VERSION ""

NS_ :

BS_:

BU_: EBS EMS

BO_ 3221225472 VECTOR__INDEPENDENT_SIG_MSG: 0 Vector__XXX
 SG_ RedStopLampState : 0|2@1+ (1,0) [0|3] "" Vector__XXX
 SG_ AmberWarningLampStatus : 0|2@1+ (1,0) [0|3] "" Vector__XXX
 SG_ ProtectLampStatus : 0|2@1+ (1,0) [0|3] "" Vector__XXX
 SG_ DTC5 : 0|32@1+ (1,0) [0|4294967295] "" Vector__XXX
 SG_ DTC4 : 0|32@1+ (1,0) [0|4294967295] "" Vector__XXX
 SG_ DTC3 : 0|32@1+ (1,0) [0|4294967295] "" Vector__XXX
 SG_ DTC2 : 0|32@1+ (1,0) [0|4294967295] "" Vector__XXX
 SG_ UtlityOverallPowerFactorLagging : 0|2@1+ (1,0) [0|3] "" Vector__XXX
 SG_ UtilityOverallPowerFactor : 0|16@1+ (1,-1) [-1|2.92181] "" Vector__XXX
 SG_ UtilityTotalReactivePower : 0|32@1+ (1,-2000000000) [-2000000000|2211081215] "VA" Vector__XXX
 SG_ UtilityTotalApparentPower : 0|32@1+ (1,-2000000000) [-2000000000|2211081215] "VA" Vector__XXX
 SG_ UtilityTotalRealPower : 0|32@1+ (1,-2000000000) [-2000000000|2211081215] "VA" Vector__XXX
 SG_ UtilityTotalKWHoursImport : 0|32@1+ (1,0) [0|4211081215] "kWh" Vector__XXX
 SG_ UtilityTotalKWHoursExport : 0|32@1+ (1,0) [0|4211081215] "kWh" Vector__XXX
 SG_ UtilityPhaseCPowerFactorLagging : 0|2@1+ (1,0) [0|3] "" Vector__XXX
 SG_ UtilityPhaseCPowerFactor : 0|16@1+ (1,-1) [-1|2.92181] "" Vector__XXX
 SG_ UtilityPhaseCReactivePower : 0|32@1+ (1,-2000000000) [-2000000000|2211081215] "VA" Vector__XXX
 SG_ UtilityPhaseCApparentPower : 0|32@1+ (1,-2000000000) [-2000000000|2211081215] "VA" Vector__XXX
 SG_ UtilityPhaseCRealPower : 0|32@1+ (1,-2000000000) [-2000000000|2211081215] "VA" Vector__XXX
 SG_ UtilityPhaseCACRMSCurrent : 0|16@1+ (1,0) [0|64255] "A" Vector__XXX
 SG_ UtilityPhaseCACFrequency : 0|16@1+ (1,0) [0|501.9921875] "Hz" Vector__XXX
 SG_ UtltyPhsCLneNeutralACRMSVoltage : 0|16@1+ (1,0) [0|64255] "V" Vector__XXX
 SG_ UtltyPhseCALineLineACRMSVoltage : 0|16@1+ (1,0) [0|64255] "V" Vector__XXX
 SG_ UtilityPhaseBPowerFactorLagging : 0|2@1+ (1,0) [0|3] "" Vector__XXX
 SG_ UtilityPhaseBPowerFactor : 0|16@1+ (1,-1) [-1|2.92181] "" Vector__XXX
 SG_ UtilityPhaseBReactivePower : 0|32@1+ (1,-2000000000) [-2000000000|2211081215] "VA" Vector__XXX
 SG_ UtilityPhaseBApparentPower : 0|32@1+ (1,-2000000000) [-2000000000|2211081215] "VA" Vector__XXX
 SG_ UtilityPhaseBRealPower : 0|32@1+ (1,-2000000000) [-2000000000|2211081215] "VA" Vector__XXX
 SG_ UtilityPhaseBACRMSCurrent : 0|16@1+ (1,0) [0|64255] "A" Vector__XXX
 SG_ UtilityPhaseBACFrequency : 0|16@1+ (1,0) [0|501.9921875] "Hz" Vector__XXX
 SG_ UtltyPhsBLneNeutralACRMSVoltage : 0|16@1+ (1,0) [0|64255] "V" Vector__XXX
 SG_ UtltyPhseBCLineLineACRMSVoltage : 0|16@1+ (1,0) [0|64255] "V" Vector__XXX
 SG_ UtilityPhaseAPowerFactorLagging : 0|2@1+ (1,0) [0|3] "" Vector__XXX
 SG_ UtilityPhaseAPowerFactor : 0|16@1+ (1,-1) [-1|2.92181] "" Vector__XXX
 SG_ UtilityPhaseAReactivePower : 0|32@1+ (1,-2000000000) [-2000000000|2211081215] "VA" Vector__XXX
 SG_ UtilityPhaseAApparentPower : 0|32@1+ (1,-2000000000) [-2000000000|2211081215] "VA" Vector__XXX
 SG_ UtilityPhaseARealPower : 0|32@1+ (1,-2000000000) [-2000000000|2211081215] "VA" Vector__XXX
 SG_ UtilityPhaseAACRMSCurrent : 0|16@1+ (1,0) [0|64255] "A" Vector__XXX
 SG_ UtilityPhaseAACFrequency : 0|16@1+ (1,0) [0|501.9921875] "Hz" Vector__XXX
 SG_ UtltyPhsALneNeutralACRMSVoltage : 0|16@1+ (1,0) [0|64255] "V" Vector__XXX
 SG_ UtltyPhseABLineLineACRMSVoltage : 0|16@1+ (1,0) [0|64255] "V" Vector__XXX
 SG_ UtilityAverageACRMSCurrent : 0|16@1+ (1,0) [0|64255] "A" Vector__XXX
 SG_ UtilityAverageACFrequency : 0|16@1+ (1,0) [0|501.9921875] "Hz" Vector__XXX
 SG_ UtltyAvrgLneNeutralACRMSVoltage : 0|16@1+ (1,0) [0|64255] "V" Vector__XXX
 SG_ UtltyAvrageLineLineACRMSVoltage : 0|16@1+ (1,0) [0|64255] "V" Vector__XXX
 SG_ GnrtorOverallPowerFactorLagging : 0|2@1+ (1,0) [0|3] "" Vector__XXX
 SG_ GeneratorOverallPowerFactor : 0|16@1+ (1,-1) [-1|2.92181] "" Vector__XXX
 SG_ GeneratorTotalReactivePower : 0|32@1+ (1,-2000000000) [-2000000000|2211081215] "VA" Vector__XXX
 SG_ GeneratorTotalApparentPower : 0|32@1+ (1,-2000000000) [-2000000000|2211081215] "VA" Vector__XXX
 SG_ GeneratorTotalRealPower : 0|32@1+ (1,-2000000000) [-2000000000|2211081215] "VA" Vector__XXX
 SG_ GeneratorTotalKWHoursImport : 0|32@1+ (1,0) [0|4211081215] "kWh" Vector__XXX
 SG_ GeneratorTotalKWHoursExport : 0|32@1+ (1,0) [0|4211081215] "kWh" Vector__XXX
 SG_ GnratorPhaseCPowerFactorLagging : 0|2@1+ (1,0) [0|3] "" Vector__XXX
 SG_ GeneratorPhaseCPowerFactor : 0|16@1+ (1,-1) [-1|2.92181] "" Vector__XXX
 SG_ GeneratorPhaseCReactivePower : 0|32@1+ (1,-2000000000) [-2000000000|2211081215] "VA" Vector__XXX
 SG_ GeneratorPhaseCApparentPower : 0|32@1+ (1,-2000000000) [-2000000000|2211081215] "VA" Vector__XXX
 SG_ GeneratorPhaseCRealPower : 0|32@1+ (1,-2000000000) [-2000000000|2211081215] "VA" Vector__XXX
 SG_ GeneratorPhaseCACRMSCurrent : 0|16@1+ (1,0) [0|64255] "A" Vector__XXX
 SG_ GeneratorPhaseCACFrequency : 0|16@1+ (1,0) [0|501.9921875] "Hz" Vector__XXX
 SG_ GnrtrPhsCLneNeutralACRMSVoltage : 0|16@1+ (1,0) [0|64255] "V" Vector__XXX
 SG_ GnrtrPhseCALineLineACRMSVoltage : 0|16@1+ (1,0) [0|64255] "V" Vector__XXX
 SG_ GnratorPhaseBPowerFactorLagging : 0|2@1+ (1,0) [0|3] "" Vector__XXX
 SG_ GeneratorPhaseBPowerFactor : 0|16@1+ (1,-1) [-1|2.92181] "" Vector__XXX
 SG_ GeneratorPhaseBReactivePower : 0|32@1+ (1,-2000000000) [-2000000000|2211081215] "VA" Vector__XXX
 SG_ GeneratorPhaseBApparentPower : 0|32@1+ (1,-2000000000) [-2000000000|2211081215] "VA" Vector__XXX
 SG_ GeneratorPhaseBRealPower : 0|32@1+ (1,-2000000000) [-2000000000|2211081215] "VA" Vector__XXX
 SG_ GeneratorPhaseBACRMSCurrent : 0|16@1+ (1,0) [0|64255] "A" Vector__XXX
 SG_ GeneratorPhaseBACFrequency : 0|16@1+ (1,0) [0|501.9921875] "Hz" Vector__XXX
 SG_ GnrtrPhsBLneNeutralACRMSVoltage : 0|16@1+ (1,0) [0|64255] "V" Vector__XXX
 SG_ GnrtrPhseBCLineLineACRMSVoltage : 0|16@1+ (1,0) [0|64255] "V" Vector__XXX
 SG_ GnratorPhaseAPowerFactorLagging : 0|2@1+ (1,0) [0|3] "" Vector__XXX
 SG_ GeneratorPhaseAPowerFactor : 0|16@1+ (1,-1) [-1|2.92181] "" Vector__XXX
 SG_ GeneratorPhaseAReactivePower : 0|32@1+ (1,-2000000000) [-2000000000|2211081215] "VA" Vector__XXX
 SG_ GeneratorPhaseAApparentPower : 0|32@1+ (1,-2000000000) [-2000000000|2211081215] "VA" Vector__XXX
 SG_ GeneratorPhaseARealPower : 0|32@1+ (1,-2000000000) [-2000000000|2211081215] "VA" Vector__XXX
 SG_ GeneratorPhaseAACRMSCurrent : 0|16@1+ (1,0) [0|64255] "A" Vector__XXX
 SG_ GeneratorPhaseAACFrequency : 0|16@1+ (1,0) [0|501.9921875] "Hz" Vector__XXX
 SG_ GnrtrPhsALneNeutralACRMSVoltage : 0|16@1+ (1,0) [0|64255] "V" Vector__XXX
 SG_ GnrtrPhseABLineLineACRMSVoltage : 0|16@1+ (1,0) [0|64255] "V" Vector__XXX
 SG_ GeneratorAverageACRMSCurrent : 0|16@1+ (1,0) [0|64255] "A" Vector__XXX
 SG_ GeneratorAverageACFrequency : 0|16@1+ (1,0) [0|501.9921875] "Hz" Vector__XXX
 SG_ GnrtrAvrgLneNeutralACRMSVoltage : 0|16@1+ (1,0) [0|64255] "V" Vector__XXX
 SG_ GnrtrAvrageLineLineACRMSVoltage : 0|16@1+ (1,0) [0|64255] "V" Vector__XXX
 SG_ Bus1_UtilityACPhaseDifference : 0|16@1+ (1,-200) [-200|301.99] "deg" Vector__XXX
 SG_ Bus1_UtilityInSync : 0|2@1+ (1,0) [0|3] "" Vector__XXX
 SG_ Bus1_UtilityVoltageMatch : 0|2@1+ (1,0) [0|3] "" Vector__XXX
 SG_ Bus1_UtilityFrequencyMatch : 0|2@1+ (1,0) [0|3] "" Vector__XXX
 SG_ Bus1_UtilityPhaseMatch : 0|2@1+ (1,0) [0|3] "" Vector__XXX
 SG_ Bus1_UtilityDeadBus : 0|2@1+ (1,0) [0|3] "" Vector__XXX
 SG_ Bus1PhaseCACFrequency : 0|16@1+ (1,0) [0|501.9921875] "Hz" Vector__XXX
 SG_ Bs1PhseCLineNeutralACRMSVoltage : 0|16@1+ (1,0) [0|64255] "V" Vector__XXX
 SG_ Bus1PhaseCALineLineACRMSVoltage : 0|16@1+ (1,0) [0|64255] "V" Vector__XXX
 SG_ Bus1PhaseBACFrequency : 0|16@1+ (1,0) [0|501.9921875] "Hz" Vector__XXX
 SG_ Bs1PhseBLineNeutralACRMSVoltage : 0|16@1+ (1,0) [0|64255] "V" Vector__XXX
 SG_ Bus1PhaseBCLineLineACRMSVoltage : 0|16@1+ (1,0) [0|64255] "V" Vector__XXX
 SG_ Bus1PhaseAACFrequency : 0|16@1+ (1,0) [0|501.9921875] "Hz" Vector__XXX
 SG_ Bs1PhseALineNeutralACRMSVoltage : 0|16@1+ (1,0) [0|64255] "V" Vector__XXX
 SG_ Bus1PhaseABLineLineACRMSVoltage : 0|16@1+ (1,0) [0|64255] "V" Vector__XXX
 SG_ Bus1_GeneratorACPhaseDifference : 0|16@1+ (1,-200) [-200|301.99] "deg" Vector__XXX
 SG_ Bus1_GeneratorInSync : 0|2@1+ (1,0) [0|3] "" Vector__XXX
 SG_ Bus1_GeneratorVoltageMatch : 0|2@1+ (1,0) [0|3] "" Vector__XXX
 SG_ Bus1_GeneratorFrequencyMatch : 0|2@1+ (1,0) [0|3] "" Vector__XXX
 SG_ Bus1_GeneratorPhaseMatch : 0|2@1+ (1,0) [0|3] "" Vector__XXX
 SG_ Bus1_GeneratorDeadBus : 0|2@1+ (1,0) [0|3] "" Vector__XXX
 SG_ Bus1AverageACFrequency : 0|16@1+ (1,0) [0|501.9921875] "Hz" Vector__XXX
 SG_ Bs1AvrgeLineNeutralACRMSVoltage : 0|16@1+ (1,0) [0|64255] "V" Vector__XXX
 SG_ Bus1AverageLineLineACRMSVoltage : 0|16@1+ (1,0) [0|64255] "V" Vector__XXX
 SG_ NumberOfMembers : 0|8@1+ (1,0) [0|0] "" Vector__XXX
 SG_ AddressAssignment : 0|8@1+ (1,0) [0|255] "" Vector__XXX
 SG_ ArbitraryAddressCapable : 0|1@1+ (1,0) [0|1] "" Vector__XXX
 SG_ IndustryGroup : 0|3@1+ (1,0) [0|7] "" Vector__XXX
 SG_ VehicleSystemInstance : 0|4@1+ (1,0) [0|15] "" Vector__XXX
 SG_ Function : 0|8@1+ (1,0) [0|255] "" Vector__XXX
 SG_ VehicleSystem : 0|7@1+ (1,0) [0|127] "" Vector__XXX
 SG_ FunctionInstance : 0|5@1+ (1,0) [0|31] "" Vector__XXX
 SG_ ECUInstance : 0|3@1+ (1,0) [0|7] "" Vector__XXX
 SG_ ManufacturerCode : 0|11@1+ (1,0) [0|2047] "" Vector__XXX
 SG_ IdentityNumber : 0|21@1+ (1,0) [0|2097152] "" Vector__XXX
 SG_ VehicleSystem5 : 0|7@1+ (1,0) [0|127] "" Vector__XXX
 SG_ VehicleSystem4 : 0|7@1+ (1,0) [0|127] "" Vector__XXX
 SG_ VehicleSystem3 : 0|7@1+ (1,0) [0|127] "" Vector__XXX
 SG_ VehicleSystem2 : 0|7@1+ (1,0) [0|127] "" Vector__XXX
 SG_ VehicleSystem1 : 0|7@1+ (1,0) [0|127] "" Vector__XXX
 SG_ AxleGroupWeight : 0|16@1+ (2,0) [0|128510] "kg" Vector__XXX
 SG_ AxleGroupLocation : 0|4@1+ (1,0) [0|15] "" Vector__XXX
 SG_ AxleGroupFullWeightCalib : 0|16@1+ (2,0) [0|128510] "kg" Vector__XXX
 SG_ AxleGroupEmptyWeightCalib : 0|16@1+ (2,0) [0|128510] "kg" Vector__XXX
 SG_ AxleGroupLocation : 0|4@1+ (1,0) [0|15] "" Vector__XXX
 SG_ DsrdAftrclrClntThrmostatOpening : 0|8@1+ (0.4,0) [0|100] "%" Vector__XXX
 SG_ DsrdAftercoolerCoolantInletTemp : 0|8@1+ (1,-40) [-40|210] "deg" Vector__XXX
 SG_ AftrcoolerCoolantThermostatMode : 0|2@1+ (1,0) [0|3] "" Vector__XXX
 SG_ AddtnlTrlrAxlGrpWeightAvailable : 0|2@1+ (1,0) [0|3] "" Vector__XXX
 SG_ TrilerHAxleGroupWeightAvailable : 0|2@1+ (1,0) [0|3] "" Vector__XXX
 SG_ TrilerGAxleGroupWeightAvailable : 0|2@1+ (1,0) [0|3] "" Vector__XXX
 SG_ TrilerFAxleGroupWeightAvailable : 0|2@1+ (1,0) [0|3] "" Vector__XXX
 SG_ TrilerEAxleGroupWeightAvailable : 0|2@1+ (1,0) [0|3] "" Vector__XXX
 SG_ TrilerDAxleGroupWeightAvailable : 0|2@1+ (1,0) [0|3] "" Vector__XXX
 SG_ TrilerCAxleGroupWeightAvailable : 0|2@1+ (1,0) [0|3] "" Vector__XXX
 SG_ TrilerBAxleGroupWeightAvailable : 0|2@1+ (1,0) [0|3] "" Vector__XXX
 SG_ TrilerAAxleGroupWeightAvailable : 0|2@1+ (1,0) [0|3] "" Vector__XXX
 SG_ AddtnlTrctrAxlGrpWightAvailable : 0|2@1+ (1,0) [0|3] "" Vector__XXX
 SG_ TagAxleGroupWeightAvailable : 0|2@1+ (1,0) [0|3] "" Vector__XXX
 SG_ DriveAxleGroupWeightAvailable : 0|2@1+ (1,0) [0|3] "" Vector__XXX
 SG_ LiftAxleGroupWeightAvailable : 0|2@1+ (1,0) [0|3] "" Vector__XXX
 SG_ SteerAxleGroupWeightAvailable : 0|2@1+ (1,0) [0|3] "" Vector__XXX
 SG_ AmberWarningLampStatus : 0|2@1+ (1,0) [0|3] "" Vector__XXX
 SG_ RedStopLampState : 0|2@1+ (1,0) [0|3] "" Vector__XXX
 SG_ ProtectLampStatus : 0|2@1+ (1,0) [0|3] "" Vector__XXX
 SG_ DTC5 : 0|32@1+ (1,0) [0|4294967295] "" Vector__XXX
 SG_ DTC4 : 0|32@1+ (1,0) [0|4294967295] "" Vector__XXX
 SG_ DTC3 : 0|32@1+ (1,0) [0|4294967295] "" Vector__XXX
 SG_ DTC2 : 0|32@1+ (1,0) [0|4294967295] "" Vector__XXX
 SG_ AmberWarningLampStatus : 0|2@1+ (1,0) [0|3] "" Vector__XXX
 SG_ RedStopLampState : 0|2@1+ (1,0) [0|3] "" Vector__XXX
 SG_ ProtectLampStatus : 0|2@1+ (1,0) [0|3] "" Vector__XXX
 SG_ DTC5 : 0|32@1+ (1,0) [0|4294967295] "" Vector__XXX
 SG_ DTC4 : 0|32@1+ (1,0) [0|4294967295] "" Vector__XXX
 SG_ DTC3 : 0|32@1+ (1,0) [0|4294967295] "" Vector__XXX
 SG_ DTC2 : 0|32@1+ (1,0) [0|4294967295] "" Vector__XXX
 SG_ AmberWarningLampStatus : 0|2@1+ (1,0) [0|3] "" Vector__XXX
 SG_ RedStopLampState : 0|2@1+ (1,0) [0|3] "" Vector__XXX
 SG_ ProtectLampStatus : 0|2@1+ (1,0) [0|3] "" Vector__XXX
 SG_ DTC5 : 0|32@1+ (1,0) [0|4294967295] "" Vector__XXX
 SG_ DTC4 : 0|32@1+ (1,0) [0|4294967295] "" Vector__XXX
 SG_ DTC3 : 0|32@1+ (1,0) [0|4294967295] "" Vector__XXX
 SG_ DTC2 : 0|32@1+ (1,0) [0|4294967295] "" Vector__XXX
 SG_ AmberWarningLampStatus : 0|2@1+ (1,0) [0|3] "" Vector__XXX
 SG_ RedStopLampState : 0|2@1+ (1,0) [0|3] "" Vector__XXX
 SG_ ProtectLampStatus : 0|2@1+ (1,0) [0|3] "" Vector__XXX
 SG_ DTC5 : 0|32@1+ (1,0) [0|4294967295] "" Vector__XXX
 SG_ DTC4 : 0|32@1+ (1,0) [0|4294967295] "" Vector__XXX
 SG_ DTC3 : 0|32@1+ (1,0) [0|4294967295] "" Vector__XXX
 SG_ DTC2 : 0|32@1+ (1,0) [0|4294967295] "" Vector__XXX
 SG_ AmberWarningLampStatus : 0|2@1+ (1,0) [0|3] "" Vector__XXX
 SG_ RedStopLampState : 0|2@1+ (1,0) [0|3] "" Vector__XXX
 SG_ ProtectLampStatus : 0|2@1+ (1,0) [0|3] "" Vector__XXX
 SG_ DTC5 : 0|32@1+ (1,0) [0|4294967295] "" Vector__XXX
 SG_ DTC4 : 0|32@1+ (1,0) [0|4294967295] "" Vector__XXX
 SG_ DTC3 : 0|32@1+ (1,0) [0|4294967295] "" Vector__XXX
 SG_ DTC2 : 0|32@1+ (1,0) [0|4294967295] "" Vector__XXX
 SG_ AmberWarningLampStatus : 0|2@1+ (1,0) [0|3] "" Vector__XXX
 SG_ RedStopLampState : 0|2@1+ (1,0) [0|3] "" Vector__XXX
 SG_ ProtectLampStatus : 0|2@1+ (1,0) [0|3] "" Vector__XXX
 SG_ DTC5 : 0|32@1+ (1,0) [0|4294967295] "" Vector__XXX
 SG_ DTC4 : 0|32@1+ (1,0) [0|4294967295] "" Vector__XXX
 SG_ DTC3 : 0|32@1+ (1,0) [0|4294967295] "" Vector__XXX
 SG_ DTC2 : 0|32@1+ (1,0) [0|4294967295] "" Vector__XXX
 SG_ AmberWarningLampStatus : 0|2@1+ (1,0) [0|3] "" Vector__XXX
 SG_ RedStopLampState : 0|2@1+ (1,0) [0|3] "" Vector__XXX
 SG_ ProtectLampStatus : 0|2@1+ (1,0) [0|3] "" Vector__XXX
 SG_ DTC5 : 0|32@1+ (1,0) [0|4294967295] "" Vector__XXX
 SG_ DTC4 : 0|32@1+ (1,0) [0|4294967295] "" Vector__XXX
 SG_ DTC3 : 0|32@1+ (1,0) [0|4294967295] "" Vector__XXX
 SG_ DTC2 : 0|32@1+ (1,0) [0|4294967295] "" Vector__XXX
 SG_ AmberWarningLampStatus : 0|2@1+ (1,0) [0|3] "" Vector__XXX
 SG_ RedStopLampState : 0|2@1+ (1,0) [0|3] "" Vector__XXX
 SG_ ProtectLampStatus : 0|2@1+ (1,0) [0|3] "" Vector__XXX
 SG_ DTC5 : 0|32@1+ (1,0) [0|4294967295] "" Vector__XXX
 SG_ DTC4 : 0|32@1+ (1,0) [0|4294967295] "" Vector__XXX
 SG_ DTC3 : 0|32@1+ (1,0) [0|4294967295] "" Vector__XXX
 SG_ DTC2 : 0|32@1+ (1,0) [0|4294967295] "" Vector__XXX
 SG_ AmberWarningLampStatus : 0|2@1+ (1,0) [0|3] "" Vector__XXX
 SG_ RedStopLampState : 0|2@1+ (1,0) [0|3] "" Vector__XXX
 SG_ ProtectLampStatus : 0|2@1+ (1,0) [0|3] "" Vector__XXX
 SG_ DTC5 : 0|32@1+ (1,0) [0|4294967295] "" Vector__XXX
 SG_ DTC4 : 0|32@1+ (1,0) [0|4294967295] "" Vector__XXX
 SG_ DTC3 : 0|32@1+ (1,0) [0|4294967295] "" Vector__XXX
 SG_ DTC2 : 0|32@1+ (1,0) [0|4294967295] "" Vector__XXX
 SG_ AmberWarningLampStatus : 0|2@1+ (1,0) [0|3] "" Vector__XXX
 SG_ RedStopLampState : 0|2@1+ (1,0) [0|3] "" Vector__XXX
 SG_ ProtectLampStatus : 0|2@1+ (1,0) [0|3] "" Vector__XXX
 SG_ DTC5 : 0|32@1+ (1,0) [0|4294967295] "" Vector__XXX
 SG_ DTC4 : 0|32@1+ (1,0) [0|4294967295] "" Vector__XXX
 SG_ DTC3 : 0|32@1+ (1,0) [0|4294967295] "" Vector__XXX
 SG_ DTC2 : 0|32@1+ (1,0) [0|4294967295] "" Vector__XXX
 SG_ AmberWarningLampStatus : 0|2@1+ (1,0) [0|3] "" Vector__XXX
 SG_ RedStopLampState : 0|2@1+ (1,0) [0|3] "" Vector__XXX
 SG_ ProtectLampStatus : 0|2@1+ (1,0) [0|3] "" Vector__XXX
 SG_ DTC5 : 0|32@1+ (1,0) [0|4294967295] "" Vector__XXX
 SG_ DTC4 : 0|32@1+ (1,0) [0|4294967295] "" Vector__XXX
 SG_ DTC3 : 0|32@1+ (1,0) [0|4294967295] "" Vector__XXX
 SG_ DTC2 : 0|32@1+ (1,0) [0|4294967295] "" Vector__XXX
 SG_ AmberWarningLampStatus : 0|2@1+ (1,0) [0|3] "" Vector__XXX
 SG_ RedStopLampState : 0|2@1+ (1,0) [0|3] "" Vector__XXX
 SG_ ProtectLampStatus : 0|2@1+ (1,0) [0|3] "" Vector__XXX
 SG_ DTC5 : 0|32@1+ (1,0) [0|4294967295] "" Vector__XXX
 SG_ DTC4 : 0|32@1+ (1,0) [0|4294967295] "" Vector__XXX
 SG_ DTC3 : 0|32@1+ (1,0) [0|4294967295] "" Vector__XXX
 SG_ DTC2 : 0|32@1+ (1,0) [0|4294967295] "" Vector__XXX
 SG_ AmberWarningLampStatus : 0|2@1+ (1,0) [0|3] "" Vector__XXX
 SG_ RedStopLampState : 0|2@1+ (1,0) [0|3] "" Vector__XXX
 SG_ ProtectLampStatus : 0|2@1+ (1,0) [0|3] "" Vector__XXX
 SG_ DTC5 : 0|32@1+ (1,0) [0|4294967295] "" Vector__XXX
 SG_ DTC4 : 0|32@1+ (1,0) [0|4294967295] "" Vector__XXX
 SG_ DTC3 : 0|32@1+ (1,0) [0|4294967295] "" Vector__XXX
 SG_ DTC2 : 0|32@1+ (1,0) [0|4294967295] "" Vector__XXX
 SG_ ZeroNetVehicleWeightChange : 0|2@1+ (1,0) [0|3] "" Vector__XXX
 SG_ EngineExhaustGasTempAvrBank1 : 0|16@1+ (0.03125,-273) [-273|1785] "°C" Vector__XXX
 SG_ EngineExhaustGasTempAvrBank2 : 0|16@1- (0.03125,-273) [-273|1785] "°C" Vector__XXX
 SG_ EngExhaustGasTempAvrg : 0|16@1+ (0.03125,-273) [-273|1785] "°C" Vector__XXX
 SG_ AmberWarningLampStatus : 0|2@1+ (1,0) [0|3] "" Vector__XXX
 SG_ RedStopLampState : 0|2@1+ (1,0) [0|3] "" Vector__XXX
 SG_ ProtectLampStatus : 0|2@1+ (1,0) [0|3] "" Vector__XXX
 SG_ DTC5 : 0|32@1+ (1,0) [0|4294967295] "" Vector__XXX
 SG_ DTC4 : 0|32@1+ (1,0) [0|4294967295] "" Vector__XXX
 SG_ DTC3 : 0|32@1+ (1,0) [0|4294967295] "" Vector__XXX
 SG_ DTC2 : 0|32@1+ (1,0) [0|4294967295] "" Vector__XXX
 SG_ AmberWarningLampStatus : 0|2@1+ (1,0) [0|3] "" Vector__XXX
 SG_ RedStopLampState : 0|2@1+ (1,0) [0|3] "" Vector__XXX
 SG_ ProtectLampStatus : 0|2@1+ (1,0) [0|3] "" Vector__XXX
 SG_ DTC5 : 0|32@1+ (1,0) [0|4294967295] "" Vector__XXX
 SG_ DTC4 : 0|32@1+ (1,0) [0|4294967295] "" Vector__XXX
 SG_ DTC3 : 0|32@1+ (1,0) [0|4294967295] "" Vector__XXX
 SG_ DTC2 : 0|32@1+ (1,0) [0|4294967295] "" Vector__XXX
 SG_ NumberOfAETCDataPoints : 0|4@1+ (1,0) [0|15] "" Vector__XXX
 SG_ AETCDataCollectionStandard : 0|4@1+ (1,0) [0|15] "" Vector__XXX
 SG_ RightHeadlampLightDistribution : 0|4@1+ (1,0) [0|15] "" Vector__XXX
 SG_ LeftHeadlampLightDistribution : 0|4@1+ (1,0) [0|15] "" Vector__XXX
 SG_ RghtHeadlampDynamicBendingLight : 0|3@1+ (1,0) [0|7] "" Vector__XXX
 SG_ LeftHeadlampDynamicBendingLight : 0|3@1+ (1,0) [0|7] "" Vector__XXX
 SG_ AuxI_OChannel2 : 0|16@1+ (1,0) [0|64255] "counts" Vector__XXX
 SG_ AuxI_OChannel1 : 0|16@1+ (1,0) [0|64255] "counts" Vector__XXX
 SG_ AuxI_O45 : 0|2@1+ (1,0) [0|3] "" Vector__XXX
 SG_ AuxI_O46 : 0|2@1+ (1,0) [0|3] "" Vector__XXX
 SG_ AuxI_O47 : 0|2@1+ (1,0) [0|3] "" Vector__XXX
 SG_ AuxI_O48 : 0|2@1+ (1,0) [0|3] "" Vector__XXX
 SG_ AuxI_O41 : 0|2@1+ (1,0) [0|3] "" Vector__XXX
 SG_ AuxI_O42 : 0|2@1+ (1,0) [0|3] "" Vector__XXX
 SG_ AuxI_O43 : 0|2@1+ (1,0) [0|3] "" Vector__XXX
 SG_ AuxI_O44 : 0|2@1+ (1,0) [0|3] "" Vector__XXX
 SG_ AuxI_O37 : 0|2@1+ (1,0) [0|3] "" Vector__XXX
 SG_ AuxI_O38 : 0|2@1+ (1,0) [0|3] "" Vector__XXX
 SG_ AuxI_O39 : 0|2@1+ (1,0) [0|3] "" Vector__XXX
 SG_ AuxI_O40 : 0|2@1+ (1,0) [0|3] "" Vector__XXX
 SG_ AuxI_O33 : 0|2@1+ (1,0) [0|3] "" Vector__XXX
 SG_ AuxI_O34 : 0|2@1+ (1,0) [0|3] "" Vector__XXX
 SG_ AuxI_O35 : 0|2@1+ (1,0) [0|3] "" Vector__XXX
 SG_ AuxI_O36 : 0|2@1+ (1,0) [0|3] "" Vector__XXX
 SG_ AuxI_O29 : 0|2@1+ (1,0) [0|3] "" Vector__XXX
 SG_ AuxI_O30 : 0|2@1+ (1,0) [0|3] "" Vector__XXX
 SG_ AuxI_O31 : 0|2@1+ (1,0) [0|3] "" Vector__XXX
 SG_ AuxI_O32 : 0|2@1+ (1,0) [0|3] "" Vector__XXX
 SG_ AuxI_O25 : 0|2@1+ (1,0) [0|3] "" Vector__XXX
 SG_ AuxI_O26 : 0|2@1+ (1,0) [0|3] "" Vector__XXX
 SG_ AuxI_O27 : 0|2@1+ (1,0) [0|3] "" Vector__XXX
 SG_ AuxI_O28 : 0|2@1+ (1,0) [0|3] "" Vector__XXX
 SG_ AuxI_O21 : 0|2@1+ (1,0) [0|3] "" Vector__XXX
 SG_ AuxI_O22 : 0|2@1+ (1,0) [0|3] "" Vector__XXX
 SG_ AuxI_O23 : 0|2@1+ (1,0) [0|3] "" Vector__XXX
 SG_ AuxI_O24 : 0|2@1+ (1,0) [0|3] "" Vector__XXX
 SG_ AuxI_O17 : 0|2@1+ (1,0) [0|3] "" Vector__XXX
 SG_ AuxI_O18 : 0|2@1+ (1,0) [0|3] "" Vector__XXX
 SG_ AuxI_O19 : 0|2@1+ (1,0) [0|3] "" Vector__XXX
 SG_ AuxI_O20 : 0|2@1+ (1,0) [0|3] "" Vector__XXX
 SG_ AuxI_O77 : 0|2@1+ (1,0) [0|3] "" Vector__XXX
 SG_ AuxI_O78 : 0|2@1+ (1,0) [0|3] "" Vector__XXX
 SG_ AuxI_O79 : 0|2@1+ (1,0) [0|3] "" Vector__XXX
 SG_ AuxI_O80 : 0|2@1+ (1,0) [0|3] "" Vector__XXX
 SG_ AuxI_O73 : 0|2@1+ (1,0) [0|3] "" Vector__XXX
 SG_ AuxI_O74 : 0|2@1+ (1,0) [0|3] "" Vector__XXX
 SG_ AuxI_O75 : 0|2@1+ (1,0) [0|3] "" Vector__XXX
 SG_ AuxI_O76 : 0|2@1+ (1,0) [0|3] "" Vector__XXX
 SG_ AuxI_O69 : 0|2@1+ (1,0) [0|3] "" Vector__XXX
 SG_ AuxI_O70 : 0|2@1+ (1,0) [0|3] "" Vector__XXX
 SG_ AuxI_O71 : 0|2@1+ (1,0) [0|3] "" Vector__XXX
 SG_ AuxI_O72 : 0|2@1+ (1,0) [0|3] "" Vector__XXX
 SG_ AuxI_O65 : 0|2@1+ (1,0) [0|3] "" Vector__XXX
 SG_ AuxI_O66 : 0|2@1+ (1,0) [0|3] "" Vector__XXX
 SG_ AuxI_O67 : 0|2@1+ (1,0) [0|3] "" Vector__XXX
 SG_ AuxI_O68 : 0|2@1+ (1,0) [0|3] "" Vector__XXX
 SG_ AuxI_O61 : 0|2@1+ (1,0) [0|3] "" Vector__XXX
 SG_ AuxI_O62 : 0|2@1+ (1,0) [0|3] "" Vector__XXX
 SG_ AuxI_O63 : 0|2@1+ (1,0) [0|3] "" Vector__XXX
 SG_ AuxI_O64 : 0|2@1+ (1,0) [0|3] "" Vector__XXX
 SG_ AuxI_O57 : 0|2@1+ (1,0) [0|3] "" Vector__XXX
 SG_ AuxI_O58 : 0|2@1+ (1,0) [0|3] "" Vector__XXX
 SG_ AuxI_O59 : 0|2@1+ (1,0) [0|3] "" Vector__XXX
 SG_ AuxI_O60 : 0|2@1+ (1,0) [0|3] "" Vector__XXX
 SG_ AuxI_O53 : 0|2@1+ (1,0) [0|3] "" Vector__XXX
 SG_ AuxI_O54 : 0|2@1+ (1,0) [0|3] "" Vector__XXX
 SG_ AuxI_O55 : 0|2@1+ (1,0) [0|3] "" Vector__XXX
 SG_ AuxI_O56 : 0|2@1+ (1,0) [0|3] "" Vector__XXX
 SG_ AuxI_O49 : 0|2@1+ (1,0) [0|3] "" Vector__XXX
 SG_ AuxI_O50 : 0|2@1+ (1,0) [0|3] "" Vector__XXX
 SG_ AuxI_O51 : 0|2@1+ (1,0) [0|3] "" Vector__XXX
 SG_ AuxI_O52 : 0|2@1+ (1,0) [0|3] "" Vector__XXX
 SG_ AuxI_O92 : 0|2@1+ (1,0) [0|3] "" Vector__XXX
 SG_ AuxI_O85 : 0|2@1+ (1,0) [0|3] "" Vector__XXX
 SG_ AuxI_O86 : 0|2@1+ (1,0) [0|3] "" Vector__XXX
 SG_ AuxI_O87 : 0|2@1+ (1,0) [0|3] "" Vector__XXX
 SG_ AuxI_O88 : 0|2@1+ (1,0) [0|3] "" Vector__XXX
 SG_ AuxI_O81 : 0|2@1+ (1,0) [0|3] "" Vector__XXX
 SG_ AuxI_O82 : 0|2@1+ (1,0) [0|3] "" Vector__XXX
 SG_ AuxI_O83 : 0|2@1+ (1,0) [0|3] "" Vector__XXX
 SG_ AuxI_O84 : 0|2@1+ (1,0) [0|3] "" Vector__XXX
 SG_ AuxI_O109 : 0|2@1+ (1,0) [0|3] "" Vector__XXX
 SG_ AuxI_O110 : 0|2@1+ (1,0) [0|3] "" Vector__XXX
 SG_ AuxI_O111 : 0|2@1+ (1,0) [0|3] "" Vector__XXX
 SG_ AuxI_O112 : 0|2@1+ (1,0) [0|3] "" Vector__XXX
 SG_ AuxI_O105 : 0|2@1+ (1,0) [0|3] "" Vector__XXX
 SG_ AuxI_O106 : 0|2@1+ (1,0) [0|3] "" Vector__XXX
 SG_ AuxI_O107 : 0|2@1+ (1,0) [0|3] "" Vector__XXX
 SG_ AuxI_O108 : 0|2@1+ (1,0) [0|3] "" Vector__XXX
 SG_ AuxI_O101 : 0|2@1+ (1,0) [0|3] "" Vector__XXX
 SG_ AuxI_O102 : 0|2@1+ (1,0) [0|3] "" Vector__XXX
 SG_ AuxI_O103 : 0|2@1+ (1,0) [0|3] "" Vector__XXX
 SG_ AuxI_O104 : 0|2@1+ (1,0) [0|3] "" Vector__XXX
 SG_ AuxI_O97 : 0|2@1+ (1,0) [0|3] "" Vector__XXX
 SG_ AuxI_O98 : 0|2@1+ (1,0) [0|3] "" Vector__XXX
 SG_ AuxI_O99 : 0|2@1+ (1,0) [0|3] "" Vector__XXX
 SG_ AuxI_O100 : 0|2@1+ (1,0) [0|3] "" Vector__XXX
 SG_ AuxI_O93 : 0|2@1+ (1,0) [0|3] "" Vector__XXX
 SG_ AuxI_O94 : 0|2@1+ (1,0) [0|3] "" Vector__XXX
 SG_ AuxI_O95 : 0|2@1+ (1,0) [0|3] "" Vector__XXX
 SG_ AuxI_O96 : 0|2@1+ (1,0) [0|3] "" Vector__XXX
 SG_ AuxI_O89 : 0|2@1+ (1,0) [0|3] "" Vector__XXX
 SG_ AuxI_O90 : 0|2@1+ (1,0) [0|3] "" Vector__XXX
 SG_ AuxI_O91 : 0|2@1+ (1,0) [0|3] "" Vector__XXX
 SG_ TrailerBrakeStrokeAxle5Right : 0|3@1+ (1,0) [0|7] "" Vector__XXX
 SG_ TrailerBrakeStrokeAxle5Left : 0|3@1+ (1,0) [0|7] "" Vector__XXX
 SG_ TrailerBrakeStrokeAxle4Right : 0|3@1+ (1,0) [0|7] "" Vector__XXX
 SG_ TrailerBrakeStrokeAxle4Left : 0|3@1+ (1,0) [0|7] "" Vector__XXX
 SG_ TrailerBrakeStrokeAxle3Right : 0|3@1+ (1,0) [0|7] "" Vector__XXX
 SG_ TrailerBrakeStrokeAxle3Left : 0|3@1+ (1,0) [0|7] "" Vector__XXX
 SG_ TrailerBrakeStrokeAxle2Right : 0|3@1+ (1,0) [0|7] "" Vector__XXX
 SG_ TrailerBrakeStrokeAxle2Left : 0|3@1+ (1,0) [0|7] "" Vector__XXX
 SG_ TrailerBrakeStrokeAxle1Right : 0|3@1+ (1,0) [0|7] "" Vector__XXX
 SG_ TrailerBrakeStrokeAxle1Left : 0|3@1+ (1,0) [0|7] "" Vector__XXX
 SG_ TractorBrakeStrokeAxle5Right : 0|3@1+ (1,0) [0|7] "" Vector__XXX
 SG_ TractorBrakeStrokeAxle5Left : 0|3@1+ (1,0) [0|7] "" Vector__XXX
 SG_ TractorBrakeStrokeAxle4Right : 0|3@1+ (1,0) [0|7] "" Vector__XXX
 SG_ TractorBrakeStrokeAxle4Left : 0|3@1+ (1,0) [0|7] "" Vector__XXX
 SG_ TractorBrakeStrokeAxle3Right : 0|3@1+ (1,0) [0|7] "" Vector__XXX
 SG_ TractorBrakeStrokeAxle3Left : 0|3@1+ (1,0) [0|7] "" Vector__XXX
 SG_ TractorBrakeStrokeAxle2Right : 0|3@1+ (1,0) [0|7] "" Vector__XXX
 SG_ TractorBrakeStrokeAxle2Left : 0|3@1+ (1,0) [0|7] "" Vector__XXX
 SG_ TractorBrakeStrokeAxle1Right : 0|3@1+ (1,0) [0|7] "" Vector__XXX
 SG_ TractorBrakeStrokeAxle1Left : 0|3@1+ (1,0) [0|7] "" Vector__XXX
 SG_ RoadSurfaceTemp : 0|16@1+ (0.03125,-273) [-273|1735] "°C" Vector__XXX
 SG_ EngAirInletTemp : 0|8@1+ (1,-40) [-40|210] "°C" Vector__XXX
 SG_ AmbientAirTemp : 0|16@1+ (0.03125,-273) [-273|1735] "°C" Vector__XXX
 SG_ CabInteriorTemp : 0|16@1+ (0.03125,-273) [-273|1735] "°C" Vector__XXX
 SG_ BarometricPress : 0|8@1+ (0.5,0) [0|125] "kPa" Vector__XXX
 SG_ EngAirStartPress : 0|8@1+ (4,0) [0|1000] "kPa" Vector__XXX
 SG_ AirCompressorStatus : 0|2@1+ (1,0) [0|3] "" Vector__XXX
 SG_ AirSuspensionSupplyPress : 0|8@1+ (8,0) [0|2000] "kPa" Vector__XXX
 SG_ AuxEquipmentSupplyPress : 0|8@1+ (8,0) [0|2000] "kPa" Vector__XXX
 SG_ ServiceBrakeAirPressCircuit2 : 0|8@1+ (8,0) [0|2000] "kPa" Vector__XXX
 SG_ ServiceBrakeAirPressCircuit1 : 0|8@1+ (8,0) [0|2000] "kPa" Vector__XXX
 SG_ ParkingAnd_OrTrailerAirPress : 0|8@1+ (8,0) [0|2000] "kPa" Vector__XXX
 SG_ PneumaticSupplyPress : 0|8@1+ (8,0) [0|2000] "kPa" Vector__XXX
 SG_ SteerAxleLubePress : 0|8@1+ (4,0) [0|1000] "kPa" Vector__XXX
 SG_ SteerAxleTemp : 0|8@1+ (1,-40) [-40|210] "°C" Vector__XXX
 SG_ DriveAxleLubePress : 0|8@1+ (4,0) [0|1000] "kPa" Vector__XXX
 SG_ DriveAxleTemp : 0|8@1+ (1,-40) [-40|210] "°C" Vector__XXX
 SG_ DriveAxleLiftAirPress : 0|8@1+ (4,0) [0|1000] "kPa" Vector__XXX
 SG_ DriveAxleLocation : 0|8@1+ (1,0) [0|255] "" Vector__XXX
 SG_ EngTurboWastegateValvePos : 0|8@1+ (0.4,0) [0|100] "%" Vector__XXX
 SG_ EngGsMssFlwSnsrFelingCorrection : 0|8@1+ (1,-125) [-125|125] "%" Vector__XXX
 SG_ EngDsiredAbsIntakeManifoldPress : 0|16@1+ (0.1,0) [0|6425.5] "kPa" Vector__XXX
 SG_ EngGasFuelCorrectionFactor : 0|8@1+ (1,0) [0|250] "%" Vector__XXX
 SG_ RqedACCDistanceMode : 0|3@1+ (1,0) [0|7] "" Vector__XXX
 SG_ ACCDistanceAlertSignal : 0|2@1+ (1,0) [0|3] "" Vector__XXX
 SG_ ACCSystemShutoffWarning : 0|2@1+ (1,0) [0|3] "" Vector__XXX
 SG_ ACCTargetDetected : 0|2@1+ (1,0) [0|3] "" Vector__XXX
 SG_ AdptveCruiseCtrlSetDistanceMode : 0|3@1+ (1,0) [0|7] "" Vector__XXX
 SG_ AdaptiveCruiseCtrlMode : 0|3@1+ (1,0) [0|7] "" Vector__XXX
 SG_ AdaptiveCruiseCtrlSetSpeed : 0|8@1+ (1,0) [0|250] "km/h" Vector__XXX
 SG_ DistanceToForwardVehicle : 0|8@1+ (1,0) [0|250] "m" Vector__XXX
 SG_ SpeedOfForwardVehicle : 0|8@1+ (1,0) [0|250] "km/h" Vector__XXX
 SG_ ArticulationAngle : 0|8@1+ (1,-125) [-125|125] "deg" Vector__XXX
 SG_ RelativeHumidity : 0|8@1+ (0.4,0) [0|100] "%" Vector__XXX
 SG_ AuxLevel : 0|16@1+ (0.1,0) [0|6425.5] "mm" Vector__XXX
 SG_ AuxPress2 : 0|8@1+ (16,0) [0|4000] "kPa" Vector__XXX
 SG_ AuxPress1 : 0|8@1+ (16,0) [0|4000] "kPa" Vector__XXX
 SG_ AuxTemp2 : 0|8@1+ (1,-40) [-40|210] "°C" Vector__XXX
 SG_ AuxTemp1 : 0|8@1+ (1,-40) [-40|210] "°C" Vector__XXX
 SG_ EngBlowerBypassValvePos : 0|8@1+ (0.4,0) [0|100] "%" Vector__XXX
 SG_ EngGasSupplyPress : 0|16@1+ (0.5,0) [0|32127.5] "kPa" Vector__XXX
 SG_ Status2OfDoors : 0|2@1+ (1,0) [0|3] "" Vector__XXX
 SG_ Ramp_WheelChairLiftPos : 0|2@1+ (1,0) [0|3] "" Vector__XXX
 SG_ PosOfDoors : 0|4@1+ (1,0) [0|15] "" Vector__XXX
 SG_ FifthWheelRollWarningIndicator : 0|2@1+ (1,0) [0|3] "" Vector__XXX
 SG_ FifthWheelRollMoment : 0|16@1+ (10,-320000) [-320000|322550] "N" Vector__XXX
 SG_ FifthWheelDrawbarForce : 0|16@1+ (10,-320000) [-320000|322550] "N" Vector__XXX
 SG_ FifthWheelVerticalForce : 0|16@1+ (5,0) [0|321275] "N" Vector__XXX
 SG_ FifthWheelSliderLockIndicator : 0|2@1+ (1,0) [0|3] "" Vector__XXX
 SG_ FifthWheelSliderPos : 0|8@1+ (10,0) [0|2500] "mm" Vector__XXX
 SG_ FfthWhlLckCoupleStatusIndicator : 0|2@1+ (1,0) [0|3] "" Vector__XXX
 SG_ FfthWhlLckRadyToCoupleIndicator : 0|2@1+ (1,0) [0|3] "" Vector__XXX
 SG_ FifthWheelErrorStatus : 0|4@1+ (1,0) [0|15] "" Vector__XXX
 SG_ RollAndPitchMeasurementLatency : 0|8@1+ (0.5,0) [0|125] "ms" Vector__XXX
 SG_ PitchAndRollCompensated : 0|2@1+ (1,0) [0|3] "" Vector__XXX
 SG_ PitchRateFigureOfMerit : 0|2@1+ (1,0) [0|3] "" Vector__XXX
 SG_ RollAngleFigureOfMerit : 0|2@1+ (1,0) [0|3] "" Vector__XXX
 SG_ PitchAngleFigureOfMerit : 0|2@1+ (1,0) [0|3] "" Vector__XXX
 SG_ PitchRate : 0|16@1+ (0.002,-64) [-64|64.51] "deg/sec" Vector__XXX
 SG_ RollAngle : 0|16@1+ (0.002,-64) [-64|64.51] "deg" Vector__XXX
 SG_ PitchAngle : 0|16@1+ (0.002,-64) [-64|64.51] "deg" Vector__XXX
 SG_ TransOilLevelMeasurementStatus : 0|4@1+ (1,0) [0|15] "" Vector__XXX
 SG_ TransOilLevelCountdownTimer : 0|4@1+ (1,0) [0|15] "" Vector__XXX
 SG_ TransOilLevelHigh_Low : 0|8@1+ (0.5,-62.5) [-62.5|62.5] "L" Vector__XXX
 SG_ TransOilTemp : 0|16@1+ (0.03125,-273) [-273|1735] "°C" Vector__XXX
 SG_ TransOilPress : 0|8@1+ (16,0) [0|4000] "kPa" Vector__XXX
 SG_ TransFilterDiffPress : 0|8@1+ (2,0) [0|500] "kPa" Vector__XXX
 SG_ TransOilLevel : 0|8@1+ (0.4,0) [0|100] "%" Vector__XXX
 SG_ ClutchPress : 0|8@1+ (16,0) [0|4000] "kPa" Vector__XXX
 SG_ BatteryPotentialSwitched : 0|16@1+ (0.05,0) [0|3212.75] "V" Vector__XXX
 SG_ ElectricalPotential : 0|16@1+ (0.05,0) [0|3212.75] "V" Vector__XXX
 SG_ ChargingSystemPotential : 0|16@1+ (0.05,0) [0|3212.75] "V" Vector__XXX
 SG_ AltCurrent : 0|8@1+ (1,0) [0|250] "A" Vector__XXX
 SG_ NetBatteryCurrent : 0|8@1+ (1,-125) [-125|125] "A" Vector__XXX
 SG_ WrlessCommunicationNetworkType2 : 0|8@1+ (1,0) [0|255] "" Vector__XXX
 SG_ NetworkSignalStrength2 : 0|8@1+ (0.4,0) [0|100] "%" Vector__XXX
 SG_ NetworkAntennaStatus2 : 0|8@1+ (1,0) [0|255] "" Vector__XXX
 SG_ NetworkServiceStatus2 : 0|8@1+ (1,0) [0|255] "" Vector__XXX
 SG_ NetworkTransceiverStatus2 : 0|8@1+ (1,0) [0|255] "" Vector__XXX
 SG_ WrlessCommunicationNetworkType1 : 0|8@1+ (1,0) [0|255] "" Vector__XXX
 SG_ NetworkSignalStrength1 : 0|8@1+ (0.4,0) [0|100] "%" Vector__XXX
 SG_ NetworkAntennaStatus1 : 0|8@1+ (1,0) [0|255] "" Vector__XXX
 SG_ NetworkServiceStatus1 : 0|8@1+ (1,0) [0|255] "" Vector__XXX
 SG_ NetworkTransceiverStatus1 : 0|8@1+ (1,0) [0|255] "" Vector__XXX
 SG_ VoltageRegulatorEnabled : 0|2@1+ (1,0) [0|3] "" Vector__XXX
 SG_ VoltageRegulatorSoftStartState : 0|2@1+ (1,0) [0|3] "" Vector__XXX
 SG_ VltgRgltrUndrfrqncyCmpnstnEnbld : 0|2@1+ (1,0) [0|3] "" Vector__XXX
 SG_ VltgRgltrVAr_PwrFctrOprtingMode : 0|3@1+ (1,0) [0|7] "" Vector__XXX
 SG_ VltgRglatorLoadCompensationMode : 0|3@1+ (1,0) [0|7] "" Vector__XXX
 SG_ GnrtrOtputVoltageBiasPercentage : 0|16@1+ (0.1,-100) [-100|100] "%" Vector__XXX
 SG_ GeneratorExcitationFieldCurrent : 0|16@1+ (0.05,0) [0|3217.5] "A" Vector__XXX
 SG_ GeneratorExcitationFieldVoltage : 0|16@1+ (0.05,-1605.625) [-1605.625|1606.375] "V" Vector__XXX

BO_ 2566763776 DM23_EMS: 22 EMS
 SG_ SPN_High4 : 133|3@1+ (1,0) [0|7] "" Vector__XXX
 SG_ SPN_High3 : 101|3@1+ (1,0) [0|7] "" Vector__XXX
 SG_ SPN_High5 : 165|3@1+ (1,0) [0|7] "" Vector__XXX
 SG_ SPN_High2 : 69|3@1+ (1,0) [0|7] "" Vector__XXX
 SG_ SPN_High1 : 37|3@1+ (1,0) [0|7] "" Vector__XXX
 SG_ SpnConversionMethod1 : 47|1@1+ (1,0) [0|1] "" Vector__XXX
 SG_ SpnConversionMethod5 : 175|1@1+ (1,0) [0|1] "" Vector__XXX
 SG_ SpnConversionMethod4 : 143|1@1+ (1,0) [0|1] "" Vector__XXX
 SG_ SpnConversionMethod3 : 111|1@1+ (1,0) [0|1] "" Vector__XXX
 SG_ SpnConversionMethod2 : 79|1@1+ (1,0) [0|1] "" Vector__XXX
 SG_ OccurenceCount5 : 168|7@1+ (1,0) [0|127] "" Vector__XXX
 SG_ OccurenceCount4 : 136|7@1+ (1,0) [0|127] "" Vector__XXX
 SG_ OccurenceCount3 : 104|7@1+ (1,0) [0|127] "" Vector__XXX
 SG_ OccurenceCount2 : 72|7@1+ (1,0) [0|127] "" Vector__XXX
 SG_ OccurenceCount1 : 40|7@1+ (1,0) [0|127] "" Vector__XXX
 SG_ FMI5 : 160|5@1+ (1,0) [0|31] "" Vector__XXX
 SG_ FMI4 : 128|5@1+ (1,0) [0|31] "" Vector__XXX
 SG_ FMI3 : 96|5@1+ (1,0) [0|31] "" Vector__XXX
 SG_ FMI2 : 64|5@1+ (1,0) [0|31] "" Vector__XXX
 SG_ FMI1 : 32|5@1+ (1,0) [0|31] "" Vector__XXX
 SG_ FlashRedStopLamp : 12|2@1+ (1,0) [0|3] "" Vector__XXX
 SG_ FlashProtectLamp : 8|2@1+ (1,0) [0|3] "" Vector__XXX
 SG_ FlashMalfuncIndicatorLamp : 14|2@1+ (1,0) [0|3] "" Vector__XXX
 SG_ FlashAmberWarningLamp : 10|2@1+ (1,0) [0|3] "" Vector__XXX
 SG_ MalfunctionIndLampStatus : 6|2@1+ (1,0) [0|3] "" Vector__XXX
 SG_ AmberWarningLampStatus : 2|2@1+ (1,0) [0|3] "" Vector__XXX
 SG_ RedStopLampState : 4|2@1+ (1,0) [0|3] "" Vector__XXX
 SG_ ProtectLampStatus : 0|2@1+ (1,0) [0|3] "" Vector__XXX
 SG_ SPN5 : 144|16@1+ (1,0) [0|524287] "" Vector__XXX
 SG_ SPN4 : 112|16@1+ (1,0) [0|524287] "" Vector__XXX
 SG_ SPN3 : 80|16@1+ (1,0) [0|524287] "" Vector__XXX
 SG_ SPN2 : 48|16@1+ (1,0) [0|524287] "" Vector__XXX
 SG_ SPN1 : 16|16@1+ (1,0) [0|524287] "" Vector__XXX

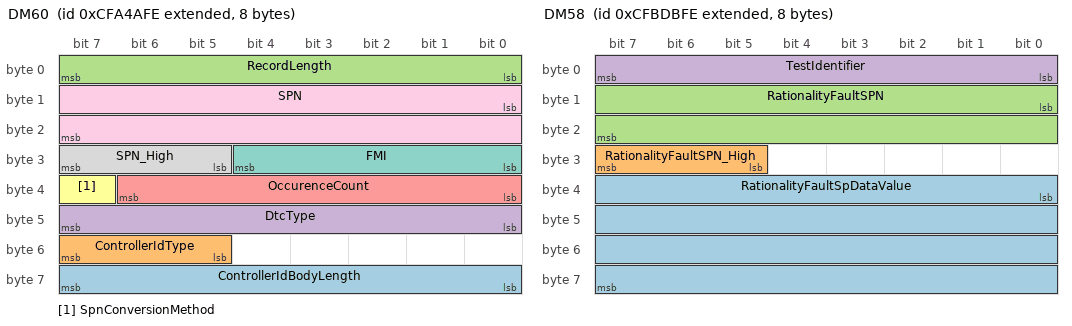
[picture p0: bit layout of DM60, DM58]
BO_ 2365213438 DM60: 8 Vector__XXX
 SG_ ControllerIdBodyLength : 56|8@1+ (1,0) [0|0] "" Vector__XXX
 SG_ ControllerIdType : 53|3@1+ (1,0) [0|0] "" Vector__XXX
 SG_ RecordLength : 0|8@1+ (1,0) [0|0] "" Vector__XXX
 SG_ DtcType : 40|8@1+ (1,0) [0|0] "" Vector__XXX
 SG_ OccurenceCount : 32|7@1+ (1,0) [0|127] "" Vector__XXX
 SG_ SpnConversionMethod : 39|1@1+ (1,0) [0|1] "" Vector__XXX
 SG_ FMI : 24|5@1+ (1,0) [0|31] "" Vector__XXX
 SG_ SPN_High : 29|3@1+ (1,0) [0|7] "" Vector__XXX
 SG_ SPN : 8|16@1+ (1,0) [0|524287] "" Vector__XXX

BO_ 2365271294 DM59: 8 Vector__XXX
 SG_ TimeElapsedSinceDTCsErased : 16|16@1+ (1,0) [0|0] "hour" Vector__XXX
 SG_ ContinuousMiTimeWhileEngOp : 0|16@1+ (1,0) [0|0] "hour" Vector__XXX

BO_ 2365316094 DM58: 8 Vector__XXX
 SG_ RationalityFaultSpDataValue : 32|32@1+ (1,0) [0|0] "" Vector__XXX
 SG_ RationalityFaultSPN_High : 29|3@1+ (1,0) [0|7] "" Vector__XXX
 SG_ RationalityFaultSPN : 8|16@1+ (1,0) [0|524287] "" Vector__XXX
 SG_ TestIdentifier : 0|8@1+ (1,0) [0|255] "" Vector__XXX

BO_ 2566702846 DM57: 8 Vector__XXX
 SG_ EngOBDWarmUpSequence : 0|2@1+ (1,0) [0|3] "" Vector__XXX

BO_ 2566703102 DM56: 208 Vector__XXX
 SG_ CertificationEngineFamilyName : 64|64@1+ (1,0) [0|255] "" Vector__XXX
 SG_ ModelYear : 0|64@1+ (1,0) [0|255] "" Vector__XXX

BO_ 2566706174 DM55: 0 Vector__XXX

CM_ SG_ 3221225472 RedStopLampState "This lamp is uesed to relay trouble code information that is of a severe enought condition that it warrants stopping the vehicle.This lamp is uesed to relay trouble code information that is of a severe enought condition that it warrants stopping the vehicle.This lamp is uesed to relay trouble code information that is of a severe enought condition that it warrants stopping the vehicle.This lamp is uesed to relay trouble code information that is of a severe enought condition that it warrants stopping the vehicle.This lamp is uesed to relay trouble code information that is of a severe enought condition that it warrants stopping the vehicle.This lamp is uesed to relay trouble code information that is of a severe enought condition that it warrants stopping the vehicle.This lamp is uesed to relay trouble code information that is of a severe enought condition that it warrants stopping the vehicle.This lamp is uesed to relay trouble code information that is of a severe enought condition that it warrants stopping the";
CM_ SG_ 3221225472 AmberWarningLampStatus "This lamp is used to relay trouble code information that is reporting a problem with the vehicle system but the vehicle need
not be immediately stopped.This lamp is used to relay trouble code information that is reporting a problem with the vehicle system but the vehicle need
not be immediately stopped.This lamp is used to relay trouble code information that is reporting a problem with the vehicle system but the vehicle need
not be immediately stopped.This lamp is used to relay trouble code information that is reporting a problem with the vehicle system but the vehicle need
not be immediately stopped.This lamp is used to relay trouble code information that is reporting a problem with the vehicle system but the vehicle need
not be immediately stopped.This lamp is used to relay trouble code information that is reporting a problem with the vehicle system but the vehicle need
not be immediately stopped.This lamp is used to relay trouble code information that is reporting a problem with the vehicle system b";
CM_ SG_ 3221225472 ProtectLampStatus "This lamp is used to relay trouble code informatio that is reporting a problem with a vehicle system that is most
probably not electronic subsystem related.This lamp is used to relay trouble code informatio that is reporting a problem with a vehicle system that is most
probably not electronic subsystem related.This lamp is used to relay trouble code informatio that is reporting a problem with a vehicle system that is most
probably not electronic subsystem related.This lamp is used to relay trouble code informatio that is reporting a problem with a vehicle system that is most
probably not electronic subsystem related.This lamp is used to relay trouble code informatio that is reporting a problem with a vehicle system that is most
probably not electronic subsystem related.This lamp is used to relay trouble code informatio that is reporting a problem with a vehicle system that is most
probably not electronic subsystem related.This lamp is used to relay trouble code informatio that is reporting a problem wi";
CM_ SG_ 3221225472 DTC5 "Diagnostic Trouble CodeDiagnostic Trouble CodeDiagnostic Trouble CodeDiagnostic Trouble CodeDiagnostic Trouble CodeDiagnostic Trouble CodeDiagnostic Trouble CodeDiagnostic Trouble CodeDiagnostic Trouble CodeDiagnostic Trouble CodeDiagnostic Trouble CodeDiagnostic Trouble CodeDiagnostic Trouble CodeDiagnostic Trouble CodeDiagnostic Trouble CodeDiagnostic Trouble Code";
CM_ SG_ 3221225472 DTC4 "Diagnostic Trouble CodeDiagnostic Trouble CodeDiagnostic Trouble CodeDiagnostic Trouble CodeDiagnostic Trouble CodeDiagnostic Trouble CodeDiagnostic Trouble CodeDiagnostic Trouble CodeDiagnostic Trouble CodeDiagnostic Trouble CodeDiagnostic Trouble CodeDiagnostic Trouble CodeDiagnostic Trouble CodeDiagnostic Trouble CodeDiagnostic Trouble CodeDiagnostic Trouble Code";
CM_ SG_ 3221225472 DTC3 "Diagnostic Trouble CodeDiagnostic Trouble CodeDiagnostic Trouble CodeDiagnostic Trouble CodeDiagnostic Trouble CodeDiagnostic Trouble CodeDiagnostic Trouble CodeDiagnostic Trouble CodeDiagnostic Trouble CodeDiagnostic Trouble CodeDiagnostic Trouble CodeDiagnostic Trouble CodeDiagnostic Trouble CodeDiagnostic Trouble CodeDiagnostic Trouble CodeDiagnostic Trouble Code";
CM_ SG_ 3221225472 DTC2 "Diagnostic Trouble CodeDiagnostic Trouble CodeDiagnostic Trouble CodeDiagnostic Trouble CodeDiagnostic Trouble CodeDiagnostic Trouble CodeDiagnostic Trouble CodeDiagnostic Trouble CodeDiagnostic Trouble CodeDiagnostic Trouble CodeDiagnostic Trouble CodeDiagnostic Trouble CodeDiagnostic Trouble CodeDiagnostic Trouble CodeDiagnostic Trouble CodeDiagnostic Trouble Code";
CM_ SG_ 3221225472 UtlityOverallPowerFactorLagging "Lead/lag status for utility incomer average power factor.";
CM_ SG_ 3221225472 UtilityOverallPowerFactor "The average power factor of the utility incomer.";
CM_ SG_ 3221225472 UtilityTotalReactivePower "The total reactive power delivered by the utility incomer";
CM_ SG_ 3221225472 UtilityTotalApparentPower "The total apparent power delivered by the utility incomer.";
CM_ SG_ 3221225472 UtilityTotalRealPower "Total real power delivered by the utility incomer.";
CM_ SG_ 3221225472 UtilityTotalKWHoursImport "The total kilowatt-hours that have been imported by the utility incomer.";
CM_ SG_ 3221225472 UtilityTotalKWHoursExport "The total kilowatt-hours that have been exported by the utility incomer.";
CM_ SG_ 3221225472 UtilityPhaseCPowerFactorLagging "Lead/lag status for utility incomer phase C power factor.";
CM_ SG_ 3221225472 UtilityPhaseCPowerFactor "The power factor of phases C of the utility incomer.";
CM_ SG_ 3221225472 UtilityPhaseCReactivePower "The reactive power delivered by phase C of the utility incomer";
CM_ SG_ 3221225472 UtilityPhaseCApparentPower "The apparent power delivered by phase C of the utility incomer.";
CM_ SG_ 3221225472 UtilityPhaseCRealPower "The real power delivered by phase C of the utility incomer.";
CM_ SG_ 3221225472 UtilityPhaseCACRMSCurrent "RMS current measured at the utility incomer phase C.";
CM_ SG_ 3221225472 UtilityPhaseCACFrequency "AC frequency measured at the utility incomer phase C.";
CM_ SG_ 3221225472 UtltyPhsCLneNeutralACRMSVoltage "Line to Neutral RMS voltage measured at the utility incomer phase C.";
CM_ SG_ 3221225472 UtltyPhseCALineLineACRMSVoltage "Line to Line RMS voltage measured at the utility incomer phase CA.";
CM_ SG_ 3221225472 UtilityPhaseBPowerFactorLagging "Lead/lag status for utility incomer phase B power factor.";
CM_ SG_ 3221225472 UtilityPhaseBPowerFactor "The power factor of phases B of the utility incomer.";
CM_ SG_ 3221225472 UtilityPhaseBReactivePower "The reactive power delivered by phase B of the utility incomer";
CM_ SG_ 3221225472 UtilityPhaseBApparentPower "The apparent power delivered by phase B of the utility incomer.";
CM_ SG_ 3221225472 UtilityPhaseBRealPower "The real power delivered by phase B of the utility incomer.";
CM_ SG_ 3221225472 UtilityPhaseBACRMSCurrent "RMS current measured at the utility incomer phase B.";
CM_ SG_ 3221225472 UtilityPhaseBACFrequency "AC frequency measured at the utility incomer phase B.";
CM_ SG_ 3221225472 UtltyPhsBLneNeutralACRMSVoltage "Line to Neutral RMS voltage measured at the utility incomer phase B.";
CM_ SG_ 3221225472 UtltyPhseBCLineLineACRMSVoltage "Line to Line RMS voltage measured at the utility incomer phase BC.";
CM_ SG_ 3221225472 UtilityPhaseAPowerFactorLagging "Lead/lag status for utility incomer phase A power factor.";
CM_ SG_ 3221225472 UtilityPhaseAPowerFactor "The power factor of phase A of the utility incomer.";
CM_ SG_ 3221225472 UtilityPhaseAReactivePower "The reactive power delivered by phase A of the utility incomer";
CM_ SG_ 3221225472 UtilityPhaseAApparentPower "The apparent power delivered by phase A of the utility incomer.";
CM_ SG_ 3221225472 UtilityPhaseARealPower "The real power delivered by phase A of the utility incomer.";
CM_ SG_ 3221225472 UtilityPhaseAACRMSCurrent "RMS current measured at the utility incomer phase A.";
CM_ SG_ 3221225472 UtilityPhaseAACFrequency "AC frequency measured at the utility incomer phase A.";
CM_ SG_ 3221225472 UtltyPhsALneNeutralACRMSVoltage "Line to Neutral RMS voltage measured at the utility incomer phase A.";
CM_ SG_ 3221225472 UtltyPhseABLineLineACRMSVoltage "Line to Line RMS voltage measured at the utility incomer phase AB.";
CM_ SG_ 3221225472 UtilityAverageACRMSCurrent "Average RMS current measured at the utility incomer.";
CM_ SG_ 3221225472 UtilityAverageACFrequency "Average AC frequency measured at the utility incomer.";
CM_ SG_ 3221225472 UtltyAvrgLneNeutralACRMSVoltage "The average Line to Neutral AC RMS voltage measured at the utility incomer .";
CM_ SG_ 3221225472 UtltyAvrageLineLineACRMSVoltage "Average Line to Line RMS voltage measured at the utility incomer .";
CM_ SG_ 3221225472 GnrtorOverallPowerFactorLagging "Lead/lag status for generator average power factor.";
CM_ SG_ 3221225472 GeneratorOverallPowerFactor "The average power factor of the generator.";
CM_ SG_ 3221225472 GeneratorTotalReactivePower "The total reactive power delivered by the generator";
CM_ SG_ 3221225472 GeneratorTotalApparentPower "The total apparent power delivered by the generator.";
CM_ SG_ 3221225472 GeneratorTotalRealPower "Total real power delivered by the generator.";
CM_ SG_ 3221225472 GeneratorTotalKWHoursImport "The total kilowatt-hours that have been imported by the generator.";
CM_ SG_ 3221225472 GeneratorTotalKWHoursExport "The total kilowatt-hours that have been exported by the generator.";
CM_ SG_ 3221225472 GnratorPhaseCPowerFactorLagging "Lead/lag status for generator phase C power factor.";
CM_ SG_ 3221225472 GeneratorPhaseCPowerFactor "The power factor of phases C of the generator.";
CM_ SG_ 3221225472 GeneratorPhaseCReactivePower "The reactive power delivered by phase C of the generator";
CM_ SG_ 3221225472 GeneratorPhaseCApparentPower "The apparent power delivered by phase C of the generator.";
CM_ SG_ 3221225472 GeneratorPhaseCRealPower "The real power delivered by phase C of the generator.";
CM_ SG_ 3221225472 GeneratorPhaseCACRMSCurrent "RMS current measured at the generator phase C output.";
CM_ SG_ 3221225472 GeneratorPhaseCACFrequency "AC frequency measured at the generator phase C output.";
CM_ SG_ 3221225472 GnrtrPhsCLneNeutralACRMSVoltage "Line to Neutral RMS voltage measured at the generator phase C output.";
CM_ SG_ 3221225472 GnrtrPhseCALineLineACRMSVoltage "Line to Line RMS voltage measured at the generator phase CA output.";
CM_ SG_ 3221225472 GnratorPhaseBPowerFactorLagging "Lead/lag status for generator phase B power factor.";
CM_ SG_ 3221225472 GeneratorPhaseBPowerFactor "The power factor of phases B of the generator.";
CM_ SG_ 3221225472 GeneratorPhaseBReactivePower "The reactive power delivered by phase B of the generator";
CM_ SG_ 3221225472 GeneratorPhaseBApparentPower "The apparent power delivered by phase B of the generator.";
CM_ SG_ 3221225472 GeneratorPhaseBRealPower "The real power delivered by phase B of the generator.";
CM_ SG_ 3221225472 GeneratorPhaseBACRMSCurrent "RMS current measured at the generator phase B output.";
CM_ SG_ 3221225472 GeneratorPhaseBACFrequency "AC frequency measured at the generator phase B output.";
CM_ SG_ 3221225472 GnrtrPhsBLneNeutralACRMSVoltage "Line to Neutral RMS voltage measured at the generator phase B output.";
CM_ SG_ 3221225472 GnrtrPhseBCLineLineACRMSVoltage "Line to Line RMS voltage measured at the generator phase BC output.";
CM_ SG_ 3221225472 GnratorPhaseAPowerFactorLagging "Lead/lag status for generator phase A power factor.";
CM_ SG_ 3221225472 GeneratorPhaseAPowerFactor "The power factor of phase A of the generator.";
CM_ SG_ 3221225472 GeneratorPhaseAReactivePower "The reactive power delivered by phase A of the generator";
CM_ SG_ 3221225472 GeneratorPhaseAApparentPower "The apparent power delivered by phase A of the generator.";
CM_ SG_ 3221225472 GeneratorPhaseARealPower "The real power delivered by phase A of the generator.";
CM_ SG_ 3221225472 GeneratorPhaseAACRMSCurrent "RMS current measured at the generator phase A output.";
CM_ SG_ 3221225472 GeneratorPhaseAACFrequency "AC frequency measured at the generator phase A output.";
CM_ SG_ 3221225472 GnrtrPhsALneNeutralACRMSVoltage "Line to Neutral RMS voltage measured at the generator phase A output.";
CM_ SG_ 3221225472 GnrtrPhseABLineLineACRMSVoltage "Line to Line RMS voltage measured at the generator phase AB output.";
CM_ SG_ 3221225472 GeneratorAverageACRMSCurrent "Average RMS current measured at the generator output.";
CM_ SG_ 3221225472 GeneratorAverageACFrequency "Average AC frequency measured at the generator output.";
CM_ SG_ 3221225472 GnrtrAvrgLneNeutralACRMSVoltage "The average Line to Neutral AC RMS voltage measured at the Generator output.";
CM_ SG_ 3221225472 GnrtrAvrageLineLineACRMSVoltage "Average Line to Line RMS voltage measured at the generator output.";
CM_ SG_ 3221225472 Bus1_UtilityACPhaseDifference "The phase difference between the Bus #1 voltage and Utility voltage.";
CM_ SG_ 3221225472 Bus1_UtilityInSync "Indicator of whether Bus #1 and Utility are properly synchronized for paralleling. This indicator will be based on parameters such as Voltage Match, Frequency Match, and Phase Match.";
CM_ SG_ 3221225472 Bus1_UtilityVoltageMatch "Indicator of whether voltage difference between Bus #1 and Utility is adequate for paralleling. This indicator will be based on the measured AC voltages qualified using parameters such as Voltage Tolerance.";
CM_ SG_ 3221225472 Bus1_UtilityFrequencyMatch "Indicator of whether frequency difference between Bus #1 and Utility is adequate for paralleling. This indicator will be based on the measured AC frequencies qualified using parameters such as Frequency Tolerance, Phase Tolerance, and Dwell Time.";
CM_ SG_ 3221225472 Bus1_UtilityPhaseMatch "Indicator of whether phase difference between Bus #1 and Utility is adequate for paralleling. This indicator will be based on the measured AC phase difference qualified using parameters such as Phase Tolerance and Dwell Time.";
CM_ SG_ 3221225472 Bus1_UtilityDeadBus "Indicator of whether Bus #1 is considered dead for closing to the utility. This indicator will be based on parameters such as Bus #1 Voltage and dead bus threshold values.";
CM_ SG_ 3221225472 Bus1PhaseCACFrequency "AC frequency measured at bus #1 phase C.";
CM_ SG_ 3221225472 Bs1PhseCLineNeutralACRMSVoltage "Line to Neutral RMS voltage measured at bus #1 phase C.";
CM_ SG_ 3221225472 Bus1PhaseCALineLineACRMSVoltage "Line to Line RMS voltage measured at bus #1 phase CA.";
CM_ SG_ 3221225472 Bus1PhaseBACFrequency "AC frequency measured at bus #1 phase B.";
CM_ SG_ 3221225472 Bs1PhseBLineNeutralACRMSVoltage "Line to Neutral RMS voltage measured at bus #1 phase B.";
CM_ SG_ 3221225472 Bus1PhaseBCLineLineACRMSVoltage "Line to Line RMS voltage measured at bus #1 phase BC.";
CM_ SG_ 3221225472 Bus1PhaseAACFrequency "AC frequency measured at bus #1 phase A.";
CM_ SG_ 3221225472 Bs1PhseALineNeutralACRMSVoltage "Line to Neutral RMS voltage measured at bus #1 phase A.";
CM_ SG_ 3221225472 Bus1PhaseABLineLineACRMSVoltage "Line to Line RMS voltage measured at bus #1 phase AB.";
CM_ SG_ 3221225472 Bus1_GeneratorACPhaseDifference "The phase difference between the Bus #1 voltage and Generator voltage.";
CM_ SG_ 3221225472 Bus1_GeneratorInSync "Indicator of whether Bus #1 and Generator are properly synchronized for paralleling. This indicator will be based on parameters such as Voltage Match, Frequency Match, and Phase Match.";
CM_ SG_ 3221225472 Bus1_GeneratorVoltageMatch "Indicator of whether voltage difference between Bus #1 and Generator is adequate for paralleling. This indicator will be based on the measured AC voltages qualified using parameters such as Voltage Tolerance.";
CM_ SG_ 3221225472 Bus1_GeneratorFrequencyMatch "Indicator of whether frequency difference between Bus #1 and Generator is adequate for paralleling. This indicator will be based on the measured AC frequencies qualified using parameters such as Frequency Tolerance, Phase Tolerance, and Dwell Time.";
CM_ SG_ 3221225472 Bus1_GeneratorPhaseMatch "Indicator of whether phase difference between Bus #1 and Generator is adequate for paralleling. This indicator will be based on the measured AC phase difference qualified using parameters such as Phase Tolerance and Dwell Time.";
CM_ SG_ 3221225472 Bus1_GeneratorDeadBus "Indicator of whether Bus #1 is considered dead for closing to the generator. This indicator will be based on parameters such as Bus #1 Voltage and dead bus threshold values.";
CM_ SG_ 3221225472 Bus1AverageACFrequency "Average AC frequency measured at bus #1.";
CM_ SG_ 3221225472 Bs1AvrgeLineNeutralACRMSVoltage "The average Line to Neutral AC RMS voltage measured at bus #1 .";
CM_ SG_ 3221225472 Bus1AverageLineLineACRMSVoltage "Average Line to Line RMS voltage measured at bus #1 .";
CM_ SG_ 3221225472 AddressAssignment "The source address that is to be assigned to the CA that has the NAME corresponding to the one conveyed in the first eight bytes of this Commanded Address message.";
CM_ SG_ 3221225472 IndustryGroup "0 = Global; 
   1  = On-Highway; 
   2  = Agricultural and Forestry; 
   3  = Construction; 
   4  = Marine;
   5  = Industrial - Process
          Control - Stationary (Gen-Sets)
   6  = Reserve for SAE
   7  = Reserve for SAE";
CM_ SG_ 3221225472 ManufacturerCode "Assigned by NMEA 2000 Committee";
CM_ SG_ 3221225472 AxleGroupWeight "Total mass imposed on the road surface by all the tires in the axle group";
CM_ SG_ 3221225472 AxleGroupLocation "Specific axle group used in conjunction with and when communicating the axle group calibration, listed from the front of theSpecific axle group used in conjunction with and when communicating the axle group calibration, listed from the front of the";
CM_ SG_ 3221225472 AxleGroupFullWeightCalib "The full weight calibration measurement of an axle group";
CM_ SG_ 3221225472 AxleGroupEmptyWeightCalib "The empty weight calibration measurement of an axle group";
CM_ SG_ 3221225472 DsrdAftrclrClntThrmostatOpening "Used to transmit the desired position of the low temperature aftercooler temperature control valve.";
CM_ SG_ 3221225472 DsrdAftercoolerCoolantInletTemp "Indicates the desired temperature of the fluid in the low temperature aftercooler circuit to an electronic thermostat.";
CM_ SG_ 3221225472 AftrcoolerCoolantThermostatMode "Specifies if the aftercooler coolant thermostat valve will operate in temperature control mode or position control mode.";
CM_ SG_ 3221225472 AddtnlTrlrAxlGrpWeightAvailable "Indicates the availability of the additional trailer axle group for purposes of weight measurement";
CM_ SG_ 3221225472 TrilerHAxleGroupWeightAvailable "Indicates the availability of the trailer H axle group for purposes of weight measurement";
CM_ SG_ 3221225472 TrilerGAxleGroupWeightAvailable "Indicates the availability of the trailer G axle group for purposes of weight measurement";
CM_ SG_ 3221225472 TrilerFAxleGroupWeightAvailable "Indicates the availability of the trailer F axle group for purposes of weight measurement";
CM_ SG_ 3221225472 TrilerEAxleGroupWeightAvailable "Indicates the availability of the trailer E axle group for purposes of weight measurement";
CM_ SG_ 3221225472 TrilerDAxleGroupWeightAvailable "Indicates the availability of the trailer D axle group for purposes of weight measurement";
CM_ SG_ 3221225472 TrilerCAxleGroupWeightAvailable "Indicates the availability of the trailer C axle group for purposes of weight measurement";
CM_ SG_ 3221225472 TrilerBAxleGroupWeightAvailable "Indicates the availability of the trailer B axle group for purposes of weight measurement";
CM_ SG_ 3221225472 TrilerAAxleGroupWeightAvailable "Indicates the availability of the trailer A axle group for purposes of weight measurement";
CM_ SG_ 3221225472 AddtnlTrctrAxlGrpWightAvailable "Indicates the availability of the additional tractor axle group for purposes of weight measurement";
CM_ SG_ 3221225472 TagAxleGroupWeightAvailable "Indicates the availability of the tag axle group for purposes of weight measurement";
CM_ SG_ 3221225472 DriveAxleGroupWeightAvailable "Indicates the availability of the drive axle group for purposes of weight measurement";
CM_ SG_ 3221225472 LiftAxleGroupWeightAvailable "Indicates the availability of the lift axle group for purposes of weight measurement";
CM_ SG_ 3221225472 SteerAxleGroupWeightAvailable "Indicates the availability of the steer axle group for purposes of weight measurement";
CM_ SG_ 3221225472 ZeroNetVehicleWeightChange "Zero Net Vehicle Weight Change command.";
CM_ SG_ 3221225472 EngineExhaustGasTempAvrBank1 "The calculated average temperature based upon all of the Bank 1 (left bank) engine exhaust port temperatures.";
CM_ SG_ 3221225472 EngineExhaustGasTempAvrBank2 "The calculated average temperature based upon all of the Bank 2 (right bank) engine exhaust port temperatures.";
CM_ SG_ 3221225472 EngExhaustGasTempAvrg "The calculated average temperature based upon all of the engine exhaust port temperatures.";
CM_ SG_ 3221225472 NumberOfAETCDataPoints "Indicates the number of speed / torque data points contained in the Advertised Engine Torque Curve broadcast (AETC).";
CM_ SG_ 3221225472 AETCDataCollectionStandard "Indicates the standardized method by which torque data was obtained for the Advertised Engine Torque Curve (AETC).";
CM_ SG_ 3221225472 RightHeadlampLightDistribution "This parameter indicates what kind of light distribution is set by the AFS system for the right headlamp.";
CM_ SG_ 3221225472 LeftHeadlampLightDistribution "This parameter indicates what kind of light distribution is set by the AFS system for the left headlamp.";
CM_ SG_ 3221225472 RghtHeadlampDynamicBendingLight "This parameter indicates whether the dynamic bending light of the left headlamp is working properly.";
CM_ SG_ 3221225472 LeftHeadlampDynamicBendingLight "This parameter indicates whether the dynamic bending light of the left headlamp is working properly.";
CM_ SG_ 3221225472 AuxI_OChannel2 "Auxiliary channel of data (16 bit) read by the ECU.";
CM_ SG_ 3221225472 AuxI_OChannel1 "Auxiliary channel of data (16 bit) read by the ECU.";
CM_ SG_ 3221225472 AuxI_O45 "Identifies the current status of auxiliary input/output functions that are configured uniquely per application.";
CM_ SG_ 3221225472 AuxI_O46 "Identifies the current status of auxiliary input/output functions that are configured uniquely per application.";
CM_ SG_ 3221225472 AuxI_O47 "Identifies the current status of auxiliary input/output functions that are configured uniquely per application.";
CM_ SG_ 3221225472 AuxI_O48 "Identifies the current status of auxiliary input/output functions that are configured uniquely per application.";
CM_ SG_ 3221225472 AuxI_O41 "Identifies the current status of auxiliary input/output functions that are configured uniquely per application.";
CM_ SG_ 3221225472 AuxI_O42 "Identifies the current status of auxiliary input/output functions that are configured uniquely per application.";
CM_ SG_ 3221225472 AuxI_O43 "Identifies the current status of auxiliary input/output functions that are configured uniquely per application.";
CM_ SG_ 3221225472 AuxI_O44 "Identifies the current status of auxiliary input/output functions that are configured uniquely per application.";
CM_ SG_ 3221225472 AuxI_O37 "Identifies the current status of auxiliary input/output functions that are configured uniquely per application.";
CM_ SG_ 3221225472 AuxI_O38 "Identifies the current status of auxiliary input/output functions that are configured uniquely per application.";
CM_ SG_ 3221225472 AuxI_O39 "Identifies the current status of auxiliary input/output functions that are configured uniquely per application.";
CM_ SG_ 3221225472 AuxI_O40 "Identifies the current status of auxiliary input/output functions that are configured uniquely per application.";
CM_ SG_ 3221225472 AuxI_O33 "Identifies the current status of auxiliary input/output functions that are configured uniquely per application.";
CM_ SG_ 3221225472 AuxI_O34 "Identifies the current status of auxiliary input/output functions that are configured uniquely per application.";
CM_ SG_ 3221225472 AuxI_O35 "Identifies the current status of auxiliary input/output functions that are configured uniquely per application.";
CM_ SG_ 3221225472 AuxI_O36 "Identifies the current status of auxiliary input/output functions that are configured uniquely per application.";
CM_ SG_ 3221225472 AuxI_O29 "Identifies the current status of auxiliary input/output functions that are configured uniquely per application.";
CM_ SG_ 3221225472 AuxI_O30 "Identifies the current status of auxiliary input/output functions that are configured uniquely per application.";
CM_ SG_ 3221225472 AuxI_O31 "Identifies the current status of auxiliary input/output functions that are configured uniquely per application.";
CM_ SG_ 3221225472 AuxI_O32 "Identifies the current status of auxiliary input/output functions that are configured uniquely per application.";
CM_ SG_ 3221225472 AuxI_O25 "Identifies the current status of auxiliary input/output functions that are configured uniquely per application.";
CM_ SG_ 3221225472 AuxI_O26 "Identifies the current status of auxiliary input/output functions that are configured uniquely per application.";
CM_ SG_ 3221225472 AuxI_O27 "Identifies the current status of auxiliary input/output functions that are configured uniquely per application.";
CM_ SG_ 3221225472 AuxI_O28 "Identifies the current status of auxiliary input/output functions that are configured uniquely per application.";
CM_ SG_ 3221225472 AuxI_O21 "Identifies the current status of auxiliary input/output functions that are configured uniquely per application.";
CM_ SG_ 3221225472 AuxI_O22 "Identifies the current status of auxiliary input/output functions that are configured uniquely per application.";
CM_ SG_ 3221225472 AuxI_O23 "Identifies the current status of auxiliary input/output functions that are configured uniquely per application.";
CM_ SG_ 3221225472 AuxI_O24 "Identifies the current status of auxiliary input/output functions that are configured uniquely per application.";
CM_ SG_ 3221225472 AuxI_O17 "Identifies the current status of auxiliary input/output functions that are configured uniquely per application.";
CM_ SG_ 3221225472 AuxI_O18 "Identifies the current status of auxiliary input/output functions that are configured uniquely per application.";
CM_ SG_ 3221225472 AuxI_O19 "Identifies the current status of auxiliary input/output functions that are configured uniquely per application.";
CM_ SG_ 3221225472 AuxI_O20 "Identifies the current status of auxiliary input/output functions that are configured uniquely per application.";
CM_ SG_ 3221225472 AuxI_O77 "Identifies the current status of auxiliary input/output functions that are configured uniquely per application.";
CM_ SG_ 3221225472 AuxI_O78 "Identifies the current status of auxiliary input/output functions that are configured uniquely per application.";
CM_ SG_ 3221225472 AuxI_O79 "Identifies the current status of auxiliary input/output functions that are configured uniquely per application.";
CM_ SG_ 3221225472 AuxI_O80 "Identifies the current status of auxiliary input/output functions that are configured uniquely per application.";
CM_ SG_ 3221225472 AuxI_O73 "Identifies the current status of auxiliary input/output functions that are configured uniquely per application.";
CM_ SG_ 3221225472 AuxI_O74 "Identifies the current status of auxiliary input/output functions that are configured uniquely per application.";
CM_ SG_ 3221225472 AuxI_O75 "Identifies the current status of auxiliary input/output functions that are configured uniquely per application.";
CM_ SG_ 3221225472 AuxI_O76 "Identifies the current status of auxiliary input/output functions that are configured uniquely per application.";
CM_ SG_ 3221225472 AuxI_O69 "Identifies the current status of auxiliary input/output functions that are configured uniquely per application.";
CM_ SG_ 3221225472 AuxI_O70 "Identifies the current status of auxiliary input/output functions that are configured uniquely per application.";
CM_ SG_ 3221225472 AuxI_O71 "Identifies the current status of auxiliary input/output functions that are configured uniquely per application.";
CM_ SG_ 3221225472 AuxI_O72 "Identifies the current status of auxiliary input/output functions that are configured uniquely per application.";
CM_ SG_ 3221225472 AuxI_O65 "Identifies the current status of auxiliary input/output functions that are configured uniquely per application.";
CM_ SG_ 3221225472 AuxI_O66 "Identifies the current status of auxiliary input/output functions that are configured uniquely per application.";
CM_ SG_ 3221225472 AuxI_O67 "Identifies the current status of auxiliary input/output functions that are configured uniquely per application.";
CM_ SG_ 3221225472 AuxI_O68 "Identifies the current status of auxiliary input/output functions that are configured uniquely per application.";
CM_ SG_ 3221225472 AuxI_O61 "Identifies the current status of auxiliary input/output functions that are configured uniquely per application.";
CM_ SG_ 3221225472 AuxI_O62 "Identifies the current status of auxiliary input/output functions that are configured uniquely per application.";
CM_ SG_ 3221225472 AuxI_O63 "Identifies the current status of auxiliary input/output functions that are configured uniquely per application.";
CM_ SG_ 3221225472 AuxI_O64 "Identifies the current status of auxiliary input/output functions that are configured uniquely per application.";
CM_ SG_ 3221225472 AuxI_O57 "Identifies the current status of auxiliary input/output functions that are configured uniquely per application.";
CM_ SG_ 3221225472 AuxI_O58 "Identifies the current status of auxiliary input/output functions that are configured uniquely per application.";
CM_ SG_ 3221225472 AuxI_O59 "Identifies the current status of auxiliary input/output functions that are configured uniquely per application.";
CM_ SG_ 3221225472 AuxI_O60 "Identifies the current status of auxiliary input/output functions that are configured uniquely per application.";
CM_ SG_ 3221225472 AuxI_O53 "Identifies the current status of auxiliary input/output functions that are configured uniquely per application.";
CM_ SG_ 3221225472 AuxI_O54 "Identifies the current status of auxiliary input/output functions that are configured uniquely per application.";
CM_ SG_ 3221225472 AuxI_O55 "Identifies the current status of auxiliary input/output functions that are configured uniquely per application.";
CM_ SG_ 3221225472 AuxI_O56 "Identifies the current status of auxiliary input/output functions that are configured uniquely per application.";
CM_ SG_ 3221225472 AuxI_O49 "Identifies the current status of auxiliary input/output functions that are configured uniquely per application.";
CM_ SG_ 3221225472 AuxI_O50 "Identifies the current status of auxiliary input/output functions that are configured uniquely per application.";
CM_ SG_ 3221225472 AuxI_O51 "Identifies the current status of auxiliary input/output functions that are configured uniquely per application.";
CM_ SG_ 3221225472 AuxI_O52 "Identifies the current status of auxiliary input/output functions that are configured uniquely per application.";
CM_ SG_ 3221225472 AuxI_O92 "Identifies the current status of auxiliary input/output functions that are configured uniquely per application.";
CM_ SG_ 3221225472 AuxI_O85 "Identifies the current status of auxiliary input/output functions that are configured uniquely per application.";
CM_ SG_ 3221225472 AuxI_O86 "Identifies the current status of auxiliary input/output functions that are configured uniquely per application.";
CM_ SG_ 3221225472 AuxI_O87 "Identifies the current status of auxiliary input/output functions that are configured uniquely per application.";
CM_ SG_ 3221225472 AuxI_O88 "Identifies the current status of auxiliary input/output functions that are configured uniquely per application.";
CM_ SG_ 3221225472 AuxI_O81 "Identifies the current status of auxiliary input/output functions that are configured uniquely per application.";
CM_ SG_ 3221225472 AuxI_O82 "Identifies the current status of auxiliary input/output functions that are configured uniquely per application.";
CM_ SG_ 3221225472 AuxI_O83 "Identifies the current status of auxiliary input/output functions that are configured uniquely per application.";
CM_ SG_ 3221225472 AuxI_O84 "Identifies the current status of auxiliary input/output functions that are configured uniquely per application.";
CM_ SG_ 3221225472 AuxI_O109 "Identifies the current status of auxiliary input/output functions that are configured uniquely per application.";
CM_ SG_ 3221225472 AuxI_O110 "Identifies the current status of auxiliary input/output functions that are configured uniquely per application.";
CM_ SG_ 3221225472 AuxI_O111 "Identifies the current status of auxiliary input/output functions that are configured uniquely per application.";
CM_ SG_ 3221225472 AuxI_O112 "Identifies the current status of auxiliary input/output functions that are configured uniquely per application.";
CM_ SG_ 3221225472 AuxI_O105 "Identifies the current status of auxiliary input/output functions that are configured uniquely per application.";
CM_ SG_ 3221225472 AuxI_O106 "Identifies the current status of auxiliary input/output functions that are configured uniquely per application.";
CM_ SG_ 3221225472 AuxI_O107 "Identifies the current status of auxiliary input/output functions that are configured uniquely per application.";
CM_ SG_ 3221225472 AuxI_O108 "Identifies the current status of auxiliary input/output functions that are configured uniquely per application.";
CM_ SG_ 3221225472 AuxI_O101 "Identifies the current status of auxiliary input/output functions that are configured uniquely per application.";
CM_ SG_ 3221225472 AuxI_O102 "Identifies the current status of auxiliary input/output functions that are configured uniquely per application.";
CM_ SG_ 3221225472 AuxI_O103 "Identifies the current status of auxiliary input/output functions that are configured uniquely per application.";
CM_ SG_ 3221225472 AuxI_O104 "Identifies the current status of auxiliary input/output functions that are configured uniquely per application.";
CM_ SG_ 3221225472 AuxI_O97 "Identifies the current status of auxiliary input/output functions that are configured uniquely per application.";
CM_ SG_ 3221225472 AuxI_O98 "Identifies the current status of auxiliary input/output functions that are configured uniquely per application.";
CM_ SG_ 3221225472 AuxI_O99 "Identifies the current status of auxiliary input/output functions that are configured uniquely per application.";
CM_ SG_ 3221225472 AuxI_O100 "Identifies the current status of auxiliary input/output functions that are configured uniquely per application.";
CM_ SG_ 3221225472 AuxI_O93 "Identifies the current status of auxiliary input/output functions that are configured uniquely per application.";
CM_ SG_ 3221225472 AuxI_O94 "Identifies the current status of auxiliary input/output functions that are configured uniquely per application.";
CM_ SG_ 3221225472 AuxI_O95 "Identifies the current status of auxiliary input/output functions that are configured uniquely per application.";
CM_ SG_ 3221225472 AuxI_O96 "Identifies the current status of auxiliary input/output functions that are configured uniquely per application.";
CM_ SG_ 3221225472 AuxI_O89 "Identifies the current status of auxiliary input/output functions that are configured uniquely per application.";
CM_ SG_ 3221225472 AuxI_O90 "Identifies the current status of auxiliary input/output functions that are configured uniquely per application.";
CM_ SG_ 3221225472 AuxI_O91 "Identifies the current status of auxiliary input/output functions that are configured uniquely per application.";
CM_ SG_ 3221225472 TrailerBrakeStrokeAxle5Right "Brake stroke status for right brake actuator on trailer axle 5.";
CM_ SG_ 3221225472 TrailerBrakeStrokeAxle5Left "Brake stroke status for left brake actuator on trailer axle 5.";
CM_ SG_ 3221225472 TrailerBrakeStrokeAxle4Right "Brake stroke status for right brake actuator on trailer axle 4.";
CM_ SG_ 3221225472 TrailerBrakeStrokeAxle4Left "Brake stroke status for left brake actuator on trailer axle 4.";
CM_ SG_ 3221225472 TrailerBrakeStrokeAxle3Right "Brake stroke status for right brake actuator on trailer axle 3.";
CM_ SG_ 3221225472 TrailerBrakeStrokeAxle3Left "Brake stroke status for left brake actuator on trailer axle 3.";
CM_ SG_ 3221225472 TrailerBrakeStrokeAxle2Right "Brake stroke status for right brake actuator on trailer axle 2.";
CM_ SG_ 3221225472 TrailerBrakeStrokeAxle2Left "Brake stroke status for left brake actuator on trailer axle 2.";
CM_ SG_ 3221225472 TrailerBrakeStrokeAxle1Right "Brake stroke status for right brake actuator on trailer axle 1.";
CM_ SG_ 3221225472 TrailerBrakeStrokeAxle1Left "Brake stroke status for left brake actuator on trailerr axle 1.";
CM_ SG_ 3221225472 TractorBrakeStrokeAxle5Right "Brake stroke status for right brake actuator on tractor axle 5.";
CM_ SG_ 3221225472 TractorBrakeStrokeAxle5Left "Brake stroke status for left brake actuator on tractor axle 5.";
CM_ SG_ 3221225472 TractorBrakeStrokeAxle4Right "Brake stroke status for right brake actuator on tractor axle 4.";
CM_ SG_ 3221225472 TractorBrakeStrokeAxle4Left "Brake stroke status for left brake actuator on tractor axle 4.";
CM_ SG_ 3221225472 TractorBrakeStrokeAxle3Right "Brake stroke status for right brake actuator on tractor axle 3.";
CM_ SG_ 3221225472 TractorBrakeStrokeAxle3Left "Brake stroke status for left brake actuator on tractor axle 3.";
CM_ SG_ 3221225472 TractorBrakeStrokeAxle2Right "Brake stroke status for right brake actuator on tractor axle 2.";
CM_ SG_ 3221225472 TractorBrakeStrokeAxle2Left "Brake stroke status for left brake actuator on tractor axle 2.";
CM_ SG_ 3221225472 TractorBrakeStrokeAxle1Right "Brake stroke status for right brake actuator on tractor axle 1.";
CM_ SG_ 3221225472 TractorBrakeStrokeAxle1Left "Brake stroke status for left brake actuator on tractor axle 1.";
CM_ SG_ 3221225472 RoadSurfaceTemp "Indicated temperature of road surface over which vehicle is operating.";
CM_ SG_ 3221225472 EngAirInletTemp "Temperature of air entering vehicle air induction system.";
CM_ SG_ 3221225472 AmbientAirTemp "Temperature of air surrounding vehicle.";
CM_ SG_ 3221225472 CabInteriorTemp "Temperature of air inside the part of the vehicle that encloses the driver and vehicle operating controls.";
CM_ SG_ 3221225472 BarometricPress "Absolute air pressure of the atmosphere.";
CM_ SG_ 3221225472 AirCompressorStatus "Indicates whether the air compressor is actively compressing air.";
CM_ SG_ 3221225472 AirSuspensionSupplyPress "The pneumatic pressure in the circuit for the electronically controlled air suspension system.";
CM_ SG_ 3221225472 AuxEquipmentSupplyPress "The pneumatic pressure in the auxiliary circuit.";
CM_ SG_ 3221225472 ServiceBrakeAirPressCircuit2 "The pneumatic pressure in the service brake circuit or reservoir #2.";
CM_ SG_ 3221225472 ServiceBrakeAirPressCircuit1 "The pneumatic pressure in the service brake circuit or reservoir #1.";
CM_ SG_ 3221225472 ParkingAnd_OrTrailerAirPress "The pneumatic pressure in the circuit or reservoir for the parking brake and/or the trailer supply.";
CM_ SG_ 3221225472 PneumaticSupplyPress "The pneumatic pressure in the main reservoir, sometimes referred to as the wet tank.";
CM_ SG_ 3221225472 SteerAxleLubePress "The steering axle lubricant pressure.";
CM_ SG_ 3221225472 SteerAxleTemp "Temperature of lubricant in steering axle.";
CM_ SG_ 3221225472 DriveAxleLubePress "The drive axle lubricant pressure with location determined by Drive Axle Location (SPN 930).";
CM_ SG_ 3221225472 DriveAxleTemp "Temperature of axle lubricant in drive axle.";
CM_ SG_ 3221225472 DriveAxleLiftAirPress "Gage pressure of air in system that utilizes compressed air to provide force between axle and frame.";
CM_ SG_ 3221225472 DriveAxleLocation "To identify to which of several similar devices (such as tires or fuel tanks) the information applies.";
CM_ SG_ 3221225472 EngTurboWastegateValvePos "The position of the turbocharger wastegate valve (not the electronic wastegate control valve).";
CM_ SG_ 3221225472 EngDsiredAbsIntakeManifoldPress "The desired absolute intake manifold pressure of the engine.";
CM_ SG_ 3221225472 EngGasFuelCorrectionFactor "A correction to a predefined gaseous fuel energy (expressed in energy per unit volume) represented as a percentage.";
CM_ SG_ 3221225472 RqedACCDistanceMode "The Requested Distance Control Mode to the ACC system from the operators interface.";
CM_ SG_ 3221225472 ACCDistanceAlertSignal "Signal to indicate to the operator that the ACC system is not able to maintain the distance to the target.";
CM_ SG_ 3221225472 ACCSystemShutoffWarning "Signal to warn the driver of system deactivation due to non-driver actions.";
CM_ SG_ 3221225472 ACCTargetDetected "Signal to indicate to the driver that the ACC system has detected a target.";
CM_ SG_ 3221225472 AdptveCruiseCtrlSetDistanceMode "Selected distance mode for adaptive cruise control.";
CM_ SG_ 3221225472 AdaptiveCruiseCtrlMode "This parameter is used to indicate the current state, or mode, of operation by the Adaptive Cruise Control (ACC) device.";
CM_ SG_ 3221225472 AdaptiveCruiseCtrlSetSpeed "Value of the desired (chosen) velocity of the adaptive cruise control system.";
CM_ SG_ 3221225472 DistanceToForwardVehicle "Distance to the preceding vehicle situated within 250 m in the same lane and moving in the same direction.";
CM_ SG_ 3221225472 SpeedOfForwardVehicle "Absolute velocity of the preceding vehicle situated within 250 m in the same lane and moving in the same direction.";
CM_ SG_ 3221225472 ArticulationAngle "Angle of deflection of an articulated transit vehicle.";
CM_ SG_ 3221225472 RelativeHumidity "Measures humidity of combustion air prior to entry into turbocharger";
CM_ SG_ 3221225472 AuxLevel "Level measured by a sensor.";
CM_ SG_ 3221225472 AuxPress2 "Pressure measured by auxiliary pressure sensor #2.";
CM_ SG_ 3221225472 AuxPress1 "Pressure measured by auxiliary pressure sensor #1.";
CM_ SG_ 3221225472 AuxTemp2 "Temperature measured by auxiliary temperature sensor #2.";
CM_ SG_ 3221225472 AuxTemp1 "Temperature measured by auxiliary temperature sensor #1.";
CM_ SG_ 3221225472 EngBlowerBypassValvePos "Relative position of the blower bypass valve.";
CM_ SG_ 3221225472 EngGasSupplyPress "Gage pressure of gas supply to fuel metering device.";
CM_ SG_ 3221225472 Status2OfDoors "Composite indication of all bus door statuses.";
CM_ SG_ 3221225472 Ramp_WheelChairLiftPos "Signal which indicates the actual position of the ramp / wheel chair lift.";
CM_ SG_ 3221225472 PosOfDoors "Signal which indicates the actual position of the doors.";
CM_ SG_ 3221225472 FifthWheelRollWarningIndicator "Indicates to the vehicle operator that the roll moment has exceeded a preset limit.";
CM_ SG_ 3221225472 FifthWheelRollMoment "Fifth wheel roll moment force.";
CM_ SG_ 3221225472 FifthWheelDrawbarForce "Fifth wheel drawbar force.";
CM_ SG_ 3221225472 FifthWheelVerticalForce "Fifth wheel vertical force.";
CM_ SG_ 3221225472 FifthWheelSliderLockIndicator "Indicates to vehicle operator that the fifth wheel slider is in position and locked.";
CM_ SG_ 3221225472 FifthWheelSliderPos "Slider position measurement.";
CM_ SG_ 3221225472 FfthWhlLckCoupleStatusIndicator "Indicates results of coupling operation to the vehicle operator.";
CM_ SG_ 3221225472 FfthWhlLckRadyToCoupleIndicator "Indicates to the vehicle operator that the fifth wheel lock is open and ready to couple.";
CM_ SG_ 3221225472 FifthWheelErrorStatus "Fifth wheel error state conveys information when coupling status is incomplete or bad.";
CM_ SG_ 3221225472 RollAndPitchMeasurementLatency "The estimated measurement latency of the measurement.";
CM_ SG_ 3221225472 PitchAndRollCompensated "Compensated mode for the pitch and roll measurements.";
CM_ SG_ 3221225472 PitchRateFigureOfMerit "Figure of merit for the pitch rate measurement.";
CM_ SG_ 3221225472 RollAngleFigureOfMerit "Figure of merit for roll angle measurement.";
CM_ SG_ 3221225472 PitchAngleFigureOfMerit "Figure of merit for pitch angle measurement.";
CM_ SG_ 3221225472 RollAngle "The angle between the vehicle y-axis and the ground plane.";
CM_ SG_ 3221225472 PitchAngle "The angle between the vehicle x-axis and the ground plane.";
CM_ SG_ 3221225472 TransOilLevelHigh_Low "Amount of current volume of transmission sump oil compared to recommended volume.";
CM_ SG_ 3221225472 TransOilTemp "Temperature of the transmission lubricant.";
CM_ SG_ 3221225472 TransOilPress "Gage pressure of lubrication fluid in transmission, measured after pump.";
CM_ SG_ 3221225472 TransOilLevel "Ratio of volume of transmission sump oil to recommended volume.";
CM_ SG_ 3221225472 ClutchPress "Gage pressure of oil within a wet clutch.";
CM_ SG_ 3221225472 BatteryPotentialSwitched "Electrical potential measured at the input of the electronic control unit supplied through a switching device.";
CM_ SG_ 3221225472 ElectricalPotential "Measured electrical potential of the battery.";
CM_ SG_ 3221225472 ChargingSystemPotential "Electrical potential measured at the charging system output.";
CM_ SG_ 3221225472 AltCurrent "Measure of electrical current flow from the alternator.";
CM_ SG_ 3221225472 NetBatteryCurrent "Net flow of electrical current into/out of the battery or batteries.";
CM_ SG_ 3221225472 NetworkSignalStrength2 "Indicates the signal strength for the wireless communications network type.";
CM_ SG_ 3221225472 NetworkSignalStrength1 "Indicates the signal strength for the wireless communications network type.";
CM_ SG_ 3221225472 VoltageRegulatorEnabled "State signal indicating the Voltage regulator enabled.";
CM_ SG_ 3221225472 VoltageRegulatorSoftStartState "State signal indicating the mode of the Voltage regulator soft start function.";
CM_ SG_ 3221225472 VltgRgltrUndrfrqncyCmpnstnEnbld "State signal indicating the operating mode for underfrequency compensation.";
CM_ SG_ 3221225472 VltgRglatorLoadCompensationMode "State signal indicating the voltage regulator load compensation mode.";
CM_ SG_ 3221225472 GeneratorExcitationFieldCurrent "Measured signal that represents the generator excitation field current.";
CM_ SG_ 3221225472 GeneratorExcitationFieldVoltage "Measured signal that represents the generator excitation field voltage.";
CM_ BO_ 2566763776 "Previously Active Emission Related Faults
This message contains DTCs that are confirmed but for which the MIL is off.";
CM_ SG_ 2566763776 SPN_High4 "3 most significant bits of SPN (most significant at bit 8) ";
CM_ SG_ 2566763776 SPN_High3 "3 most significant bits of SPN (most significant at bit 8) ";
CM_ SG_ 2566763776 SPN_High5 "3 most significant bits of SPN (most significant at bit 8) ";
CM_ SG_ 2566763776 SPN_High2 "3 most significant bits of SPN (most significant at bit 8) ";
CM_ SG_ 2566763776 SPN_High1 "3 most significant bits of SPN (most significant at bit 8) ";
CM_ SG_ 2566763776 SpnConversionMethod1 "If set to '0', the document is converted according to version 4 of the J1939-73 document (February 1996); otherwise, it is converted according to one of the three earlier versions.";
CM_ SG_ 2566763776 SpnConversionMethod5 "If set to '0', the document is converted according to version 4 of the J1939-73 document (February 1996); otherwise, it is converted according to one of the three earlier versions.";
CM_ SG_ 2566763776 SpnConversionMethod4 "If set to '0', the document is converted according to version 4 of the J1939-73 document (February 1996); otherwise, it is converted according to one of the three earlier versions.";
CM_ SG_ 2566763776 SpnConversionMethod3 "If set to '0', the document is converted according to version 4 of the J1939-73 document (February 1996); otherwise, it is converted according to one of the three earlier versions.";
CM_ SG_ 2566763776 SpnConversionMethod2 "If set to '0', the document is converted according to version 4 of the J1939-73 document (February 1996); otherwise, it is converted according to one of the three earlier versions.";
CM_ SG_ 2566763776 OccurenceCount5 "Contains the number of times a fault has been independently detected.";
CM_ SG_ 2566763776 OccurenceCount4 "Contains the number of times a fault has been independently detected.";
CM_ SG_ 2566763776 OccurenceCount3 "Contains the number of times a fault has been independently detected.";
CM_ SG_ 2566763776 OccurenceCount2 "Contains the number of times a fault has been independently detected.";
CM_ SG_ 2566763776 OccurenceCount1 "Contains the number of times a fault has been independently detected.";
CM_ SG_ 2566763776 FMI5 "The FMI defines the type of failure detected in the subsystem identified by an SPN.";
CM_ SG_ 2566763776 FMI4 "The FMI defines the type of failure detected in the subsystem identified by an SPN.";
CM_ SG_ 2566763776 FMI3 "The FMI defines the type of failure detected in the subsystem identified by an SPN.";
CM_ SG_ 2566763776 FMI2 "The FMI defines the type of failure detected in the subsystem identified by an SPN.";
CM_ SG_ 2566763776 FMI1 "The FMI defines the type of failure detected in the subsystem identified by an SPN.";
CM_ SG_ 2566763776 FlashRedStopLamp "This parameter provides the capability to flash the RSL


00 - Slow Flash (1 Hz, 50 % duty cycle)
01 - Fast Flash (2 Hz or faster, 50% duty cycle)
10 - Reserved
11 - Unavailable / Do Not Flash";
CM_ SG_ 2566763776 FlashProtectLamp "This parameter provides the capability to flash the engine protect lamp


00 - Slow Flash (1 Hz, 50 % duty cycle)
01 - Fast Flash (2 Hz or faster, 50% duty cycle)
10 - Reserved
11 - Unavailable / Do Not Flash";
CM_ SG_ 2566763776 FlashMalfuncIndicatorLamp "This parameter provides the capability to flash the MIL
00 - Slow Flash (1 Hz, 50 % duty cycle)
01 - Fast Flash (2 Hz or faster, 50% duty cycle)
10 - Class C DTC
11 - Unavailable / Do Not Flash
Note:  State 10 is for WWH OBD discriminatory ...";
CM_ SG_ 2566763776 FlashAmberWarningLamp "This parameter provides the capability to flash the AWL

00 - Slow Flash (1 Hz, 50 % duty cycle)
01 - Fast Flash (2 Hz or faster, 50% duty cycle)
10 - Reserved
11 - Unavailable / Do Not Flash";
CM_ SG_ 2566763776 MalfunctionIndLampStatus "A lamp used to relay only emissions-related trouble code information. This lamp is only illuminated when there is an emission-related trouble code active.
00     Lamp Off
01     Lamp On
10     Short MIL for WWH OBD
11     Not available
Note ...";
CM_ SG_ 2566763776 AmberWarningLampStatus "This lamp is used to relay trouble code information that is reporting a problem with the vehicle system but the vehicle need not be immediately stopped. 

00     Lamp Off
01     Lamp On
10     Reserved
11     Not available";
CM_ SG_ 2566763776 RedStopLampState "This lamp is used to relay trouble code information that is of a severe enough condition that it warrants stopping the vehicle.

00     Lamp Off
01     Lamp On
10     Reserved
11     Not available";
CM_ SG_ 2566763776 ProtectLampStatus "This lamp is used to relay trouble code information that is reporting a problem with a vehicle system that is most probably not electronic subsystem related. For instance, engine coolant temperature is exceeding its prescribed temperature range.
00 ...";
CM_ SG_ 2566763776 SPN5 "16 least significant bits of SPN";
CM_ SG_ 2566763776 SPN4 "16 least significant bits of SPN";
CM_ SG_ 2566763776 SPN3 "16 least significant bits of SPN";
CM_ SG_ 2566763776 SPN2 "16 least significant bits of SPN";
CM_ SG_ 2566763776 SPN1 "16 least significant bits of SPN";
CM_ BO_ 2365213438 "Continuous-MI Time While Engine Operating. 
This is the same amount of time defined in DM21 SPN 3295 (see 5.7.21.3) but broadcast in units of hours.";
CM_ SG_ 2365213438 ControllerIdType "Controller Identity Type specifies the content of the Controller Identity Body. ";
CM_ SG_ 2365213438 DtcType "The DTC Type value identifies the type of the specified DTC according to the DM message in which the DTC has been 
reported.";
CM_ SG_ 2365213438 OccurenceCount "Contains the number of times a fault has been independently detected.";
CM_ SG_ 2365213438 SpnConversionMethod "If set to '0', the document is converted according to version 4 of the J1939-73 document (February 1996); otherwise, it is converted according to one of the three earlier versions.";
CM_ SG_ 2365213438 FMI "Failure Mode Identifier (FMI) 
The FMI defines the type of failure detected in the sub-system identified by an SPN.";
CM_ SG_ 2365213438 SPN_High "3 most significant bits of SPN (most significant at bit 8) ";
CM_ SG_ 2365213438 SPN "16 least significant bits of SPN";
CM_ BO_ 2365271294 "Diagnostic Readiness 4.
Reports the diagnostic information relevant to a fourth PG conveying diagnostic readiness.";
CM_ BO_ 2365316094 "Rationality Fault SP Data.
The rationality fault SP data value reported in a DM58 message provides a scaled value representing the 
measurement that was detected to be in error, when a rationality fault was detected for the measured SP.";
CM_ SG_ 2365316094 RationalityFaultSPN_High "3 most significant bits of SPN (most significant at bit 8) ";
CM_ SG_ 2365316094 RationalityFaultSPN "16 least significant bits of SPN";
CM_ SG_ 2365316094 TestIdentifier "The TID has 2 methods to designate the test to be run. The first method uses the TID alone and these test identifiers are manufacturer-defined test identifiers. For this first use there are 64 valid test identifiers, 1 to 64. The second method uses ...";
CM_ BO_ 2566702846 "OBD Information";
CM_ SG_ 2566702846 EngOBDWarmUpSequence "Engine warm-up as defined by the applicable region's regulatory agency.  In the US, \"Engine OBD Warm-up\" or “Warm-up cycle” means sufficient vehicle operation such that coolant temperature rises by at least 22.2 °C (40 °F) from engine starting and ...";
CM_ BO_ 2566703102 "Engine Emissions Certification Information";
CM_ SG_ 2566703102 CertificationEngineFamilyName "The regulated family name per the applicable region's certification agency.  For engines certified in the US, this shall be the 12-character engine family name or test group as defined by EPA.  Up to 200 characters may be used.  The characters are ...";
CM_ SG_ 2566703102 ModelYear "The compliance model year of the OBD system of the engine and or vehicle.  For example in the US, this is associated with either a vehicle model year or an engine model year, depending on how the emissions and OBD are certified.  This message shall ...";
CM_ BO_ 2566706174 "Diagnostic Data Clear/Reset for All Service Only DTCs
All of the diagnostic information pertaining to the active service only diagnostic trouble codes and previously active diagnostic trouble codes should be erased as well as the DTCs.";
BA_DEF_ SG_  "SigType" ENUM  "Default","Range","RangeSigned","ASCII","Discrete","Control","ReferencePGN","DTC","StringDelimiter","StringLength","StringLengthControl","MessageCounter","MessageChecksum","LowerPartOfSPN";
BA_DEF_ SG_  "GenSigStartValue" INT 0 10000;
BA_DEF_ SG_  "GenSigSendType" ENUM  "Cyclic","OnWrite","OnWriteWithRepetition","OnChange","OnChangeWithRepetition","IfActive","IfActiveWithRepetition","NoSigSendType";
BA_DEF_ SG_  "GenSigILSupport" ENUM  "No","Yes";
BA_DEF_ SG_  "GenSigEVName" STRING ;
BA_DEF_ SG_  "SPN" INT 0 524287;
BA_DEF_ BO_  "GenMsgStartDelayTime" INT 0 100000;
BA_DEF_ BO_  "GenMsgILSupport" ENUM  "No","Yes";
BA_DEF_ BO_  "GenMsgDelayTime" INT 0 1000;
BA_DEF_ BO_  "GenMsgRequestable" INT 0 1;
BA_DEF_ BO_  "GenMsgSendType" ENUM  "cyclic","NotUsed","NotUsed","NotUsed","NotUsed","NotUsed","NotUsed","IfActive","noMsgSendType";
BA_DEF_ BO_  "VFrameFormat" ENUM  "StandardCAN","ExtendedCAN","reserved","J1939PG";
BA_DEF_ BO_  "GenMsgCycleTime" INT 0 3600000;
BA_DEF_ SG_  "SystemSignalLongSymbol" STRING ;
BA_DEF_DEF_  "SigType" "Default";
BA_DEF_DEF_  "GenSigStartValue" 0;
BA_DEF_DEF_  "GenSigSendType" "NoSigSendType";
BA_DEF_DEF_  "GenSigILSupport" "Yes";
BA_DEF_DEF_  "GenSigEVName" "Env@Nodename_@Signame";
BA_DEF_DEF_  "SPN" 0;
BA_DEF_DEF_  "GenMsgStartDelayTime" 0;
BA_DEF_DEF_  "GenMsgILSupport" "Yes";
BA_DEF_DEF_  "GenMsgDelayTime" 0;
BA_DEF_DEF_  "GenMsgRequestable" 1;
BA_DEF_DEF_  "GenMsgSendType" "noMsgSendType";
BA_DEF_DEF_  "VFrameFormat" "J1939PG";
BA_DEF_DEF_  "GenMsgCycleTime" 0;
BA_DEF_DEF_  "SystemSignalLongSymbol" "";
BA_ "SigType" SG_ 3221225472 RedStopLampState 4;
BA_ "SPN" SG_ 3221225472 RedStopLampState 623;
BA_ "SigType" SG_ 3221225472 AmberWarningLampStatus 4;
BA_ "SPN" SG_ 3221225472 AmberWarningLampStatus 624;
BA_ "SigType" SG_ 3221225472 ProtectLampStatus 4;
BA_ "SPN" SG_ 3221225472 ProtectLampStatus 987;
BA_ "SigType" SG_ 3221225472 DTC5 7;
BA_ "SigType" SG_ 3221225472 DTC4 7;
BA_ "SigType" SG_ 3221225472 DTC3 7;
BA_ "SigType" SG_ 3221225472 DTC2 7;
BA_ "SigType" SG_ 3221225472 UtlityOverallPowerFactorLagging 4;
BA_ "SPN" SG_ 3221225472 UtlityOverallPowerFactorLagging 2522;
BA_ "SigType" SG_ 3221225472 UtilityOverallPowerFactor 1;
BA_ "SPN" SG_ 3221225472 UtilityOverallPowerFactor 2498;
BA_ "SigType" SG_ 3221225472 UtilityTotalReactivePower 1;
BA_ "SPN" SG_ 3221225472 UtilityTotalReactivePower 2490;
BA_ "SigType" SG_ 3221225472 UtilityTotalApparentPower 1;
BA_ "SPN" SG_ 3221225472 UtilityTotalApparentPower 2494;
BA_ "SigType" SG_ 3221225472 UtilityTotalRealPower 1;
BA_ "SPN" SG_ 3221225472 UtilityTotalRealPower 2486;
BA_ "SigType" SG_ 3221225472 UtilityTotalKWHoursImport 4;
BA_ "SPN" SG_ 3221225472 UtilityTotalKWHoursImport 2503;
BA_ "SigType" SG_ 3221225472 UtilityTotalKWHoursExport 4;
BA_ "SPN" SG_ 3221225472 UtilityTotalKWHoursExport 2502;
BA_ "SigType" SG_ 3221225472 UtilityPhaseCPowerFactorLagging 4;
BA_ "SPN" SG_ 3221225472 UtilityPhaseCPowerFactorLagging 2525;
BA_ "SigType" SG_ 3221225472 UtilityPhaseCPowerFactor 1;
BA_ "SPN" SG_ 3221225472 UtilityPhaseCPowerFactor 2501;
BA_ "SigType" SG_ 3221225472 UtilityPhaseCReactivePower 1;
BA_ "SPN" SG_ 3221225472 UtilityPhaseCReactivePower 2493;
BA_ "SigType" SG_ 3221225472 UtilityPhaseCApparentPower 1;
BA_ "SPN" SG_ 3221225472 UtilityPhaseCApparentPower 2497;
BA_ "SigType" SG_ 3221225472 UtilityPhaseCRealPower 1;
BA_ "SPN" SG_ 3221225472 UtilityPhaseCRealPower 2489;
BA_ "SigType" SG_ 3221225472 UtilityPhaseCACRMSCurrent 1;
BA_ "SPN" SG_ 3221225472 UtilityPhaseCACRMSCurrent 2485;
BA_ "SigType" SG_ 3221225472 UtilityPhaseCACFrequency 1;
BA_ "SPN" SG_ 3221225472 UtilityPhaseCACFrequency 2473;
BA_ "SigType" SG_ 3221225472 UtltyPhsCLneNeutralACRMSVoltage 1;
BA_ "SPN" SG_ 3221225472 UtltyPhsCLneNeutralACRMSVoltage 2481;
BA_ "SigType" SG_ 3221225472 UtltyPhseCALineLineACRMSVoltage 1;
BA_ "SPN" SG_ 3221225472 UtltyPhseCALineLineACRMSVoltage 2477;
BA_ "SigType" SG_ 3221225472 UtilityPhaseBPowerFactorLagging 4;
BA_ "SPN" SG_ 3221225472 UtilityPhaseBPowerFactorLagging 2524;
BA_ "SigType" SG_ 3221225472 UtilityPhaseBPowerFactor 1;
BA_ "SPN" SG_ 3221225472 UtilityPhaseBPowerFactor 2500;
BA_ "SigType" SG_ 3221225472 UtilityPhaseBReactivePower 1;
BA_ "SPN" SG_ 3221225472 UtilityPhaseBReactivePower 2492;
BA_ "SigType" SG_ 3221225472 UtilityPhaseBApparentPower 1;
BA_ "SPN" SG_ 3221225472 UtilityPhaseBApparentPower 2496;
BA_ "SigType" SG_ 3221225472 UtilityPhaseBRealPower 1;
BA_ "SPN" SG_ 3221225472 UtilityPhaseBRealPower 2488;
BA_ "SigType" SG_ 3221225472 UtilityPhaseBACRMSCurrent 1;
BA_ "SPN" SG_ 3221225472 UtilityPhaseBACRMSCurrent 2484;
BA_ "SigType" SG_ 3221225472 UtilityPhaseBACFrequency 1;
BA_ "SPN" SG_ 3221225472 UtilityPhaseBACFrequency 2472;
BA_ "SigType" SG_ 3221225472 UtltyPhsBLneNeutralACRMSVoltage 1;
BA_ "SPN" SG_ 3221225472 UtltyPhsBLneNeutralACRMSVoltage 2480;
BA_ "SigType" SG_ 3221225472 UtltyPhseBCLineLineACRMSVoltage 1;
BA_ "SPN" SG_ 3221225472 UtltyPhseBCLineLineACRMSVoltage 2476;
BA_ "SigType" SG_ 3221225472 UtilityPhaseAPowerFactorLagging 4;
BA_ "SPN" SG_ 3221225472 UtilityPhaseAPowerFactorLagging 2523;
BA_ "SigType" SG_ 3221225472 UtilityPhaseAPowerFactor 1;
BA_ "SPN" SG_ 3221225472 UtilityPhaseAPowerFactor 2499;
BA_ "SigType" SG_ 3221225472 UtilityPhaseAReactivePower 1;
BA_ "SPN" SG_ 3221225472 UtilityPhaseAReactivePower 2491;
BA_ "SigType" SG_ 3221225472 UtilityPhaseAApparentPower 1;
BA_ "SPN" SG_ 3221225472 UtilityPhaseAApparentPower 2495;
BA_ "SigType" SG_ 3221225472 UtilityPhaseARealPower 1;
BA_ "SPN" SG_ 3221225472 UtilityPhaseARealPower 2487;
BA_ "SigType" SG_ 3221225472 UtilityPhaseAACRMSCurrent 1;
BA_ "SPN" SG_ 3221225472 UtilityPhaseAACRMSCurrent 2483;
BA_ "SigType" SG_ 3221225472 UtilityPhaseAACFrequency 1;
BA_ "SPN" SG_ 3221225472 UtilityPhaseAACFrequency 2471;
BA_ "SigType" SG_ 3221225472 UtltyPhsALneNeutralACRMSVoltage 1;
BA_ "SPN" SG_ 3221225472 UtltyPhsALneNeutralACRMSVoltage 2479;
BA_ "SigType" SG_ 3221225472 UtltyPhseABLineLineACRMSVoltage 1;
BA_ "SPN" SG_ 3221225472 UtltyPhseABLineLineACRMSVoltage 2475;
BA_ "SigType" SG_ 3221225472 UtilityAverageACRMSCurrent 1;
BA_ "SPN" SG_ 3221225472 UtilityAverageACRMSCurrent 2482;
BA_ "SigType" SG_ 3221225472 UtilityAverageACFrequency 1;
BA_ "SPN" SG_ 3221225472 UtilityAverageACFrequency 2470;
BA_ "SigType" SG_ 3221225472 UtltyAvrgLneNeutralACRMSVoltage 1;
BA_ "SPN" SG_ 3221225472 UtltyAvrgLneNeutralACRMSVoltage 2478;
BA_ "SigType" SG_ 3221225472 UtltyAvrageLineLineACRMSVoltage 1;
BA_ "SPN" SG_ 3221225472 UtltyAvrageLineLineACRMSVoltage 2474;
BA_ "SigType" SG_ 3221225472 GnrtorOverallPowerFactorLagging 4;
BA_ "SPN" SG_ 3221225472 GnrtorOverallPowerFactorLagging 2518;
BA_ "SigType" SG_ 3221225472 GeneratorOverallPowerFactor 1;
BA_ "SPN" SG_ 3221225472 GeneratorOverallPowerFactor 2464;
BA_ "SigType" SG_ 3221225472 GeneratorTotalReactivePower 1;
BA_ "SPN" SG_ 3221225472 GeneratorTotalReactivePower 2456;
BA_ "SigType" SG_ 3221225472 GeneratorTotalApparentPower 1;
BA_ "SPN" SG_ 3221225472 GeneratorTotalApparentPower 2460;
BA_ "SigType" SG_ 3221225472 GeneratorTotalRealPower 1;
BA_ "SPN" SG_ 3221225472 GeneratorTotalRealPower 2452;
BA_ "SigType" SG_ 3221225472 GeneratorTotalKWHoursImport 4;
BA_ "SPN" SG_ 3221225472 GeneratorTotalKWHoursImport 2469;
BA_ "SigType" SG_ 3221225472 GeneratorTotalKWHoursExport 4;
BA_ "SPN" SG_ 3221225472 GeneratorTotalKWHoursExport 2468;
BA_ "SigType" SG_ 3221225472 GnratorPhaseCPowerFactorLagging 4;
BA_ "SPN" SG_ 3221225472 GnratorPhaseCPowerFactorLagging 2521;
BA_ "SigType" SG_ 3221225472 GeneratorPhaseCPowerFactor 1;
BA_ "SPN" SG_ 3221225472 GeneratorPhaseCPowerFactor 2467;
BA_ "SigType" SG_ 3221225472 GeneratorPhaseCReactivePower 1;
BA_ "SPN" SG_ 3221225472 GeneratorPhaseCReactivePower 2459;
BA_ "SigType" SG_ 3221225472 GeneratorPhaseCApparentPower 1;
BA_ "SPN" SG_ 3221225472 GeneratorPhaseCApparentPower 2463;
BA_ "SigType" SG_ 3221225472 GeneratorPhaseCRealPower 1;
BA_ "SPN" SG_ 3221225472 GeneratorPhaseCRealPower 2455;
BA_ "SigType" SG_ 3221225472 GeneratorPhaseCACRMSCurrent 1;
BA_ "SPN" SG_ 3221225472 GeneratorPhaseCACRMSCurrent 2451;
BA_ "SigType" SG_ 3221225472 GeneratorPhaseCACFrequency 1;
BA_ "SPN" SG_ 3221225472 GeneratorPhaseCACFrequency 2439;
BA_ "SigType" SG_ 3221225472 GnrtrPhsCLneNeutralACRMSVoltage 1;
BA_ "SPN" SG_ 3221225472 GnrtrPhsCLneNeutralACRMSVoltage 2447;
BA_ "SigType" SG_ 3221225472 GnrtrPhseCALineLineACRMSVoltage 1;
BA_ "SPN" SG_ 3221225472 GnrtrPhseCALineLineACRMSVoltage 2443;
BA_ "SigType" SG_ 3221225472 GnratorPhaseBPowerFactorLagging 4;
BA_ "SPN" SG_ 3221225472 GnratorPhaseBPowerFactorLagging 2520;
BA_ "SigType" SG_ 3221225472 GeneratorPhaseBPowerFactor 1;
BA_ "SPN" SG_ 3221225472 GeneratorPhaseBPowerFactor 2466;
BA_ "SigType" SG_ 3221225472 GeneratorPhaseBReactivePower 1;
BA_ "SPN" SG_ 3221225472 GeneratorPhaseBReactivePower 2458;
BA_ "SigType" SG_ 3221225472 GeneratorPhaseBApparentPower 1;
BA_ "SPN" SG_ 3221225472 GeneratorPhaseBApparentPower 2462;
BA_ "SigType" SG_ 3221225472 GeneratorPhaseBRealPower 1;
BA_ "SPN" SG_ 3221225472 GeneratorPhaseBRealPower 2454;
BA_ "SigType" SG_ 3221225472 GeneratorPhaseBACRMSCurrent 1;
BA_ "SPN" SG_ 3221225472 GeneratorPhaseBACRMSCurrent 2450;
BA_ "SigType" SG_ 3221225472 GeneratorPhaseBACFrequency 1;
BA_ "SPN" SG_ 3221225472 GeneratorPhaseBACFrequency 2438;
BA_ "SigType" SG_ 3221225472 GnrtrPhsBLneNeutralACRMSVoltage 1;
BA_ "SPN" SG_ 3221225472 GnrtrPhsBLneNeutralACRMSVoltage 2446;
BA_ "SigType" SG_ 3221225472 GnrtrPhseBCLineLineACRMSVoltage 1;
BA_ "SPN" SG_ 3221225472 GnrtrPhseBCLineLineACRMSVoltage 2442;
BA_ "SigType" SG_ 3221225472 GnratorPhaseAPowerFactorLagging 4;
BA_ "SPN" SG_ 3221225472 GnratorPhaseAPowerFactorLagging 2519;
BA_ "SigType" SG_ 3221225472 GeneratorPhaseAPowerFactor 1;
BA_ "SPN" SG_ 3221225472 GeneratorPhaseAPowerFactor 2465;
BA_ "SigType" SG_ 3221225472 GeneratorPhaseAReactivePower 1;
BA_ "SPN" SG_ 3221225472 GeneratorPhaseAReactivePower 2457;
BA_ "SigType" SG_ 3221225472 GeneratorPhaseAApparentPower 1;
BA_ "SPN" SG_ 3221225472 GeneratorPhaseAApparentPower 2461;
BA_ "SigType" SG_ 3221225472 GeneratorPhaseARealPower 1;
BA_ "SPN" SG_ 3221225472 GeneratorPhaseARealPower 2453;
BA_ "SigType" SG_ 3221225472 GeneratorPhaseAACRMSCurrent 1;
BA_ "SPN" SG_ 3221225472 GeneratorPhaseAACRMSCurrent 2449;
BA_ "SigType" SG_ 3221225472 GeneratorPhaseAACFrequency 1;
BA_ "SPN" SG_ 3221225472 GeneratorPhaseAACFrequency 2437;
BA_ "SigType" SG_ 3221225472 GnrtrPhsALneNeutralACRMSVoltage 1;
BA_ "SPN" SG_ 3221225472 GnrtrPhsALneNeutralACRMSVoltage 2445;
BA_ "SigType" SG_ 3221225472 GnrtrPhseABLineLineACRMSVoltage 1;
BA_ "SPN" SG_ 3221225472 GnrtrPhseABLineLineACRMSVoltage 2441;
BA_ "SigType" SG_ 3221225472 GeneratorAverageACRMSCurrent 1;
BA_ "SPN" SG_ 3221225472 GeneratorAverageACRMSCurrent 2448;
BA_ "SigType" SG_ 3221225472 GeneratorAverageACFrequency 1;
BA_ "SPN" SG_ 3221225472 GeneratorAverageACFrequency 2436;
BA_ "SigType" SG_ 3221225472 GnrtrAvrgLneNeutralACRMSVoltage 1;
BA_ "SPN" SG_ 3221225472 GnrtrAvrgLneNeutralACRMSVoltage 2444;
BA_ "SigType" SG_ 3221225472 GnrtrAvrageLineLineACRMSVoltage 1;
BA_ "SPN" SG_ 3221225472 GnrtrAvrageLineLineACRMSVoltage 2440;
BA_ "SigType" SG_ 3221225472 Bus1_UtilityACPhaseDifference 1;
BA_ "SPN" SG_ 3221225472 Bus1_UtilityACPhaseDifference 2517;
BA_ "SigType" SG_ 3221225472 Bus1_UtilityInSync 4;
BA_ "SPN" SG_ 3221225472 Bus1_UtilityInSync 2534;
BA_ "SigType" SG_ 3221225472 Bus1_UtilityVoltageMatch 4;
BA_ "SPN" SG_ 3221225472 Bus1_UtilityVoltageMatch 2532;
BA_ "SigType" SG_ 3221225472 Bus1_UtilityFrequencyMatch 4;
BA_ "SPN" SG_ 3221225472 Bus1_UtilityFrequencyMatch 2533;
BA_ "SigType" SG_ 3221225472 Bus1_UtilityPhaseMatch 4;
BA_ "SPN" SG_ 3221225472 Bus1_UtilityPhaseMatch 2531;
BA_ "SigType" SG_ 3221225472 Bus1_UtilityDeadBus 4;
BA_ "SPN" SG_ 3221225472 Bus1_UtilityDeadBus 2535;
BA_ "SigType" SG_ 3221225472 Bus1PhaseCACFrequency 1;
BA_ "SPN" SG_ 3221225472 Bus1PhaseCACFrequency 2507;
BA_ "SigType" SG_ 3221225472 Bs1PhseCLineNeutralACRMSVoltage 1;
BA_ "SPN" SG_ 3221225472 Bs1PhseCLineNeutralACRMSVoltage 2515;
BA_ "SigType" SG_ 3221225472 Bus1PhaseCALineLineACRMSVoltage 1;
BA_ "SPN" SG_ 3221225472 Bus1PhaseCALineLineACRMSVoltage 2511;
BA_ "SigType" SG_ 3221225472 Bus1PhaseBACFrequency 1;
BA_ "SPN" SG_ 3221225472 Bus1PhaseBACFrequency 2506;
BA_ "SigType" SG_ 3221225472 Bs1PhseBLineNeutralACRMSVoltage 1;
BA_ "SPN" SG_ 3221225472 Bs1PhseBLineNeutralACRMSVoltage 2514;
BA_ "SigType" SG_ 3221225472 Bus1PhaseBCLineLineACRMSVoltage 1;
BA_ "SPN" SG_ 3221225472 Bus1PhaseBCLineLineACRMSVoltage 2510;
BA_ "SigType" SG_ 3221225472 Bus1PhaseAACFrequency 1;
BA_ "SPN" SG_ 3221225472 Bus1PhaseAACFrequency 2505;
BA_ "SigType" SG_ 3221225472 Bs1PhseALineNeutralACRMSVoltage 1;
BA_ "SPN" SG_ 3221225472 Bs1PhseALineNeutralACRMSVoltage 2513;
BA_ "SigType" SG_ 3221225472 Bus1PhaseABLineLineACRMSVoltage 1;
BA_ "SPN" SG_ 3221225472 Bus1PhaseABLineLineACRMSVoltage 2509;
BA_ "SigType" SG_ 3221225472 Bus1_GeneratorACPhaseDifference 1;
BA_ "SPN" SG_ 3221225472 Bus1_GeneratorACPhaseDifference 2516;
BA_ "SigType" SG_ 3221225472 Bus1_GeneratorInSync 4;
BA_ "SPN" SG_ 3221225472 Bus1_GeneratorInSync 2529;
BA_ "SigType" SG_ 3221225472 Bus1_GeneratorVoltageMatch 4;
BA_ "SPN" SG_ 3221225472 Bus1_GeneratorVoltageMatch 2527;
BA_ "SigType" SG_ 3221225472 Bus1_GeneratorFrequencyMatch 4;
BA_ "SPN" SG_ 3221225472 Bus1_GeneratorFrequencyMatch 2528;
BA_ "SigType" SG_ 3221225472 Bus1_GeneratorPhaseMatch 4;
BA_ "SPN" SG_ 3221225472 Bus1_GeneratorPhaseMatch 2526;
BA_ "SigType" SG_ 3221225472 Bus1_GeneratorDeadBus 4;
BA_ "SPN" SG_ 3221225472 Bus1_GeneratorDeadBus 2530;
BA_ "SigType" SG_ 3221225472 Bus1AverageACFrequency 1;
BA_ "SPN" SG_ 3221225472 Bus1AverageACFrequency 2504;
BA_ "SigType" SG_ 3221225472 Bs1AvrgeLineNeutralACRMSVoltage 1;
BA_ "SPN" SG_ 3221225472 Bs1AvrgeLineNeutralACRMSVoltage 2512;
BA_ "SigType" SG_ 3221225472 Bus1AverageLineLineACRMSVoltage 1;
BA_ "SPN" SG_ 3221225472 Bus1AverageLineLineACRMSVoltage 2508;
BA_ "SigType" SG_ 3221225472 NumberOfMembers 3;
BA_ "SigType" SG_ 3221225472 AddressAssignment 1;
BA_ "SPN" SG_ 3221225472 AddressAssignment 2847;
BA_ "SigType" SG_ 3221225472 ManufacturerCode 1;
BA_ "SPN" SG_ 3221225472 AxleGroupWeight 409;
BA_ "SPN" SG_ 3221225472 AxleGroupLocation 4074;
BA_ "SPN" SG_ 3221225472 AxleGroupFullWeightCalib 407;
BA_ "SPN" SG_ 3221225472 AxleGroupEmptyWeightCalib 408;
BA_ "SPN" SG_ 3221225472 DsrdAftrclrClntThrmostatOpening 4200;
BA_ "SPN" SG_ 3221225472 DsrdAftercoolerCoolantInletTemp 4199;
BA_ "SPN" SG_ 3221225472 AftrcoolerCoolantThermostatMode 4198;
BA_ "SPN" SG_ 3221225472 AddtnlTrlrAxlGrpWeightAvailable 4072;
BA_ "SigType" SG_ 3221225472 TrilerHAxleGroupWeightAvailable 4;
BA_ "SPN" SG_ 3221225472 TrilerHAxleGroupWeightAvailable 4071;
BA_ "SigType" SG_ 3221225472 TrilerGAxleGroupWeightAvailable 4;
BA_ "SPN" SG_ 3221225472 TrilerGAxleGroupWeightAvailable 4070;
BA_ "SigType" SG_ 3221225472 TrilerFAxleGroupWeightAvailable 4;
BA_ "SPN" SG_ 3221225472 TrilerFAxleGroupWeightAvailable 4069;
BA_ "SigType" SG_ 3221225472 TrilerEAxleGroupWeightAvailable 4;
BA_ "SPN" SG_ 3221225472 TrilerEAxleGroupWeightAvailable 4068;
BA_ "SigType" SG_ 3221225472 TrilerDAxleGroupWeightAvailable 4;
BA_ "SPN" SG_ 3221225472 TrilerDAxleGroupWeightAvailable 4067;
BA_ "SigType" SG_ 3221225472 TrilerCAxleGroupWeightAvailable 4;
BA_ "SPN" SG_ 3221225472 TrilerCAxleGroupWeightAvailable 4066;
BA_ "SigType" SG_ 3221225472 TrilerBAxleGroupWeightAvailable 4;
BA_ "SPN" SG_ 3221225472 TrilerBAxleGroupWeightAvailable 4065;
BA_ "SigType" SG_ 3221225472 TrilerAAxleGroupWeightAvailable 4;
BA_ "SPN" SG_ 3221225472 TrilerAAxleGroupWeightAvailable 4064;
BA_ "SPN" SG_ 3221225472 AddtnlTrctrAxlGrpWightAvailable 4063;
BA_ "SigType" SG_ 3221225472 TagAxleGroupWeightAvailable 4;
BA_ "SPN" SG_ 3221225472 TagAxleGroupWeightAvailable 4062;
BA_ "SigType" SG_ 3221225472 DriveAxleGroupWeightAvailable 4;
BA_ "SPN" SG_ 3221225472 DriveAxleGroupWeightAvailable 4061;
BA_ "SigType" SG_ 3221225472 LiftAxleGroupWeightAvailable 4;
BA_ "SPN" SG_ 3221225472 LiftAxleGroupWeightAvailable 4060;
BA_ "SigType" SG_ 3221225472 SteerAxleGroupWeightAvailable 4;
BA_ "SPN" SG_ 3221225472 SteerAxleGroupWeightAvailable 4059;
BA_ "SigType" SG_ 3221225472 ZeroNetVehicleWeightChange 4;
BA_ "SPN" SG_ 3221225472 ZeroNetVehicleWeightChange 4075;
BA_ "SPN" SG_ 3221225472 EngineExhaustGasTempAvrBank2 4152;
BA_ "SPN" SG_ 3221225472 EngExhaustGasTempAvrg 4151;
BA_ "SPN" SG_ 3221225472 NumberOfAETCDataPoints 3559;
BA_ "SPN" SG_ 3221225472 AETCDataCollectionStandard 3558;
BA_ "SPN" SG_ 3221225472 RightHeadlampLightDistribution 3694;
BA_ "SPN" SG_ 3221225472 LeftHeadlampLightDistribution 3693;
BA_ "SPN" SG_ 3221225472 RghtHeadlampDynamicBendingLight 3692;
BA_ "SPN" SG_ 3221225472 LeftHeadlampDynamicBendingLight 3691;
BA_ "SigType" SG_ 3221225472 AuxI_OChannel2 1;
BA_ "SPN" SG_ 3221225472 AuxI_OChannel2 1084;
BA_ "SigType" SG_ 3221225472 AuxI_OChannel1 1;
BA_ "SPN" SG_ 3221225472 AuxI_OChannel1 1083;
BA_ "SigType" SG_ 3221225472 AuxI_O45 4;
BA_ "SPN" SG_ 3221225472 AuxI_O45 3868;
BA_ "SigType" SG_ 3221225472 AuxI_O46 4;
BA_ "SPN" SG_ 3221225472 AuxI_O46 3869;
BA_ "SigType" SG_ 3221225472 AuxI_O47 4;
BA_ "SPN" SG_ 3221225472 AuxI_O47 3870;
BA_ "SigType" SG_ 3221225472 AuxI_O48 4;
BA_ "SPN" SG_ 3221225472 AuxI_O48 3871;
BA_ "SigType" SG_ 3221225472 AuxI_O41 4;
BA_ "SPN" SG_ 3221225472 AuxI_O41 3864;
BA_ "SigType" SG_ 3221225472 AuxI_O42 4;
BA_ "SPN" SG_ 3221225472 AuxI_O42 3865;
BA_ "SigType" SG_ 3221225472 AuxI_O43 4;
BA_ "SPN" SG_ 3221225472 AuxI_O43 3866;
BA_ "SigType" SG_ 3221225472 AuxI_O44 4;
BA_ "SPN" SG_ 3221225472 AuxI_O44 3867;
BA_ "SigType" SG_ 3221225472 AuxI_O37 4;
BA_ "SPN" SG_ 3221225472 AuxI_O37 3860;
BA_ "SigType" SG_ 3221225472 AuxI_O38 4;
BA_ "SPN" SG_ 3221225472 AuxI_O38 3861;
BA_ "SigType" SG_ 3221225472 AuxI_O39 4;
BA_ "SPN" SG_ 3221225472 AuxI_O39 3862;
BA_ "SigType" SG_ 3221225472 AuxI_O40 4;
BA_ "SPN" SG_ 3221225472 AuxI_O40 3863;
BA_ "SigType" SG_ 3221225472 AuxI_O33 4;
BA_ "SPN" SG_ 3221225472 AuxI_O33 3856;
BA_ "SigType" SG_ 3221225472 AuxI_O34 4;
BA_ "SPN" SG_ 3221225472 AuxI_O34 3857;
BA_ "SigType" SG_ 3221225472 AuxI_O35 4;
BA_ "SPN" SG_ 3221225472 AuxI_O35 3858;
BA_ "SigType" SG_ 3221225472 AuxI_O36 4;
BA_ "SPN" SG_ 3221225472 AuxI_O36 3859;
BA_ "SigType" SG_ 3221225472 AuxI_O29 4;
BA_ "SPN" SG_ 3221225472 AuxI_O29 3852;
BA_ "SigType" SG_ 3221225472 AuxI_O30 4;
BA_ "SPN" SG_ 3221225472 AuxI_O30 3853;
BA_ "SigType" SG_ 3221225472 AuxI_O31 4;
BA_ "SPN" SG_ 3221225472 AuxI_O31 3854;
BA_ "SigType" SG_ 3221225472 AuxI_O32 4;
BA_ "SPN" SG_ 3221225472 AuxI_O32 3855;
BA_ "SigType" SG_ 3221225472 AuxI_O25 4;
BA_ "SPN" SG_ 3221225472 AuxI_O25 3848;
BA_ "SigType" SG_ 3221225472 AuxI_O26 4;
BA_ "SPN" SG_ 3221225472 AuxI_O26 3849;
BA_ "SigType" SG_ 3221225472 AuxI_O27 4;
BA_ "SPN" SG_ 3221225472 AuxI_O27 3850;
BA_ "SigType" SG_ 3221225472 AuxI_O28 4;
BA_ "SPN" SG_ 3221225472 AuxI_O28 3851;
BA_ "SigType" SG_ 3221225472 AuxI_O21 4;
BA_ "SPN" SG_ 3221225472 AuxI_O21 3844;
BA_ "SigType" SG_ 3221225472 AuxI_O22 4;
BA_ "SPN" SG_ 3221225472 AuxI_O22 3845;
BA_ "SigType" SG_ 3221225472 AuxI_O23 4;
BA_ "SPN" SG_ 3221225472 AuxI_O23 3846;
BA_ "SigType" SG_ 3221225472 AuxI_O24 4;
BA_ "SPN" SG_ 3221225472 AuxI_O24 3847;
BA_ "SigType" SG_ 3221225472 AuxI_O17 4;
BA_ "SPN" SG_ 3221225472 AuxI_O17 3840;
BA_ "SigType" SG_ 3221225472 AuxI_O18 4;
BA_ "SPN" SG_ 3221225472 AuxI_O18 3841;
BA_ "SigType" SG_ 3221225472 AuxI_O19 4;
BA_ "SPN" SG_ 3221225472 AuxI_O19 3842;
BA_ "SigType" SG_ 3221225472 AuxI_O20 4;
BA_ "SPN" SG_ 3221225472 AuxI_O20 3843;
BA_ "SigType" SG_ 3221225472 AuxI_O77 4;
BA_ "SPN" SG_ 3221225472 AuxI_O77 3900;
BA_ "SigType" SG_ 3221225472 AuxI_O78 4;
BA_ "SPN" SG_ 3221225472 AuxI_O78 3901;
BA_ "SigType" SG_ 3221225472 AuxI_O79 4;
BA_ "SPN" SG_ 3221225472 AuxI_O79 3902;
BA_ "SigType" SG_ 3221225472 AuxI_O80 4;
BA_ "SPN" SG_ 3221225472 AuxI_O80 3903;
BA_ "SigType" SG_ 3221225472 AuxI_O73 4;
BA_ "SPN" SG_ 3221225472 AuxI_O73 3896;
BA_ "SigType" SG_ 3221225472 AuxI_O74 4;
BA_ "SPN" SG_ 3221225472 AuxI_O74 3897;
BA_ "SigType" SG_ 3221225472 AuxI_O75 4;
BA_ "SPN" SG_ 3221225472 AuxI_O75 3898;
BA_ "SigType" SG_ 3221225472 AuxI_O76 4;
BA_ "SPN" SG_ 3221225472 AuxI_O76 3899;
BA_ "SigType" SG_ 3221225472 AuxI_O69 4;
BA_ "SPN" SG_ 3221225472 AuxI_O69 3892;
BA_ "SigType" SG_ 3221225472 AuxI_O70 4;
BA_ "SPN" SG_ 3221225472 AuxI_O70 3893;
BA_ "SigType" SG_ 3221225472 AuxI_O71 4;
BA_ "SPN" SG_ 3221225472 AuxI_O71 3894;
BA_ "SigType" SG_ 3221225472 AuxI_O72 4;
BA_ "SPN" SG_ 3221225472 AuxI_O72 3895;
BA_ "SigType" SG_ 3221225472 AuxI_O65 4;
BA_ "SPN" SG_ 3221225472 AuxI_O65 3888;
BA_ "SigType" SG_ 3221225472 AuxI_O66 4;
BA_ "SPN" SG_ 3221225472 AuxI_O66 3889;
BA_ "SigType" SG_ 3221225472 AuxI_O67 4;
BA_ "SPN" SG_ 3221225472 AuxI_O67 3890;
BA_ "SigType" SG_ 3221225472 AuxI_O68 4;
BA_ "SPN" SG_ 3221225472 AuxI_O68 3891;
BA_ "SigType" SG_ 3221225472 AuxI_O61 4;
BA_ "SPN" SG_ 3221225472 AuxI_O61 3884;
BA_ "SigType" SG_ 3221225472 AuxI_O62 4;
BA_ "SPN" SG_ 3221225472 AuxI_O62 3885;
BA_ "SigType" SG_ 3221225472 AuxI_O63 4;
BA_ "SPN" SG_ 3221225472 AuxI_O63 3886;
BA_ "SigType" SG_ 3221225472 AuxI_O64 4;
BA_ "SPN" SG_ 3221225472 AuxI_O64 3887;
BA_ "SigType" SG_ 3221225472 AuxI_O57 4;
BA_ "SPN" SG_ 3221225472 AuxI_O57 3880;
BA_ "SigType" SG_ 3221225472 AuxI_O58 4;
BA_ "SPN" SG_ 3221225472 AuxI_O58 3881;
BA_ "SigType" SG_ 3221225472 AuxI_O59 4;
BA_ "SPN" SG_ 3221225472 AuxI_O59 3882;
BA_ "SigType" SG_ 3221225472 AuxI_O60 4;
BA_ "SPN" SG_ 3221225472 AuxI_O60 3883;
BA_ "SigType" SG_ 3221225472 AuxI_O53 4;
BA_ "SPN" SG_ 3221225472 AuxI_O53 3876;
BA_ "SigType" SG_ 3221225472 AuxI_O54 4;
BA_ "SPN" SG_ 3221225472 AuxI_O54 3877;
BA_ "SigType" SG_ 3221225472 AuxI_O55 4;
BA_ "SPN" SG_ 3221225472 AuxI_O55 3878;
BA_ "SigType" SG_ 3221225472 AuxI_O56 4;
BA_ "SPN" SG_ 3221225472 AuxI_O56 3879;
BA_ "SigType" SG_ 3221225472 AuxI_O49 4;
BA_ "SPN" SG_ 3221225472 AuxI_O49 3872;
BA_ "SigType" SG_ 3221225472 AuxI_O50 4;
BA_ "SPN" SG_ 3221225472 AuxI_O50 3873;
BA_ "SigType" SG_ 3221225472 AuxI_O51 4;
BA_ "SPN" SG_ 3221225472 AuxI_O51 3874;
BA_ "SigType" SG_ 3221225472 AuxI_O52 4;
BA_ "SPN" SG_ 3221225472 AuxI_O52 3875;
BA_ "SigType" SG_ 3221225472 AuxI_O92 4;
BA_ "SPN" SG_ 3221225472 AuxI_O92 3915;
BA_ "SigType" SG_ 3221225472 AuxI_O85 4;
BA_ "SPN" SG_ 3221225472 AuxI_O85 3908;
BA_ "SigType" SG_ 3221225472 AuxI_O86 4;
BA_ "SPN" SG_ 3221225472 AuxI_O86 3909;
BA_ "SigType" SG_ 3221225472 AuxI_O87 4;
BA_ "SPN" SG_ 3221225472 AuxI_O87 3910;
BA_ "SigType" SG_ 3221225472 AuxI_O88 4;
BA_ "SPN" SG_ 3221225472 AuxI_O88 3911;
BA_ "SigType" SG_ 3221225472 AuxI_O81 4;
BA_ "SPN" SG_ 3221225472 AuxI_O81 3904;
BA_ "SigType" SG_ 3221225472 AuxI_O82 4;
BA_ "SPN" SG_ 3221225472 AuxI_O82 3905;
BA_ "SigType" SG_ 3221225472 AuxI_O83 4;
BA_ "SPN" SG_ 3221225472 AuxI_O83 3906;
BA_ "SigType" SG_ 3221225472 AuxI_O84 4;
BA_ "SPN" SG_ 3221225472 AuxI_O84 3907;
BA_ "SigType" SG_ 3221225472 AuxI_O109 4;
BA_ "SPN" SG_ 3221225472 AuxI_O109 3932;
BA_ "SigType" SG_ 3221225472 AuxI_O110 4;
BA_ "SPN" SG_ 3221225472 AuxI_O110 3933;
BA_ "SigType" SG_ 3221225472 AuxI_O111 4;
BA_ "SPN" SG_ 3221225472 AuxI_O111 3934;
BA_ "SigType" SG_ 3221225472 AuxI_O112 4;
BA_ "SPN" SG_ 3221225472 AuxI_O112 3935;
BA_ "SigType" SG_ 3221225472 AuxI_O105 4;
BA_ "SPN" SG_ 3221225472 AuxI_O105 3928;
BA_ "SigType" SG_ 3221225472 AuxI_O106 4;
BA_ "SPN" SG_ 3221225472 AuxI_O106 3929;
BA_ "SigType" SG_ 3221225472 AuxI_O107 4;
BA_ "SPN" SG_ 3221225472 AuxI_O107 3930;
BA_ "SigType" SG_ 3221225472 AuxI_O108 4;
BA_ "SPN" SG_ 3221225472 AuxI_O108 3931;
BA_ "SigType" SG_ 3221225472 AuxI_O101 4;
BA_ "SPN" SG_ 3221225472 AuxI_O101 3924;
BA_ "SigType" SG_ 3221225472 AuxI_O102 4;
BA_ "SPN" SG_ 3221225472 AuxI_O102 3925;
BA_ "SigType" SG_ 3221225472 AuxI_O103 4;
BA_ "SPN" SG_ 3221225472 AuxI_O103 3926;
BA_ "SigType" SG_ 3221225472 AuxI_O104 4;
BA_ "SPN" SG_ 3221225472 AuxI_O104 3927;
BA_ "SigType" SG_ 3221225472 AuxI_O97 4;
BA_ "SPN" SG_ 3221225472 AuxI_O97 3920;
BA_ "SigType" SG_ 3221225472 AuxI_O98 4;
BA_ "SPN" SG_ 3221225472 AuxI_O98 3921;
BA_ "SigType" SG_ 3221225472 AuxI_O99 4;
BA_ "SPN" SG_ 3221225472 AuxI_O99 3922;
BA_ "SigType" SG_ 3221225472 AuxI_O100 4;
BA_ "SPN" SG_ 3221225472 AuxI_O100 3923;
BA_ "SigType" SG_ 3221225472 AuxI_O93 4;
BA_ "SPN" SG_ 3221225472 AuxI_O93 3916;
BA_ "SigType" SG_ 3221225472 AuxI_O94 4;
BA_ "SPN" SG_ 3221225472 AuxI_O94 3917;
BA_ "SigType" SG_ 3221225472 AuxI_O95 4;
BA_ "SPN" SG_ 3221225472 AuxI_O95 3918;
BA_ "SigType" SG_ 3221225472 AuxI_O96 4;
BA_ "SPN" SG_ 3221225472 AuxI_O96 3919;
BA_ "SigType" SG_ 3221225472 AuxI_O89 4;
BA_ "SPN" SG_ 3221225472 AuxI_O89 3912;
BA_ "SigType" SG_ 3221225472 AuxI_O90 4;
BA_ "SPN" SG_ 3221225472 AuxI_O90 3913;
BA_ "SigType" SG_ 3221225472 AuxI_O91 4;
BA_ "SPN" SG_ 3221225472 AuxI_O91 3914;
BA_ "SPN" SG_ 3221225472 TrailerBrakeStrokeAxle5Right 3804;
BA_ "SPN" SG_ 3221225472 TrailerBrakeStrokeAxle5Left 3803;
BA_ "SPN" SG_ 3221225472 TrailerBrakeStrokeAxle4Right 3802;
BA_ "SPN" SG_ 3221225472 TrailerBrakeStrokeAxle4Left 3801;
BA_ "SPN" SG_ 3221225472 TrailerBrakeStrokeAxle3Right 3800;
BA_ "SPN" SG_ 3221225472 TrailerBrakeStrokeAxle3Left 3799;
BA_ "SPN" SG_ 3221225472 TrailerBrakeStrokeAxle2Right 3798;
BA_ "SPN" SG_ 3221225472 TrailerBrakeStrokeAxle2Left 3797;
BA_ "SPN" SG_ 3221225472 TrailerBrakeStrokeAxle1Right 3796;
BA_ "SPN" SG_ 3221225472 TrailerBrakeStrokeAxle1Left 3795;
BA_ "SPN" SG_ 3221225472 TractorBrakeStrokeAxle5Right 3794;
BA_ "SPN" SG_ 3221225472 TractorBrakeStrokeAxle5Left 3793;
BA_ "SPN" SG_ 3221225472 TractorBrakeStrokeAxle4Right 3792;
BA_ "SPN" SG_ 3221225472 TractorBrakeStrokeAxle4Left 3791;
BA_ "SPN" SG_ 3221225472 TractorBrakeStrokeAxle3Right 3790;
BA_ "SPN" SG_ 3221225472 TractorBrakeStrokeAxle3Left 3789;
BA_ "SPN" SG_ 3221225472 TractorBrakeStrokeAxle2Right 3788;
BA_ "SPN" SG_ 3221225472 TractorBrakeStrokeAxle2Left 3787;
BA_ "SPN" SG_ 3221225472 TractorBrakeStrokeAxle1Right 3786;
BA_ "SPN" SG_ 3221225472 TractorBrakeStrokeAxle1Left 3785;
BA_ "SigType" SG_ 3221225472 RoadSurfaceTemp 1;
BA_ "SPN" SG_ 3221225472 RoadSurfaceTemp 79;
BA_ "SigType" SG_ 3221225472 EngAirInletTemp 1;
BA_ "SPN" SG_ 3221225472 EngAirInletTemp 172;
BA_ "SigType" SG_ 3221225472 AmbientAirTemp 1;
BA_ "SPN" SG_ 3221225472 AmbientAirTemp 171;
BA_ "SigType" SG_ 3221225472 CabInteriorTemp 1;
BA_ "SPN" SG_ 3221225472 CabInteriorTemp 170;
BA_ "SigType" SG_ 3221225472 BarometricPress 1;
BA_ "SPN" SG_ 3221225472 BarometricPress 108;
BA_ "SigType" SG_ 3221225472 EngAirStartPress 1;
BA_ "SPN" SG_ 3221225472 EngAirStartPress 82;
BA_ "SigType" SG_ 3221225472 AirCompressorStatus 4;
BA_ "SPN" SG_ 3221225472 AirCompressorStatus 1351;
BA_ "SigType" SG_ 3221225472 AirSuspensionSupplyPress 1;
BA_ "SPN" SG_ 3221225472 AirSuspensionSupplyPress 1090;
BA_ "SigType" SG_ 3221225472 AuxEquipmentSupplyPress 1;
BA_ "SPN" SG_ 3221225472 AuxEquipmentSupplyPress 1089;
BA_ "SigType" SG_ 3221225472 ServiceBrakeAirPressCircuit2 1;
BA_ "SPN" SG_ 3221225472 ServiceBrakeAirPressCircuit2 1088;
BA_ "SigType" SG_ 3221225472 ServiceBrakeAirPressCircuit1 1;
BA_ "SPN" SG_ 3221225472 ServiceBrakeAirPressCircuit1 1087;
BA_ "SigType" SG_ 3221225472 ParkingAnd_OrTrailerAirPress 1;
BA_ "SPN" SG_ 3221225472 ParkingAnd_OrTrailerAirPress 1086;
BA_ "SigType" SG_ 3221225472 PneumaticSupplyPress 1;
BA_ "SPN" SG_ 3221225472 PneumaticSupplyPress 46;
BA_ "SigType" SG_ 3221225472 SteerAxleLubePress 1;
BA_ "SPN" SG_ 3221225472 SteerAxleLubePress 2614;
BA_ "SigType" SG_ 3221225472 SteerAxleTemp 1;
BA_ "SPN" SG_ 3221225472 SteerAxleTemp 75;
BA_ "SigType" SG_ 3221225472 DriveAxleLubePress 1;
BA_ "SPN" SG_ 3221225472 DriveAxleLubePress 2613;
BA_ "SigType" SG_ 3221225472 DriveAxleTemp 1;
BA_ "SPN" SG_ 3221225472 DriveAxleTemp 578;
BA_ "SigType" SG_ 3221225472 DriveAxleLiftAirPress 1;
BA_ "SPN" SG_ 3221225472 DriveAxleLiftAirPress 579;
BA_ "SigType" SG_ 3221225472 DriveAxleLocation 1;
BA_ "SPN" SG_ 3221225472 DriveAxleLocation 930;
BA_ "SigType" SG_ 3221225472 EngTurboWastegateValvePos 1;
BA_ "SPN" SG_ 3221225472 EngTurboWastegateValvePos 1693;
BA_ "SigType" SG_ 3221225472 EngGsMssFlwSnsrFelingCorrection 1;
BA_ "SPN" SG_ 3221225472 EngGsMssFlwSnsrFelingCorrection 1694;
BA_ "SigType" SG_ 3221225472 EngDsiredAbsIntakeManifoldPress 1;
BA_ "SPN" SG_ 3221225472 EngDsiredAbsIntakeManifoldPress 1692;
BA_ "SigType" SG_ 3221225472 EngGasFuelCorrectionFactor 1;
BA_ "SPN" SG_ 3221225472 EngGasFuelCorrectionFactor 1116;
BA_ "SPN" SG_ 3221225472 RqedACCDistanceMode 1799;
BA_ "SigType" SG_ 3221225472 ACCDistanceAlertSignal 4;
BA_ "SPN" SG_ 3221225472 ACCDistanceAlertSignal 1796;
BA_ "SigType" SG_ 3221225472 ACCSystemShutoffWarning 4;
BA_ "SPN" SG_ 3221225472 ACCSystemShutoffWarning 1797;
BA_ "SigType" SG_ 3221225472 ACCTargetDetected 4;
BA_ "SPN" SG_ 3221225472 ACCTargetDetected 1798;
BA_ "SPN" SG_ 3221225472 AdptveCruiseCtrlSetDistanceMode 1589;
BA_ "SPN" SG_ 3221225472 AdaptiveCruiseCtrlMode 1590;
BA_ "SigType" SG_ 3221225472 AdaptiveCruiseCtrlSetSpeed 1;
BA_ "SPN" SG_ 3221225472 AdaptiveCruiseCtrlSetSpeed 1588;
BA_ "SigType" SG_ 3221225472 DistanceToForwardVehicle 1;
BA_ "SPN" SG_ 3221225472 DistanceToForwardVehicle 1587;
BA_ "SigType" SG_ 3221225472 SpeedOfForwardVehicle 1;
BA_ "SPN" SG_ 3221225472 SpeedOfForwardVehicle 1586;
BA_ "SigType" SG_ 3221225472 ArticulationAngle 1;
BA_ "SPN" SG_ 3221225472 ArticulationAngle 1120;
BA_ "SigType" SG_ 3221225472 RelativeHumidity 1;
BA_ "SigType" SG_ 3221225472 AuxLevel 1;
BA_ "SPN" SG_ 3221225472 AuxLevel 3087;
BA_ "SigType" SG_ 3221225472 AuxPress2 1;
BA_ "SPN" SG_ 3221225472 AuxPress2 1388;
BA_ "SigType" SG_ 3221225472 AuxPress1 1;
BA_ "SPN" SG_ 3221225472 AuxPress1 1387;
BA_ "SigType" SG_ 3221225472 AuxTemp2 1;
BA_ "SPN" SG_ 3221225472 AuxTemp2 442;
BA_ "SigType" SG_ 3221225472 AuxTemp1 1;
BA_ "SPN" SG_ 3221225472 AuxTemp1 441;
BA_ "SigType" SG_ 3221225472 EngBlowerBypassValvePos 1;
BA_ "SPN" SG_ 3221225472 EngBlowerBypassValvePos 72;
BA_ "SigType" SG_ 3221225472 EngGasSupplyPress 1;
BA_ "SPN" SG_ 3221225472 EngGasSupplyPress 159;
BA_ "SigType" SG_ 3221225472 Status2OfDoors 4;
BA_ "SPN" SG_ 3221225472 Status2OfDoors 3411;
BA_ "SigType" SG_ 3221225472 Ramp_WheelChairLiftPos 4;
BA_ "SPN" SG_ 3221225472 Ramp_WheelChairLiftPos 1820;
BA_ "SPN" SG_ 3221225472 PosOfDoors 1821;
BA_ "SigType" SG_ 3221225472 FifthWheelRollWarningIndicator 4;
BA_ "SPN" SG_ 3221225472 FifthWheelRollWarningIndicator 3317;
BA_ "SigType" SG_ 3221225472 FifthWheelRollMoment 1;
BA_ "SPN" SG_ 3221225472 FifthWheelRollMoment 3310;
BA_ "SigType" SG_ 3221225472 FifthWheelDrawbarForce 1;
BA_ "SPN" SG_ 3221225472 FifthWheelDrawbarForce 3309;
BA_ "SigType" SG_ 3221225472 FifthWheelVerticalForce 1;
BA_ "SPN" SG_ 3221225472 FifthWheelVerticalForce 3308;
BA_ "SigType" SG_ 3221225472 FifthWheelSliderLockIndicator 4;
BA_ "SPN" SG_ 3221225472 FifthWheelSliderLockIndicator 3316;
BA_ "SigType" SG_ 3221225472 FifthWheelSliderPos 1;
BA_ "SPN" SG_ 3221225472 FifthWheelSliderPos 3311;
BA_ "SigType" SG_ 3221225472 FfthWhlLckCoupleStatusIndicator 4;
BA_ "SPN" SG_ 3221225472 FfthWhlLckCoupleStatusIndicator 3313;
BA_ "SigType" SG_ 3221225472 FfthWhlLckRadyToCoupleIndicator 4;
BA_ "SPN" SG_ 3221225472 FfthWhlLckRadyToCoupleIndicator 3312;
BA_ "SPN" SG_ 3221225472 FifthWheelErrorStatus 3307;
BA_ "SigType" SG_ 3221225472 RollAndPitchMeasurementLatency 1;
BA_ "SPN" SG_ 3221225472 RollAndPitchMeasurementLatency 3327;
BA_ "SigType" SG_ 3221225472 PitchAndRollCompensated 4;
BA_ "SPN" SG_ 3221225472 PitchAndRollCompensated 3326;
BA_ "SigType" SG_ 3221225472 PitchRateFigureOfMerit 4;
BA_ "SPN" SG_ 3221225472 PitchRateFigureOfMerit 3325;
BA_ "SigType" SG_ 3221225472 RollAngleFigureOfMerit 4;
BA_ "SPN" SG_ 3221225472 RollAngleFigureOfMerit 3324;
BA_ "SigType" SG_ 3221225472 PitchAngleFigureOfMerit 4;
BA_ "SPN" SG_ 3221225472 PitchAngleFigureOfMerit 3323;
BA_ "SigType" SG_ 3221225472 PitchRate 1;
BA_ "SPN" SG_ 3221225472 PitchRate 3322;
BA_ "SigType" SG_ 3221225472 RollAngle 1;
BA_ "SPN" SG_ 3221225472 RollAngle 3319;
BA_ "SigType" SG_ 3221225472 PitchAngle 1;
BA_ "SPN" SG_ 3221225472 PitchAngle 3318;
BA_ "SPN" SG_ 3221225472 TransOilLevelMeasurementStatus 3026;
BA_ "SPN" SG_ 3221225472 TransOilLevelCountdownTimer 3028;
BA_ "SigType" SG_ 3221225472 TransOilLevelHigh_Low 1;
BA_ "SPN" SG_ 3221225472 TransOilLevelHigh_Low 3027;
BA_ "SigType" SG_ 3221225472 TransOilTemp 1;
BA_ "SPN" SG_ 3221225472 TransOilTemp 177;
BA_ "SigType" SG_ 3221225472 TransOilPress 1;
BA_ "SPN" SG_ 3221225472 TransOilPress 127;
BA_ "SigType" SG_ 3221225472 TransFilterDiffPress 1;
BA_ "SPN" SG_ 3221225472 TransFilterDiffPress 126;
BA_ "SigType" SG_ 3221225472 TransOilLevel 1;
BA_ "SPN" SG_ 3221225472 TransOilLevel 124;
BA_ "SigType" SG_ 3221225472 ClutchPress 1;
BA_ "SPN" SG_ 3221225472 ClutchPress 123;
BA_ "SigType" SG_ 3221225472 BatteryPotentialSwitched 1;
BA_ "SPN" SG_ 3221225472 BatteryPotentialSwitched 158;
BA_ "SigType" SG_ 3221225472 ElectricalPotential 1;
BA_ "SPN" SG_ 3221225472 ElectricalPotential 168;
BA_ "SigType" SG_ 3221225472 ChargingSystemPotential 1;
BA_ "SPN" SG_ 3221225472 ChargingSystemPotential 167;
BA_ "SigType" SG_ 3221225472 AltCurrent 1;
BA_ "SPN" SG_ 3221225472 AltCurrent 115;
BA_ "SigType" SG_ 3221225472 NetBatteryCurrent 1;
BA_ "SPN" SG_ 3221225472 NetBatteryCurrent 114;
BA_ "SigType" SG_ 3221225472 WrlessCommunicationNetworkType2 1;
BA_ "SPN" SG_ 3221225472 WrlessCommunicationNetworkType2 3446;
BA_ "SigType" SG_ 3221225472 NetworkSignalStrength2 1;
BA_ "SPN" SG_ 3221225472 NetworkSignalStrength2 3445;
BA_ "SigType" SG_ 3221225472 NetworkAntennaStatus2 1;
BA_ "SPN" SG_ 3221225472 NetworkAntennaStatus2 3444;
BA_ "SigType" SG_ 3221225472 NetworkServiceStatus2 1;
BA_ "SPN" SG_ 3221225472 NetworkServiceStatus2 3443;
BA_ "SigType" SG_ 3221225472 NetworkTransceiverStatus2 1;
BA_ "SPN" SG_ 3221225472 NetworkTransceiverStatus2 3442;
BA_ "SigType" SG_ 3221225472 WrlessCommunicationNetworkType1 1;
BA_ "SPN" SG_ 3221225472 WrlessCommunicationNetworkType1 3372;
BA_ "SigType" SG_ 3221225472 NetworkSignalStrength1 1;
BA_ "SPN" SG_ 3221225472 NetworkSignalStrength1 3371;
BA_ "SigType" SG_ 3221225472 NetworkAntennaStatus1 1;
BA_ "SPN" SG_ 3221225472 NetworkAntennaStatus1 3370;
BA_ "SigType" SG_ 3221225472 NetworkServiceStatus1 1;
BA_ "SPN" SG_ 3221225472 NetworkServiceStatus1 3369;
BA_ "SigType" SG_ 3221225472 NetworkTransceiverStatus1 1;
BA_ "SPN" SG_ 3221225472 NetworkTransceiverStatus1 3368;
BA_ "SigType" SG_ 3221225472 VoltageRegulatorEnabled 4;
BA_ "SPN" SG_ 3221225472 VoltageRegulatorEnabled 3379;
BA_ "SigType" SG_ 3221225472 VoltageRegulatorSoftStartState 4;
BA_ "SPN" SG_ 3221225472 VoltageRegulatorSoftStartState 3378;
BA_ "SigType" SG_ 3221225472 VltgRgltrUndrfrqncyCmpnstnEnbld 4;
BA_ "SPN" SG_ 3221225472 VltgRgltrUndrfrqncyCmpnstnEnbld 3377;
BA_ "SPN" SG_ 3221225472 VltgRgltrVAr_PwrFctrOprtingMode 3376;
BA_ "SPN" SG_ 3221225472 VltgRglatorLoadCompensationMode 3375;
BA_ "SigType" SG_ 3221225472 GnrtrOtputVoltageBiasPercentage 1;
BA_ "SPN" SG_ 3221225472 GnrtrOtputVoltageBiasPercentage 3382;
BA_ "SigType" SG_ 3221225472 GeneratorExcitationFieldCurrent 1;
BA_ "SPN" SG_ 3221225472 GeneratorExcitationFieldCurrent 3381;
BA_ "SigType" SG_ 3221225472 GeneratorExcitationFieldVoltage 1;
BA_ "SPN" SG_ 3221225472 GeneratorExcitationFieldVoltage 3380;
BA_ "SPN" SG_ 2566763776 SpnConversionMethod1 1706;
BA_ "SPN" SG_ 2566763776 SpnConversionMethod5 1706;
BA_ "SPN" SG_ 2566763776 SpnConversionMethod4 1706;
BA_ "SPN" SG_ 2566763776 SpnConversionMethod3 1706;
BA_ "SPN" SG_ 2566763776 SpnConversionMethod2 1706;
BA_ "SPN" SG_ 2566763776 OccurenceCount5 1216;
BA_ "SPN" SG_ 2566763776 OccurenceCount4 1216;
BA_ "SPN" SG_ 2566763776 OccurenceCount3 1216;
BA_ "SPN" SG_ 2566763776 OccurenceCount2 1216;
BA_ "SPN" SG_ 2566763776 OccurenceCount1 1216;
BA_ "SPN" SG_ 2566763776 FMI5 4149;
BA_ "SPN" SG_ 2566763776 FMI4 4149;
BA_ "SPN" SG_ 2566763776 FMI3 4149;
BA_ "SPN" SG_ 2566763776 FMI2 4149;
BA_ "SPN" SG_ 2566763776 FMI1 4149;
BA_ "SigType" SG_ 2566763776 FlashRedStopLamp 5;
BA_ "SPN" SG_ 2566763776 FlashRedStopLamp 3039;
BA_ "SigType" SG_ 2566763776 FlashProtectLamp 5;
BA_ "SPN" SG_ 2566763776 FlashProtectLamp 3041;
BA_ "SigType" SG_ 2566763776 FlashMalfuncIndicatorLamp 5;
BA_ "SPN" SG_ 2566763776 FlashMalfuncIndicatorLamp 3038;
BA_ "SigType" SG_ 2566763776 FlashAmberWarningLamp 5;
BA_ "SPN" SG_ 2566763776 FlashAmberWarningLamp 3040;
BA_ "SigType" SG_ 2566763776 MalfunctionIndLampStatus 5;
BA_ "SPN" SG_ 2566763776 MalfunctionIndLampStatus 1213;
BA_ "SigType" SG_ 2566763776 AmberWarningLampStatus 5;
BA_ "SPN" SG_ 2566763776 AmberWarningLampStatus 624;
BA_ "SigType" SG_ 2566763776 RedStopLampState 4;
BA_ "SPN" SG_ 2566763776 RedStopLampState 623;
BA_ "SigType" SG_ 2566763776 ProtectLampStatus 5;
BA_ "SPN" SG_ 2566763776 ProtectLampStatus 987;
BA_ "SigType" SG_ 2566763776 SPN5 13;
BA_ "SigType" SG_ 2566763776 SPN4 13;
BA_ "SigType" SG_ 2566763776 SPN3 13;
BA_ "SigType" SG_ 2566763776 SPN2 13;
BA_ "SigType" SG_ 2566763776 SPN1 13;
BA_ "SigType" SG_ 2365213438 ControllerIdBodyLength 1;
BA_ "SPN" SG_ 2365213438 ControllerIdBodyLength 21109;
BA_ "SPN" SG_ 2365213438 ControllerIdType 21108;
BA_ "SigType" SG_ 2365213438 RecordLength 1;
BA_ "SPN" SG_ 2365213438 RecordLength 21106;
BA_ "SigType" SG_ 2365213438 DtcType 1;
BA_ "SPN" SG_ 2365213438 DtcType 21107;
BA_ "SPN" SG_ 2365213438 OccurenceCount 1216;
BA_ "SPN" SG_ 2365213438 SpnConversionMethod 1706;
BA_ "SPN" SG_ 2365213438 FMI 1215;
BA_ "SigType" SG_ 2365213438 SPN 13;
BA_ "SPN" SG_ 2365213438 SPN 1214;
BA_ "SPN" SG_ 2365271294 TimeElapsedSinceDTCsErased 12320;
BA_ "SigType" SG_ 2365271294 ContinuousMiTimeWhileEngOp 1;
BA_ "SPN" SG_ 2365271294 ContinuousMiTimeWhileEngOp 12319;
BA_ "SigType" SG_ 2365316094 RationalityFaultSPN 13;
BA_ "SPN" SG_ 2365316094 RationalityFaultSPN 8555;
BA_ "SPN" SG_ 2365316094 TestIdentifier 1224;
BA_ "SigType" SG_ 2566702846 EngOBDWarmUpSequence 5;
BA_ "SPN" SG_ 2566702846 EngOBDWarmUpSequence 5843;
BA_ "SPN" SG_ 2566703102 CertificationEngineFamilyName 5845;
BA_ "SigType" SG_ 2566703102 ModelYear 3;
BA_ "SPN" SG_ 2566703102 ModelYear 5844;
VAL_ 3221225472 RedStopLampState 3 "Not available" 2 "Reserved" 1 "Lamp on" 0 "Lamp off" ;
VAL_ 3221225472 AmberWarningLampStatus 3 "Not available" 2 "Reserved" 1 "Lamp on" 0 "Lamp off" ;
VAL_ 3221225472 ProtectLampStatus 3 "Not available" 2 "Reserved" 1 "Lamp on" 0 "Lamp off" ;
VAL_ 3221225472 IndustryGroup 6 "Reserved for SAE" 7 "Reserved for SAE" 5 "IndustrialProcessCtrlStationary" 4 "Marine" 3 "Construction" 2 "Agricultural and Forestry" 1 "On-Highway" 0 "Global" ;
VAL_ 3221225472 Function 127 "Reserved" 126 "Reserved" 125 "Reserved" 124 "Reserved" 123 "Reserved" 122 "Reserved" 121 "Reserved" 120 "Reserved" 119 "Reserved" 118 "Reserved" 117 "Reserved" 116 "Reserved" 115 "Reserved" 114 "Reserved" 113 "Reserved" 112 "Reserved" 111 "Reserved" 110 "Reserved" 109 "Reserved" 108 "Reserved" 107 "Reserved" 106 "Reserved" 105 "Reserved" 104 "Reserved" 103 "Reserved" 102 "Reserved" 101 "Reserved" 42 "Water Pump Control" 41 "Lighting - Operator Controls" 40 "Seat Control" 39 "Ignition Control Module" 38 "Tire Pressure Control" 37 "Cab Controller" 36 "Pneumatic - System Controller" 35 "Suspension - System Controller" 34 "Hydraulic Pump Controller" 33 "System Monitor" 32 "Headway Controller" 31 "Propulsion Battery Charger" 30 "Management Computer" 29 "Virtual Terminal (In Cab)" 28 "Off Vehicle Gateway" 27 "Power TakeOff (Secondary or Front)" 26 "Body Controller" 25 "Network Interconnect ECU" 24 "Vehicle Security" 23 "Vehicle Navigation" 22 "Aerodynamic Control" 21 "Cab Climate Control" 20 "Trip Recorder" 19 "Instrument Cluster" 18 "Suspension - Drive Axle" 17 "Suspension - Steer Axle" 16 "Steeting Controller" 15 "Fuel System" 14 "Cruise Control" 13 "Retarder - Driveline" 12 "Retarder - Engine" 11 "Brakes - Drive Axle" 10 "Brakes - Steer Axle" 9 "Brakes - System Controller" 8 "Axle - Drive" 7 "Axle - Steering" 6 "Power TakeOff - (Main or Rear)" 5 "Shift Control/Console" 4 "Battery Pack Monitor" 3 "Transmission" 2 "Electric Propulsion Control" 1 "Auxiliary Power Unit (APU)" 0 "Engine" 100 "Reserved" 99 "Reserved" 98 "Reserved" 97 "Reserved" 96 "Reserved" 95 "Reserved" 94 "Reserved" 93 "Reserved" 92 "Reserved" 91 "Reserved" 90 "Reserved" 89 "Reserved" 88 "Reserved" 87 "Reserved" 86 "Reserved" 85 "Reserved" 84 "Reserved" 83 "Reserved" 82 "Reserved" 81 "Reserved" 80 "Reserved" 79 "Reserved" 78 "Reserved" 77 "Reserved" 76 "Reserved" 75 "Reserved" 74 "Reserved" 73 "Reserved" 72 "Coolant Valve Controller" 71 "Transfer Case Control" 70 "Auxiliary Regeneration Device" 69 "Engine Emission Aftertreatement System" 68 "Aftertreatment system gas measurement" 67 "Electrical System Controller" 66 "I/O Controller" 65 "Gas Flow Measurement" 64 "Endurance Braking" 63 "Engine Valve Controller" 62 "On-Board Diagnostic Unit" 61 "File Server/Printer" 60 "Cab Display" 59 "Starter" 58 "Fan Drive Control" 57 "Steering Column Unit" 56 "Communications Unit, Radio" 55 "Communications Unit, Satellite" 54 "Communications Unit, Cellular" 53 "Alternator/Charging System" 52 "Chassis Controller" 51 "Forward-Looking Collision Warning System" 50 "Auxiliary Heater" 49 "Clutch/Converter Control" 48 "Ramp Control" 47 "Information System Controller" 46 "Oil Sensor Unit" 45 "Vehicle Dynamic Stability Control" 44 "Exhaust Emission Control" 43 "Transmission Display" ;
VAL_ 3221225472 VehicleSystem 0 "Non-specific System" 127 "Not Available" ;
VAL_ 3221225472 ManufacturerCode 252 "Sensor-Technik Wiedemann GmbH" 251 "German Agricultural Society" 250 "Kuhn Group" 249 "Schaltbau GmbH" 233 "Yacht Monitoring Solutions Inc." 232 "TSD Integrated Controls" 1863 "Thomas G. Faria Co." 1862 "Sanshin" 1861 "Vector CANtech" 1860 "MMP" 1859 "Kvasar AB" 1858 "Litton" 1857 "Simrad" 1856 "Trimble" 1855 "Furuno USA" 1854 "Northstar Technologies" 1853 "Japan Radio Co." 1852 "Navionics" 1851 "Raymarine" 1850 "Teleflex" 222 "Generac Power Systems, Inc." 221 "SiE" 220 "Beede Electrical Instrument Company, Inc." 219 "Cat OEM Solutions" 218 "Gits Manufacturing Company" 217 "RM Michaelides Software & Elektronik GmbH" 216 "Paneltronics Inc." 215 "Aetna Engineering/Fireboy-Xintex" 214 "MC elettronica Srl" 213 "CNH Belgium N.V." 212 "Sure Power Industries, Inc." 211 "DNA Group" 210 "Iteris, Inc." 209 "Bell Equip. Co. SA (PTY) LTD" 208 "Drew Technologies, Inc." 207 "Otto Engineering" 206 "port GmbH" 205 "SmarTire Systems Inc" 204 "The Morey Corporation" 203 "MILtronik GmbH" 202 "Curtis Instruments, Inc." 201 "Disenos y Tecnologia S.A." 200 "MGM Brakes" 199 "Actia Corp." 198 "Mystic Valley Communications" 197 "Mechron Power Systems" 196 "LEMKEN GmbH & Co. KG" 195 "General Engine Products" 194 "TriMark Corporation" 193 "Jeppesen Marine" 192 "Floscan" 191 "XATA Corporation" 190 "Hella KGaA Hueck & Co." 189 "QUALCOMM" 188 "EMP Corp." 187 "Air-Weigh" 186 "Altronic, Inc." 185 "Beede Electrical Instrument Company" 184 "EIA Electronics" 183 "KDS Controls, Inc." 182 "Vehicle Systems Engineering B.V." 181 "Coretronics, Inc." 180 "Smart Power Systems" 179 "Midwest Technologies Illinois, LLC" 178 "Siemens VDO Automotive AG" 177 "Diagnostic System Associates" 176 "Moritz Aerospace" 175 "Veris Technologies, Inc." 174 "AB Volvo Penta" 173 "Ryeso, Inc." 172 "Yanmar Marine USA" 171 "Wachendorff Elektronik GmbH & Co. KG" 170 "Computronics Corporation Ltd." 169 "Marlin Technologies Inc." 168 "Xantrex" 167 "JLG Industries Inc." 166 "Phoenix International" 165 "CPAC Systems AB" 164 "DaimlerChrysler Off-Highway" 163 "BRP Inc." 162 "Axiomatic Technologies" 161 "Offshore Systems (UK) Limited" 160 "Nido" 159 "NTech Industries Inc." 158 "Firestone Industrial Products Company" 157 "ISSPRO Inc." 156 "ITT Industries - Cannon" 155 "Vetronix Corporation" 154 "Westerbeke Corporation" 153 "Woodward, Industrial Controls Division" 152 "Elobau Elektrobauelemente GmbH & Co. KG" 151 "Raven Industries Inc. - Flow Controls Division" 150 "Fleetguard" 149 "Holset" 148 "Blue Water Data, Inc." 147 "Nautibus Electronic GmbH" 146 "Maxima Technologies" 145 "MurCal Controls" 144 "Mercury Marine" 143 "W. Gmeiner GmbH & Co." 142 "TRW Automotive (Commercial Steering Systems)" 141 "Thales Navigation Ltd." 140 "Lowrance Electronics, Inc." 139 "Caterpillar Trimble Control Technologies (CTCT), LLC" 138 "Georg Fritzmeier GmbH & Co. KG" 137 "Maretron" 136 "Komatsu Ltd." 135 "Airmar Technology Corporation" 134 "Iris Technology Ltd." 133 "Bucher Schoerling GmbH" 132 "Mulag-Fahrzeugwerk" 131 "ITT Industries" 130 "Nido - Universal Machines B.V." 129 "OMNEX Control Systems, Inc." 128 "Gerhard Duecker GmbH & Co. KG" 127 "Holland USA" 126 "Driver Tech" 125 "Nevada Automotive Test Center" 124 "Hydac Electronic" 123 "Basler Electric" 122 "FG Wilson (Engineering) Limited" 121 "HED (Hydro Electronic Devices, Inc.)" 120 "RDS Technology Ltd." 119 "IntegriNautics" 118 "Intron GmbH" 117 "HUSCO International" 116 "BEELINE Technologies" 115 "NACCO Materials Handling Group, Inc." 114 "EControls, Inc." 113 "Stress-Tek, Inc." 112 "MECALAC" 111 "Maschinenfabrik Bernhard Krone GmbH" 110 "EPIQ Sensor-Nite" 109 "LH Technologies ApS" 108 "WTK-Elecktronik GmbH" 107 "Grimme Landmaschinen GmbH & Co. KG" 106 "BAE Systems Controls, Inc." 105 "Kiepe Elektrik GmbH & Co. KG" 104 "Claas Selbstfahrende Erntemaschinen GmbH" 103 "Agrocom GmbH & Co. Agrarsystem KG" 102 "AGCO GmbH & Co." 101 "Sensoria" 100 "VDO Technik AG" 99 "International Transmissions Ltd (ITL)" 98 "Mueller-Elektronik GmbH & Co." 97 "Ag Leader Technology, Inc." 96 "Mech@tronic IT GmbH" 95 "Pacific Insight Electronics Corp." 94 "CNH Global N.V." 93 "Perkins Engines Company Ltd." 92 "Ag-Chem Equipment Co., Inc." 91 "BSG Bodensee Steuergeraete GmbH" 90 "Knorr-Bremse SfN GmbH" 89 "Kverneland Group, Electronics Division" 88 "Satloc Precision GPS" 87 "J.C. Bamford Excavators Ltd (JCB)" 86 "C.E. Niehoff & Company" 85 "Kohler Co." 84 "New Holland UK Limited" 83 "Eaton VORAD Technologies" 82 "Bobcat/Ingersoll-Rand" 81 "Fire Research Corp" 80 "Twin Disc, Inc." 79 "Daimler Benz AG - Engine Division (PBM)" 78 "Frank W. Murphy Manufacturing, Inc." 77 "Deere Power Systems Group" 76 "unused" 75 "Deere & Co. Agricultural Division" 74 "Eaton Axle-Brake Division" 73 "LeTourneau, Inc." 72 "Sisu Corporation" 71 "Vansco Electronics Ltd." 70 "Flex-Coil Limited" 69 "Trimble Navigation" 68 "Scania" 67 "Funk Manufacturing Company" 66 "John Deere Construction Equipment Division" 65 "MAN Nutzfahrzeuge AG" 64 "unused" 63 "ZF Industries Inc." 62 "Wabco" 61 "Volvo Truck Corp." 60 "Volvo Trucks North America Inc." 59 "VES Inc." 58 "SPX Corporation, OTC Division" 57 "Sauer-Danfoss Co." 56 "SAIC" 55 "Ryder System Inc." 54 "Meritor Wabco" 53 "Rockwell Land Transportation" 52 "Meritor Automotive, Inc." 51 "Robert Bosch GmbH" 50 "Robert Bosch Corp" 49 "RE America Inc." 48 "Pollak Alphabet" 47 "Phillips Semiconductor" 46 "Parasoft Computing Solutions" 45 "PACCAR" 44 "Nippondenso Co. Ltd." 43 "International Truck and Engine Corp. Vehicle Electronics" 42 "International Truck and Engine Corp. Engine Electronics" 41 "Motorola Inc." 40 "Motorola AIEG Inc." 39 "Microfirm Inc." 38 "Micro Processor Systems Inc." 37 "Mack Trucks Inc." 36 "Lucas Ltd." 35 "Kenworth Truck Co." 34 "Kelsey Hayes Co." 33 "John Deere" 32 "Jacobs Vehicle Systems" 31 "J Pollak Corp." 30 "Isuzu Motors Ltd." 29 "Hino Motors Ltd." 28 "Grote Ind. Inc." 27 "GMC" 26 "General Motors Corp., Service Technology Group" 25 "Freightliner LLC" 24 "Ford Motor Co., Vehicle Controls" 23 "Ford Motor Co., Heavy Truck" 22 "Ford Motor Co., Electronic Concepts $ Systems" 21 "Echilin Inc., Midland Brake Inc." 20 "Eaton Ltd" 19 "Eaton Corp. Trucking Info Services" 18 "Eaton Corp, Transmission Division" 17 "Eaton Corp. Res & Dev" 16 "Eaton Corp." 15 "Dickey-John Corp." 14 "Detroit Diesel Corporation" 13 "Delco Electronics" 12 "Deere & Company, Precision Farming" 11 "Dearborn Group Inc." 10 "Cummins Engine Co." 9 "Chrysler Corp." 8 "Caterpillar Inc." 7 "Case Corp." 6 "Berifors Electronics AB" 5 "AMP Inc." 4 "Ametek-Dixson" 3 "Ametek, US Gauge Division" 2 "Allison Transmission, GMC" 1 "Allied Signal Inc." 0 "Reserved" 231 "Topcon Positioning Systems, Inc." 230 "Saucon Technologies" 229 "Garmin International Inc." 228 "ZF Marine Electronics" 227 "Lykketronic A/S" 226 "Monaco Coach Corporation" 225 "SKF" 224 "EMMI Network, S.L." 223 "Vaueo Retarder Co., Ltd." 263 "IMMI" 262 "HydraForce, Inc" 261 "Red Dot Corporation" 260 "Reichhardt GmbH" 259 "Jetter AG" 258 "ARAG" 257 "Honda Motor Co., Ltd" 256 "Tyco Electronics AMP" 255 "MEAS France" 254 "GE Sensing" 253 "Mobile Control Systems" ;
VAL_ 3221225472 VehicleSystem5 127 "Not Available" 0 "Ind. Process Control Stationary" ;
VAL_ 3221225472 VehicleSystem4 100 "Deck/Cargo/Fishing equip. sys" 90 "Environmental (HVAC) Systems" 80 "Instrumentation/General Systems" 70 "Communications Systems" 60 "Navigation Systems" 50 "Propulsion Systems" 40 "Steering Systems" 30 "Power Mgmt and lighting systems" 25 "Gateway" 20 "Safety Systems" 10 "System Tools" 127 "Not Available" 0 "Non-specific System" ;
VAL_ 3221225472 VehicleSystem3 8 "Grader" 7 "Four Wheel Drive Loader" 6 "Forklift" 5 "Excavator" 4 "Crawler" 3 "Backhoe" 2 "Articulated Dump Truck" 1 "Skid Steer Loader" 127 "Not Available" 0 "Non-specific System" ;
VAL_ 3221225472 VehicleSystem2 16 "Skidder" 15 "Earth Work" 14 "Special Crops" 13 "Powered Auxiliary Device" 12 "Farm Yard Operations" 11 "Transport/Trailer" 10 "Irrigation" 9 "Forage" 8 "Root Harvesters" 7 "Harvesters" 6 "Sprayers" 5 "Fertilizers" 4 "Planters/Seeders" 3 "Secondary Tillage" 2 "Tillage" 1 "Tractor" 127 "Not Available" 0 "Non-specific System" ;
VAL_ 3221225472 VehicleSystem1 2 "Trailer" 1 "Tractor" 127 "Not Available" 0 "Non-specific System" ;
VAL_ 3221225472 AxleGroupLocation 3 "TrailerFAxleGroup" 2 "TrailerEAxleGroup" 1 "SteerAxleGroup" 0 "Reserved" ;
VAL_ 3221225472 AftrcoolerCoolantThermostatMode 3 "DontCare_Reserved" 2 "Reserved" 1 "PosCtrlMode" 0 "TempCtrlMode" ;
VAL_ 3221225472 AddtnlTrlrAxlGrpWeightAvailable 3 "NotAvailable_NotApplicable" 2 "Reserved" 1 "AddtonalTrailerAxleGroupPresent" 0 "AddtnlTrilerAxleGroupNotPresent" ;
VAL_ 3221225472 TrilerHAxleGroupWeightAvailable 3 "NotAvailable_NotApplicable" 2 "Reserved" 1 "TrailerHAxleGroupPresent" 0 "TrailerHAxleGroupNotPresent" ;
VAL_ 3221225472 TrilerGAxleGroupWeightAvailable 3 "NotAvailable_NotApplicable" 2 "Reserved" 1 "TrailerGAxleGroupPresent" 0 "TrailerGAxleGroupNotPresent" ;
VAL_ 3221225472 TrilerFAxleGroupWeightAvailable 3 "NotAvailable_NotApplicable" 2 "Reserved" 1 "TrailerFAxleGroupPresent" 0 "TrailerFAxleGroupNotPresent" ;
VAL_ 3221225472 TrilerEAxleGroupWeightAvailable 3 "NotAvailable_NotApplicable" 2 "Reserved" 1 "TrailerEAxleGroupPresent" 0 "TrailerEAxleGroupNotPresent" ;
VAL_ 3221225472 TrilerDAxleGroupWeightAvailable 3 "NotAvailable_NotApplicable" 2 "Reserved" 1 "TrailerDAxleGroupPresent" 0 "TrailerDAxleGroupNotPresent" ;
VAL_ 3221225472 TrilerCAxleGroupWeightAvailable 3 "NotAvailable_NotApplicable" 2 "Reserved" 1 "TrailerCAxleGroupPresent" 0 "TrailerCAxleGroupNotPresent" ;
VAL_ 3221225472 TrilerBAxleGroupWeightAvailable 3 "NotAvailable_NotApplicable" 2 "Reserved" 1 "TrailerBAxleGroupPresent" 0 "TrailerBAxleGroupNotPresent" ;
VAL_ 3221225472 TrilerAAxleGroupWeightAvailable 3 "NotAvailable_NotApplicable" 2 "Reserved" 1 "TrailerAAxleGroupPresent" 0 "TrailerAAxleGroupNotPresent" ;
VAL_ 3221225472 AddtnlTrctrAxlGrpWightAvailable 3 "NotAvailable_NotApplicable" 2 "Reserved" 1 "AddtonalTractorAxleGroupPresent" 0 "AddtnlTrctorAxleGroupNotPresent" ;
VAL_ 3221225472 TagAxleGroupWeightAvailable 3 "NotAvailable_NotApplicable" 2 "Reserved" 1 "TagAxleGroupPresent" 0 "TagAxleGroupNotPresent" ;
VAL_ 3221225472 DriveAxleGroupWeightAvailable 3 "NotAvailable_NotApplicable" 2 "Reserved" 1 "DriveAxleGroupPresent" 0 "DriveAxleGroupNotPresent" ;
VAL_ 3221225472 LiftAxleGroupWeightAvailable 3 "NotAvailable_NotApplicable" 2 "Reserved" 1 "LiftAxleGroupPresent" 0 "LiftAxleGroupNotPresent" ;
VAL_ 3221225472 SteerAxleGroupWeightAvailable 3 "NotAvailable_NotApplicable" 2 "Reserved" 1 "SteerAxleGroupPresent" 0 "SteerAxleGroupNotPresent" ;
VAL_ 3221225472 ZeroNetVehicleWeightChange 3 "NotAvailable_NotApplicable" 2 "Reserved" 1 "ZeroNetVehicleWeightChange" 0 "NChangeToNetVehicleWeightChange" ;
VAL_ 3221225472 AETCDataCollectionStandard 15 "NotAvailable" 1 "1101NotDefined" 0 "SAEJ1995" ;
VAL_ 3221225472 RightHeadlampLightDistribution 15 "NotAvailable" 8 "1110Reserved" 7 "DffrntLghtDstrbtnsNtAvlblNAFSDs" 6 "LghtDstrbtnFlrMdlIsDmgdCrrntPsM" 5 "LghtDstrbtnFlSfPsMdlIsDmgdCrrnt" 4 "LghtDstrbtnAdvrsWthrAdvrsWthrLg" 3 "LghtDstrbtnHghBmHghBmDstrbtnOfT" 2 "LghtDstrbtnMtrwyTskOfMtrwyLghtI" 1 "LghtDstrbtnCntryCntryLghtIsMstl" 0 "LghtDstrbtnTwnBscLghtDstrbtnFrT" ;
VAL_ 3221225472 LeftHeadlampLightDistribution 15 "NotAvailable" 8 "1110Reserved" 7 "DffrntLghtDstrbtnsNtAvlblNAFSDs" 6 "LghtDstrbtnFlrMdlIsDmgdCrrntPsM" 5 "LghtDstrbtnFlSfPsMdlIsDmgdCrrnt" 4 "LghtDstrbtnAdvrsWthrAdvrsWthrLg" 3 "LghtDstrbtnHghBmHghBmDstrbtnOfT" 2 "LghtDstrbtnMtrwyTskOfMtrwyLghtI" 1 "LghtDstrbtnCntryCntryLghtIsMstl" 0 "LghtDstrbtnTwnBscLghtDstrbtnFrT" ;
VAL_ 3221225472 RghtHeadlampDynamicBendingLight 7 "NotAvailable" 4 "110Reserved" 3 "DynmcBndngLghtFlrBndngLghtDsNtW" 2 "DynmcBndngLghtFlSfPsBndngLghtIs" 1 "DynmcBndngLghtIsWrkngPrprlyNrml" 0 "DynmcBndngLghtDctvtdThrIsNPrblm" ;
VAL_ 3221225472 LeftHeadlampDynamicBendingLight 7 "NotAvailable" 4 "110Reserved" 3 "DynmcBndngLghtFlrBndngLghtDsNtW" 2 "DynmcBndngLghtFlSfPsBndngLghtIs" 1 "DynmcBndngLghtIsWrkngPrprlyNrml" 0 "DynmcBndngLghtDctvtdThrIsNPrblm" ;
VAL_ 3221225472 AuxI_O45 3 "NtAvlblTkNoActionDependingOnApp" 2 "ErrrIndctrNotUsedDependingOnApp" 1 "AuxChannelOn" 0 "AuxChannelOff" ;
VAL_ 3221225472 AuxI_O46 3 "NtAvlblTkNoActionDependingOnApp" 2 "ErrrIndctrNotUsedDependingOnApp" 1 "AuxChannelOn" 0 "AuxChannelOff" ;
VAL_ 3221225472 AuxI_O47 3 "NtAvlblTkNoActionDependingOnApp" 2 "ErrrIndctrNotUsedDependingOnApp" 1 "AuxChannelOn" 0 "AuxChannelOff" ;
VAL_ 3221225472 AuxI_O48 3 "NtAvlblTkNoActionDependingOnApp" 2 "ErrrIndctrNotUsedDependingOnApp" 1 "AuxChannelOn" 0 "AuxChannelOff" ;
VAL_ 3221225472 AuxI_O41 3 "NtAvlblTkNoActionDependingOnApp" 2 "ErrrIndctrNotUsedDependingOnApp" 1 "AuxChannelOn" 0 "AuxChannelOff" ;
VAL_ 3221225472 AuxI_O42 3 "NtAvlblTkNoActionDependingOnApp" 2 "ErrrIndctrNotUsedDependingOnApp" 1 "AuxChannelOn" 0 "AuxChannelOff" ;
VAL_ 3221225472 AuxI_O43 3 "NtAvlblTkNoActionDependingOnApp" 2 "ErrrIndctrNotUsedDependingOnApp" 1 "AuxChannelOn" 0 "AuxChannelOff" ;
VAL_ 3221225472 AuxI_O44 3 "NtAvlblTkNoActionDependingOnApp" 2 "ErrrIndctrNotUsedDependingOnApp" 1 "AuxChannelOn" 0 "AuxChannelOff" ;
VAL_ 3221225472 AuxI_O37 3 "NtAvlblTkNoActionDependingOnApp" 2 "ErrrIndctrNotUsedDependingOnApp" 1 "AuxChannelOn" 0 "AuxChannelOff" ;
VAL_ 3221225472 AuxI_O38 3 "NtAvlblTkNoActionDependingOnApp" 2 "ErrrIndctrNotUsedDependingOnApp" 1 "AuxChannelOn" 0 "AuxChannelOff" ;
VAL_ 3221225472 AuxI_O39 3 "NtAvlblTkNoActionDependingOnApp" 2 "ErrrIndctrNotUsedDependingOnApp" 1 "AuxChannelOn" 0 "AuxChannelOff" ;
VAL_ 3221225472 AuxI_O40 3 "NtAvlblTkNoActionDependingOnApp" 2 "ErrrIndctrNotUsedDependingOnApp" 1 "AuxChannelOn" 0 "AuxChannelOff" ;
VAL_ 3221225472 AuxI_O33 3 "NtAvlblTkNoActionDependingOnApp" 2 "ErrrIndctrNotUsedDependingOnApp" 1 "AuxChannelOn" 0 "AuxChannelOff" ;
VAL_ 3221225472 AuxI_O34 3 "NtAvlblTkNoActionDependingOnApp" 2 "ErrrIndctrNotUsedDependingOnApp" 1 "AuxChannelOn" 0 "AuxChannelOff" ;
VAL_ 3221225472 AuxI_O35 3 "NtAvlblTkNoActionDependingOnApp" 2 "ErrrIndctrNotUsedDependingOnApp" 1 "AuxChannelOn" 0 "AuxChannelOff" ;
VAL_ 3221225472 AuxI_O36 3 "NtAvlblTkNoActionDependingOnApp" 2 "ErrrIndctrNotUsedDependingOnApp" 1 "AuxChannelOn" 0 "AuxChannelOff" ;
VAL_ 3221225472 AuxI_O29 3 "NtAvlblTkNoActionDependingOnApp" 2 "ErrrIndctrNotUsedDependingOnApp" 1 "AuxChannelOn" 0 "AuxChannelOff" ;
VAL_ 3221225472 AuxI_O30 3 "NtAvlblTkNoActionDependingOnApp" 2 "ErrrIndctrNotUsedDependingOnApp" 1 "AuxChannelOn" 0 "AuxChannelOff" ;
VAL_ 3221225472 AuxI_O31 3 "NtAvlblTkNoActionDependingOnApp" 2 "ErrrIndctrNotUsedDependingOnApp" 1 "AuxChannelOn" 0 "AuxChannelOff" ;
VAL_ 3221225472 AuxI_O32 3 "NtAvlblTkNoActionDependingOnApp" 2 "ErrrIndctrNotUsedDependingOnApp" 1 "AuxChannelOn" 0 "AuxChannelOff" ;
VAL_ 3221225472 AuxI_O25 3 "NtAvlblTkNoActionDependingOnApp" 2 "ErrrIndctrNotUsedDependingOnApp" 1 "AuxChannelOn" 0 "AuxChannelOff" ;
VAL_ 3221225472 AuxI_O26 3 "NtAvlblTkNoActionDependingOnApp" 2 "ErrrIndctrNotUsedDependingOnApp" 1 "AuxChannelOn" 0 "AuxChannelOff" ;
VAL_ 3221225472 AuxI_O27 3 "NtAvlblTkNoActionDependingOnApp" 2 "ErrrIndctrNotUsedDependingOnApp" 1 "AuxChannelOn" 0 "AuxChannelOff" ;
VAL_ 3221225472 AuxI_O28 3 "NtAvlblTkNoActionDependingOnApp" 2 "ErrrIndctrNotUsedDependingOnApp" 1 "AuxChannelOn" 0 "AuxChannelOff" ;
VAL_ 3221225472 AuxI_O21 3 "NtAvlblTkNoActionDependingOnApp" 2 "ErrrIndctrNotUsedDependingOnApp" 1 "AuxChannelOn" 0 "AuxChannelOff" ;
VAL_ 3221225472 AuxI_O22 3 "NtAvlblTkNoActionDependingOnApp" 2 "ErrrIndctrNotUsedDependingOnApp" 1 "AuxChannelOn" 0 "AuxChannelOff" ;
VAL_ 3221225472 AuxI_O23 3 "NtAvlblTkNoActionDependingOnApp" 2 "ErrrIndctrNotUsedDependingOnApp" 1 "AuxChannelOn" 0 "AuxChannelOff" ;
VAL_ 3221225472 AuxI_O24 3 "NtAvlblTkNoActionDependingOnApp" 2 "ErrrIndctrNotUsedDependingOnApp" 1 "AuxChannelOn" 0 "AuxChannelOff" ;
VAL_ 3221225472 AuxI_O17 3 "NtAvlblTkNoActionDependingOnApp" 2 "ErrrIndctrNotUsedDependingOnApp" 1 "AuxChannelOn" 0 "AuxChannelOff" ;
VAL_ 3221225472 AuxI_O18 3 "NtAvlblTkNoActionDependingOnApp" 2 "ErrrIndctrNotUsedDependingOnApp" 1 "AuxChannelOn" 0 "AuxChannelOff" ;
VAL_ 3221225472 AuxI_O19 3 "NtAvlblTkNoActionDependingOnApp" 2 "ErrrIndctrNotUsedDependingOnApp" 1 "AuxChannelOn" 0 "AuxChannelOff" ;
VAL_ 3221225472 AuxI_O20 3 "NtAvlblTkNoActionDependingOnApp" 2 "ErrrIndctrNotUsedDependingOnApp" 1 "AuxChannelOn" 0 "AuxChannelOff" ;
VAL_ 3221225472 AuxI_O77 3 "NtAvlblTkNoActionDependingOnApp" 2 "ErrrIndctrNotUsedDependingOnApp" 1 "AuxChannelOn" 0 "AuxChannelOff" ;
VAL_ 3221225472 AuxI_O78 3 "NtAvlblTkNoActionDependingOnApp" 2 "ErrrIndctrNotUsedDependingOnApp" 1 "AuxChannelOn" 0 "AuxChannelOff" ;
VAL_ 3221225472 AuxI_O79 3 "NtAvlblTkNoActionDependingOnApp" 2 "ErrrIndctrNotUsedDependingOnApp" 1 "AuxChannelOn" 0 "AuxChannelOff" ;
VAL_ 3221225472 AuxI_O80 3 "NtAvlblTkNoActionDependingOnApp" 2 "ErrrIndctrNotUsedDependingOnApp" 1 "AuxChannelOn" 0 "AuxChannelOff" ;
VAL_ 3221225472 AuxI_O73 3 "NtAvlblTkNoActionDependingOnApp" 2 "ErrrIndctrNotUsedDependingOnApp" 1 "AuxChannelOn" 0 "AuxChannelOff" ;
VAL_ 3221225472 AuxI_O74 3 "NtAvlblTkNoActionDependingOnApp" 2 "ErrrIndctrNotUsedDependingOnApp" 1 "AuxChannelOn" 0 "AuxChannelOff" ;
VAL_ 3221225472 AuxI_O75 3 "NtAvlblTkNoActionDependingOnApp" 2 "ErrrIndctrNotUsedDependingOnApp" 1 "AuxChannelOn" 0 "AuxChannelOff" ;
VAL_ 3221225472 AuxI_O76 3 "NtAvlblTkNoActionDependingOnApp" 2 "ErrrIndctrNotUsedDependingOnApp" 1 "AuxChannelOn" 0 "AuxChannelOff" ;
VAL_ 3221225472 AuxI_O69 3 "NtAvlblTkNoActionDependingOnApp" 2 "ErrrIndctrNotUsedDependingOnApp" 1 "AuxChannelOn" 0 "AuxChannelOff" ;
VAL_ 3221225472 AuxI_O70 3 "NtAvlblTkNoActionDependingOnApp" 2 "ErrrIndctrNotUsedDependingOnApp" 1 "AuxChannelOn" 0 "AuxChannelOff" ;
VAL_ 3221225472 AuxI_O71 3 "NtAvlblTkNoActionDependingOnApp" 2 "ErrrIndctrNotUsedDependingOnApp" 1 "AuxChannelOn" 0 "AuxChannelOff" ;
VAL_ 3221225472 AuxI_O72 3 "NtAvlblTkNoActionDependingOnApp" 2 "ErrrIndctrNotUsedDependingOnApp" 1 "AuxChannelOn" 0 "AuxChannelOff" ;
VAL_ 3221225472 AuxI_O65 3 "NtAvlblTkNoActionDependingOnApp" 2 "ErrrIndctrNotUsedDependingOnApp" 1 "AuxChannelOn" 0 "AuxChannelOff" ;
VAL_ 3221225472 AuxI_O66 3 "NtAvlblTkNoActionDependingOnApp" 2 "ErrrIndctrNotUsedDependingOnApp" 1 "AuxChannelOn" 0 "AuxChannelOff" ;
VAL_ 3221225472 AuxI_O67 3 "NtAvlblTkNoActionDependingOnApp" 2 "ErrrIndctrNotUsedDependingOnApp" 1 "AuxChannelOn" 0 "AuxChannelOff" ;
VAL_ 3221225472 AuxI_O68 3 "NtAvlblTkNoActionDependingOnApp" 2 "ErrrIndctrNotUsedDependingOnApp" 1 "AuxChannelOn" 0 "AuxChannelOff" ;
VAL_ 3221225472 AuxI_O61 3 "NtAvlblTkNoActionDependingOnApp" 2 "ErrrIndctrNotUsedDependingOnApp" 1 "AuxChannelOn" 0 "AuxChannelOff" ;
VAL_ 3221225472 AuxI_O62 3 "NtAvlblTkNoActionDependingOnApp" 2 "ErrrIndctrNotUsedDependingOnApp" 1 "AuxChannelOn" 0 "AuxChannelOff" ;
VAL_ 3221225472 AuxI_O63 3 "NtAvlblTkNoActionDependingOnApp" 2 "ErrrIndctrNotUsedDependingOnApp" 1 "AuxChannelOn" 0 "AuxChannelOff" ;
VAL_ 3221225472 AuxI_O64 3 "NtAvlblTkNoActionDependingOnApp" 2 "ErrrIndctrNotUsedDependingOnApp" 1 "AuxChannelOn" 0 "AuxChannelOff" ;
VAL_ 3221225472 AuxI_O57 3 "NtAvlblTkNoActionDependingOnApp" 2 "ErrrIndctrNotUsedDependingOnApp" 1 "AuxChannelOn" 0 "AuxChannelOff" ;
VAL_ 3221225472 AuxI_O58 3 "NtAvlblTkNoActionDependingOnApp" 2 "ErrrIndctrNotUsedDependingOnApp" 1 "AuxChannelOn" 0 "AuxChannelOff" ;
VAL_ 3221225472 AuxI_O59 3 "NtAvlblTkNoActionDependingOnApp" 2 "ErrrIndctrNotUsedDependingOnApp" 1 "AuxChannelOn" 0 "AuxChannelOff" ;
VAL_ 3221225472 AuxI_O60 3 "NtAvlblTkNoActionDependingOnApp" 2 "ErrrIndctrNotUsedDependingOnApp" 1 "AuxChannelOn" 0 "AuxChannelOff" ;
VAL_ 3221225472 AuxI_O53 3 "NtAvlblTkNoActionDependingOnApp" 2 "ErrrIndctrNotUsedDependingOnApp" 1 "AuxChannelOn" 0 "AuxChannelOff" ;
VAL_ 3221225472 AuxI_O54 3 "NtAvlblTkNoActionDependingOnApp" 2 "ErrrIndctrNotUsedDependingOnApp" 1 "AuxChannelOn" 0 "AuxChannelOff" ;
VAL_ 3221225472 AuxI_O55 3 "NtAvlblTkNoActionDependingOnApp" 2 "ErrrIndctrNotUsedDependingOnApp" 1 "AuxChannelOn" 0 "AuxChannelOff" ;
VAL_ 3221225472 AuxI_O56 3 "NtAvlblTkNoActionDependingOnApp" 2 "ErrrIndctrNotUsedDependingOnApp" 1 "AuxChannelOn" 0 "AuxChannelOff" ;
VAL_ 3221225472 AuxI_O49 3 "NtAvlblTkNoActionDependingOnApp" 2 "ErrrIndctrNotUsedDependingOnApp" 1 "AuxChannelOn" 0 "AuxChannelOff" ;
VAL_ 3221225472 AuxI_O50 3 "NtAvlblTkNoActionDependingOnApp" 2 "ErrrIndctrNotUsedDependingOnApp" 1 "AuxChannelOn" 0 "AuxChannelOff" ;
VAL_ 3221225472 AuxI_O51 3 "NtAvlblTkNoActionDependingOnApp" 2 "ErrrIndctrNotUsedDependingOnApp" 1 "AuxChannelOn" 0 "AuxChannelOff" ;
VAL_ 3221225472 AuxI_O52 3 "NtAvlblTkNoActionDependingOnApp" 2 "ErrrIndctrNotUsedDependingOnApp" 1 "AuxChannelOn" 0 "AuxChannelOff" ;
VAL_ 3221225472 AuxI_O92 3 "NtAvlblTkNoActionDependingOnApp" 2 "ErrrIndctrNotUsedDependingOnApp" 1 "AuxChannelOn" 0 "AuxChannelOff" ;
VAL_ 3221225472 AuxI_O85 3 "NtAvlblTkNoActionDependingOnApp" 2 "ErrrIndctrNotUsedDependingOnApp" 1 "AuxChannelOn" 0 "AuxChannelOff" ;
VAL_ 3221225472 AuxI_O86 3 "NtAvlblTkNoActionDependingOnApp" 2 "ErrrIndctrNotUsedDependingOnApp" 1 "AuxChannelOn" 0 "AuxChannelOff" ;
VAL_ 3221225472 AuxI_O87 3 "NtAvlblTkNoActionDependingOnApp" 2 "ErrrIndctrNotUsedDependingOnApp" 1 "AuxChannelOn" 0 "AuxChannelOff" ;
VAL_ 3221225472 AuxI_O88 3 "NtAvlblTkNoActionDependingOnApp" 2 "ErrrIndctrNotUsedDependingOnApp" 1 "AuxChannelOn" 0 "AuxChannelOff" ;
VAL_ 3221225472 AuxI_O81 3 "NtAvlblTkNoActionDependingOnApp" 2 "ErrrIndctrNotUsedDependingOnApp" 1 "AuxChannelOn" 0 "AuxChannelOff" ;
VAL_ 3221225472 AuxI_O82 3 "NtAvlblTkNoActionDependingOnApp" 2 "ErrrIndctrNotUsedDependingOnApp" 1 "AuxChannelOn" 0 "AuxChannelOff" ;
VAL_ 3221225472 AuxI_O83 3 "NtAvlblTkNoActionDependingOnApp" 2 "ErrrIndctrNotUsedDependingOnApp" 1 "AuxChannelOn" 0 "AuxChannelOff" ;
VAL_ 3221225472 AuxI_O84 3 "NtAvlblTkNoActionDependingOnApp" 2 "ErrrIndctrNotUsedDependingOnApp" 1 "AuxChannelOn" 0 "AuxChannelOff" ;
VAL_ 3221225472 AuxI_O109 3 "NtAvlblTkNoActionDependingOnApp" 2 "ErrrIndctrNotUsedDependingOnApp" 1 "AuxChannelOn" 0 "AuxChannelOff" ;
VAL_ 3221225472 AuxI_O110 3 "NtAvlblTkNoActionDependingOnApp" 2 "ErrrIndctrNotUsedDependingOnApp" 1 "AuxChannelOn" 0 "AuxChannelOff" ;
VAL_ 3221225472 AuxI_O111 3 "NtAvlblTkNoActionDependingOnApp" 2 "ErrrIndctrNotUsedDependingOnApp" 1 "AuxChannelOn" 0 "AuxChannelOff" ;
VAL_ 3221225472 AuxI_O112 3 "NtAvlblTkNoActionDependingOnApp" 2 "ErrrIndctrNotUsedDependingOnApp" 1 "AuxChannelOn" 0 "AuxChannelOff" ;
VAL_ 3221225472 AuxI_O105 3 "NtAvlblTkNoActionDependingOnApp" 2 "ErrrIndctrNotUsedDependingOnApp" 1 "AuxChannelOn" 0 "AuxChannelOff" ;
VAL_ 3221225472 AuxI_O106 3 "NtAvlblTkNoActionDependingOnApp" 2 "ErrrIndctrNotUsedDependingOnApp" 1 "AuxChannelOn" 0 "AuxChannelOff" ;
VAL_ 3221225472 AuxI_O107 3 "NtAvlblTkNoActionDependingOnApp" 2 "ErrrIndctrNotUsedDependingOnApp" 1 "AuxChannelOn" 0 "AuxChannelOff" ;
VAL_ 3221225472 AuxI_O108 3 "NtAvlblTkNoActionDependingOnApp" 2 "ErrrIndctrNotUsedDependingOnApp" 1 "AuxChannelOn" 0 "AuxChannelOff" ;
VAL_ 3221225472 AuxI_O101 2 "ErrrIndctrNotUsedDependingOnApp" 1 "AuxChannelOn" 0 "AuxChannelOff" 3 "NtAvlblTkNoActionDependingOnApp" ;
VAL_ 3221225472 AuxI_O102 3 "NtAvlblTkNoActionDependingOnApp" 2 "ErrrIndctrNotUsedDependingOnApp" 1 "AuxChannelOn" 0 "AuxChannelOff" ;
VAL_ 3221225472 AuxI_O103 3 "NtAvlblTkNoActionDependingOnApp" 2 "ErrrIndctrNotUsedDependingOnApp" 1 "AuxChannelOn" 0 "AuxChannelOff" ;
VAL_ 3221225472 AuxI_O104 3 "NtAvlblTkNoActionDependingOnApp" 2 "ErrrIndctrNotUsedDependingOnApp" 1 "AuxChannelOn" 0 "AuxChannelOff" ;
VAL_ 3221225472 AuxI_O97 3 "NtAvlblTkNoActionDependingOnApp" 2 "ErrrIndctrNotUsedDependingOnApp" 1 "AuxChannelOn" 0 "AuxChannelOff" ;
VAL_ 3221225472 AuxI_O98 3 "NtAvlblTkNoActionDependingOnApp" 2 "ErrrIndctrNotUsedDependingOnApp" 1 "AuxChannelOn" 0 "AuxChannelOff" ;
VAL_ 3221225472 AuxI_O99 3 "NtAvlblTkNoActionDependingOnApp" 2 "ErrrIndctrNotUsedDependingOnApp" 1 "AuxChannelOn" 0 "AuxChannelOff" ;
VAL_ 3221225472 AuxI_O100 3 "NtAvlblTkNoActionDependingOnApp" 2 "ErrrIndctrNotUsedDependingOnApp" 1 "AuxChannelOn" 0 "AuxChannelOff" ;
VAL_ 3221225472 AuxI_O93 3 "NtAvlblTkNoActionDependingOnApp" 2 "ErrrIndctrNotUsedDependingOnApp" 1 "AuxChannelOn" 0 "AuxChannelOff" ;
VAL_ 3221225472 AuxI_O94 3 "NtAvlblTkNoActionDependingOnApp" 2 "ErrrIndctrNotUsedDependingOnApp" 1 "AuxChannelOn" 0 "AuxChannelOff" ;
VAL_ 3221225472 AuxI_O95 3 "NtAvlblTkNoActionDependingOnApp" 2 "ErrrIndctrNotUsedDependingOnApp" 1 "AuxChannelOn" 0 "AuxChannelOff" ;
VAL_ 3221225472 AuxI_O96 3 "NtAvlblTkNoActionDependingOnApp" 2 "ErrrIndctrNotUsedDependingOnApp" 1 "AuxChannelOn" 0 "AuxChannelOff" ;
VAL_ 3221225472 AuxI_O89 3 "NtAvlblTkNoActionDependingOnApp" 2 "ErrrIndctrNotUsedDependingOnApp" 1 "AuxChannelOn" 0 "AuxChannelOff" ;
VAL_ 3221225472 AuxI_O90 3 "NtAvlblTkNoActionDependingOnApp" 2 "ErrrIndctrNotUsedDependingOnApp" 1 "AuxChannelOn" 0 "AuxChannelOff" ;
VAL_ 3221225472 AuxI_O91 3 "NtAvlblTkNoActionDependingOnApp" 2 "ErrrIndctrNotUsedDependingOnApp" 1 "AuxChannelOn" 0 "AuxChannelOff" ;
VAL_ 3221225472 TrailerBrakeStrokeAxle5Right 7 "NotAvailable" 6 "SensorError" 5 "Reserved" 3 "DraggingBrake" 2 "Overstroke" 1 "Nonfunctioning" 0 "OK" ;
VAL_ 3221225472 TrailerBrakeStrokeAxle5Left 7 "NotAvailable" 6 "SensorError" 5 "Reserved" 3 "DraggingBrake" 2 "Overstroke" 1 "Nonfunctioning" 0 "OK" ;
VAL_ 3221225472 TrailerBrakeStrokeAxle4Right 7 "NotAvailable" 6 "SensorError" 5 "Reserved" 3 "DraggingBrake" 2 "Overstroke" 1 "Nonfunctioning" 0 "OK" ;
VAL_ 3221225472 TrailerBrakeStrokeAxle4Left 7 "NotAvailable" 6 "SensorError" 5 "Reserved" 3 "DraggingBrake" 2 "Overstroke" 1 "Nonfunctioning" 0 "OK" ;
VAL_ 3221225472 TrailerBrakeStrokeAxle3Right 7 "NotAvailable" 6 "SensorError" 5 "Reserved" 3 "DraggingBrake" 2 "Overstroke" 1 "Nonfunctioning" 0 "OK" ;
VAL_ 3221225472 TrailerBrakeStrokeAxle3Left 7 "NotAvailable" 6 "SensorError" 5 "Reserved" 3 "DraggingBrake" 2 "Overstroke" 1 "Nonfunctioning" 0 "OK" ;
VAL_ 3221225472 TrailerBrakeStrokeAxle2Right 7 "NotAvailable" 6 "SensorError" 5 "Reserved" 3 "DraggingBrake" 2 "Overstroke" 1 "Nonfunctioning" 0 "OK" ;
VAL_ 3221225472 TrailerBrakeStrokeAxle2Left 7 "NotAvailable" 6 "SensorError" 5 "Reserved" 3 "DraggingBrake" 2 "Overstroke" 1 "Nonfunctioning" 0 "OK" ;
VAL_ 3221225472 TrailerBrakeStrokeAxle1Right 7 "NotAvailable" 6 "SensorError" 5 "Reserved" 3 "DraggingBrake" 2 "Overstroke" 1 "Nonfunctioning" 0 "OK" ;
VAL_ 3221225472 TrailerBrakeStrokeAxle1Left 7 "NotAvailable" 6 "SensorError" 5 "Reserved" 3 "DraggingBrake" 2 "Overstroke" 1 "Nonfunctioning" 0 "OK" ;
VAL_ 3221225472 TractorBrakeStrokeAxle5Right 7 "NotAvailable" 6 "SensorError" 5 "Reserved" 3 "DraggingBrake" 2 "Overstroke" 1 "Nonfunctioning" 0 "OK" ;
VAL_ 3221225472 TractorBrakeStrokeAxle5Left 7 "NotAvailable" 6 "SensorError" 5 "Reserved" 3 "DraggingBrake" 2 "Overstroke" 1 "Nonfunctioning" 0 "OK" ;
VAL_ 3221225472 TractorBrakeStrokeAxle4Right 7 "NotAvailable" 6 "SensorError" 5 "Reserved" 3 "DraggingBrake" 2 "Overstroke" 1 "Nonfunctioning" 0 "OK" ;
VAL_ 3221225472 TractorBrakeStrokeAxle4Left 7 "NotAvailable" 6 "SensorError" 5 "Reserved" 3 "DraggingBrake" 2 "Overstroke" 1 "Nonfunctioning" 0 "OK" ;
VAL_ 3221225472 TractorBrakeStrokeAxle3Right 7 "NotAvailable" 6 "SensorError" 5 "Reserved" 3 "DraggingBrake" 2 "Overstroke" 1 "Nonfunctioning" 0 "OK" ;
VAL_ 3221225472 TractorBrakeStrokeAxle3Left 7 "NotAvailable" 6 "SensorError" 5 "Reserved" 3 "DraggingBrake" 2 "Overstroke" 1 "Nonfunctioning" 0 "OK" ;
VAL_ 3221225472 TractorBrakeStrokeAxle2Right 7 "NotAvailable" 6 "SensorError" 5 "Reserved" 3 "DraggingBrake" 2 "Overstroke" 1 "Nonfunctioning" 0 "OK" ;
VAL_ 3221225472 TractorBrakeStrokeAxle2Left 7 "NotAvailable" 6 "SensorError" 5 "Reserved" 3 "DraggingBrake" 2 "Overstroke" 1 "Nonfunctioning" 0 "OK" ;
VAL_ 3221225472 TractorBrakeStrokeAxle1Right 7 "NotAvailable" 6 "SensorError" 5 "Reserved" 3 "DraggingBrake" 2 "Overstroke" 1 "Nonfunctioning" 0 "OK" ;
VAL_ 3221225472 TractorBrakeStrokeAxle1Left 7 "NotAvailable" 6 "SensorError" 5 "Reserved" 3 "DraggingBrake" 2 "Overstroke" 1 "Nonfunctioning" 0 "OK" ;
VAL_ 3221225472 AirCompressorStatus 3 "NotAvailable" 2 "ErrorIndicator" 1 "CompressorActive" 0 "CompressorNotActive" ;
VAL_ 3221225472 RqedACCDistanceMode 7 "notAvailable" 6 "errorCondition" 5 "notDefined" 4 "RqedACCDistanceMode5" 3 "RqedACCDistanceMode4" 2 "RqedACCDistanceMode3" 1 "RqedACCDistanceMode2" 0 "RqedACCDistanceMode1" ;
VAL_ 3221225472 ACCDistanceAlertSignal 3 "TakeNoAction" 2 "Reserved" 1 "ACCDASActive" 0 "ACCDASNotActive" ;
VAL_ 3221225472 ACCSystemShutoffWarning 3 "TakeNoAction" 2 "Reserved" 1 "ACCSSOWActive" 0 "ACCSSOWNotActive" ;
VAL_ 3221225472 ACCTargetDetected 3 "TakeNoAction" 2 "Reserved" 1 "TargetDetected" 0 "NoTargetsDetected" ;
VAL_ 3221225472 AdptveCruiseCtrlSetDistanceMode 7 "NotAvailable_NotValid" 6 "ErrorCondition" 5 "ConventionalCruiseCtrlMode" 4 "ACCDistanceMode5" 3 "ACCDistanceMode4" 2 "ACCDistanceMode3" 1 "ACCDistanceMode2" 0 "ACCDistanceMode1" ;
VAL_ 3221225472 AdaptiveCruiseCtrlMode 7 "NotAvailable_NotValid" 6 "DsbldErrrCndtnUsdTIndctThtACCIs" 5 "FinishMode" 4 "HldMdUsdTIndctThtACCHsLstThPrvs" 3 "OvertakeMode" 2 "DstncCtrlActvUsdTIndctThtACCIsO" 1 "SpeedCtrlActive" 0 "OffUsdTIndctACCIsEnbldInClbCnfg" ;
VAL_ 3221225472 Status2OfDoors 3 "notAvailable" 2 "error" 1 "atLeast1BusDoorEnabled" 0 "allBusDoorsAreDisabled" ;
VAL_ 3221225472 Ramp_WheelChairLiftPos 3 "NotAvailable" 2 "Error" 1 "OutsideBus" 0 "InsideBus" ;
VAL_ 3221225472 PosOfDoors 15 "NotAvailable" 14 "Error" 3 "1101NotDefined" 2 "AllDoorsClosed" 1 "ClosingLastDoor" 0 "AtLeast1DoorIsOpen" ;
VAL_ 3221225472 FifthWheelRollWarningIndicator 3 "NotAvailable" 2 "error" 1 "LimitExceeded" 0 "LimitNotExceeded" ;
VAL_ 3221225472 FifthWheelSliderLockIndicator 3 "NotAvailable" 2 "Error" 1 "Locked" 0 "NotLocked" ;
VAL_ 3221225472 FfthWhlLckCoupleStatusIndicator 3 "NotAvailable" 2 "Error" 1 "SuccessfulCoupleDetected" 0 "IncmpltBdCplTrckShuldNotBeMoved" ;
VAL_ 3221225472 FfthWhlLckRadyToCoupleIndicator 3 "NotAvailable" 2 "Error" 1 "LockOpenReadyToCouple" 0 "LockNotOpenNotReadyToCouple" ;
VAL_ 3221225472 FifthWheelErrorStatus 15 "NotAvailable" 9 "Kingpin_LockOpen" 8 "KingpinMissingMoreThan5Seconds" 7 "CouplingTimingError" 6 "CouplingSequenceError_Kingpin" 5 "CouplingSequenceError" 14 "NotUsed" 2 "Kingpin_LocksOpenAtStartup" 1 "LocksClosed_NoKingpinAtStartup" 0 "ImproperCouple" ;
VAL_ 3221225472 PitchAndRollCompensated 1 "NotAvailable" 0 "CompensationOn" ;
VAL_ 3221225472 PitchRateFigureOfMerit 1 "NotAvailable" 0 "PtchRtDgrddDtIsSspctDTEnvrnmntl" ;
VAL_ 3221225472 RollAngleFigureOfMerit 1 "NotAvailable" 0 "RllAnglDgrddDtIsSspctDTEnvrnmnt" ;
VAL_ 3221225472 PitchAngleFigureOfMerit 1 "NotAvailable" 0 "PtchAnglDgrddDtIsSspctDTEnvrnmn" ;
VAL_ 3221225472 TransOilLevelMeasurementStatus 15 "NotAvailable" 14 "Error" 13 "ConditionsNotValidOther" 12 "NotDefined" 8 "CndtionsNotValidEngSpeedTooHigh" 7 "CnditionsNotValidEngSpeedTooLow" 6 "CndtionsNotValidVehicleNotLevel" 5 "CndtnsNtVldVhclMvngOtptShftSpdT" 4 "CndtnsNtVldTrnsFluidTempTooHigh" 3 "CndtnsNtVldTransFluidTempTooLow" 2 "ConditionsNotValidTransInGear" 1 "CndtnsNtVldSttlngTmrStllCntngDw" 0 "CndtnsVldFrTrnsOlLvlMeasurement" ;
VAL_ 3221225472 TransOilLevelCountdownTimer 15 "NotAvailable" 14 "Error" 13 "ThirteenMinutes" 12 "TwelveMinutes" 11 "ElevenMinutes" 10 "TenMinutes" 9 "NineMinutes" 8 "EightMinutes" 7 "SevenMinutes" 6 "SixMinutes" 5 "FiveMinutes" 4 "FourMinutes" 3 "ThreeMinutes" 2 "TwoMinutes" 1 "OneMinute" 0 "lessThan1Minute" ;
VAL_ 3221225472 WrlessCommunicationNetworkType2 4 "Satellite network" 3 "Wireless LAN #2" 2 "Wireless LAN #1" 1 "CellularNetwork2" 0 "CellularNetwork1" ;
VAL_ 3221225472 NetworkAntennaStatus2 1 "On" 0 "Off" ;
VAL_ 3221225472 NetworkServiceStatus2 1 "RoamingService" 0 "LocalService" ;
VAL_ 3221225472 NetworkTransceiverStatus2 1 "On" 0 "Off" ;
VAL_ 3221225472 WrlessCommunicationNetworkType1 4 "Satellite network" 1 "CellularNetwork2" 0 "CellularNetwork1" 3 "Wireless LAN #2" 2 "Wireless LAN #1" ;
VAL_ 3221225472 NetworkAntennaStatus1 1 "On" 0 "Off" ;
VAL_ 3221225472 NetworkServiceStatus1 1 "RoamingService" 0 "LocalService" ;
VAL_ 3221225472 NetworkTransceiverStatus1 1 "On" 0 "Off" ;
VAL_ 3221225472 VoltageRegulatorEnabled 3 "NotAvailable" 2 "Error" 1 "RegulatingVoltage" 0 "NtRegulatingVoltageUnitDisabled" ;
VAL_ 3221225472 VoltageRegulatorSoftStartState 3 "NotAvailable" 2 "Error" 1 "SoftStartIsActive" 0 "SoftStartIsInactive" ;
VAL_ 3221225472 VltgRgltrUndrfrqncyCmpnstnEnbld 3 "NotAvailable" 2 "Error" 1 "UndrfrquencyCompensationEnabled" 0 "UndrfrqencyCompensationDisabled" ;
VAL_ 3221225472 VltgRgltrVAr_PwrFctrOprtingMode 7 "NotAvailable" 6 "Error" 5 "Reserved" 2 "VArRegulationEnabled" 1 "PowerFactorRegulationEnabled" 0 "VAr_PwrFactorRegulationDisabled" ;
VAL_ 3221225472 VltgRglatorLoadCompensationMode 7 "NotAvailable" 6 "Error" 5 "Reserved" 2 "IRLineDropCompensationEnabled" 1 "VoltageDroopCompensationEnabled" 0 "LoadCompensationDisabled" ;
VAL_ 2566763776 FMI5 24 "Assurance Data Error" 23 "Request DM60 for more info" 22 "Special Instructions #2 " 21 "Data drifted low" 20 "Data drifted high" 31 "Condition exists" 19 "Received network data in error" 18 "Below normal (moderately severe)" 17 "Below normal (least severe)" 16 "Above normal (moderately severe)" 15 "Above normal (least severe)" 14 "Special intstructions" 13 "Out of calibration" 12 "Bad intelligent device" 11 "Root cause not known" 10 "Abnormal rate of change" 9 "Abnormal update rate" 8 "Abnormal frequency" 7 "Mechanical system not responding" 6 "Current above normal" 5 "Current below normal" 4 "Voltage below normal" 3 "Voltage above normal" 2 "Data erratic" 1 "Below normal (most severe)" 0 "Above normal (most severe)" ;
VAL_ 2566763776 FMI4 24 "Assurance Data Error" 23 "Request DM60 for more info" 22 "Special Instructions #2 " 21 "Data drifted low" 20 "Data drifted high" 31 "Condition exists" 19 "Received network data in error" 18 "Below normal (moderately severe)" 17 "Below normal (least severe)" 16 "Above normal (moderately severe)" 15 "Above normal (least severe)" 14 "Special intstructions" 13 "Out of calibration" 12 "Bad intelligent device" 11 "Root cause not known" 10 "Abnormal rate of change" 9 "Abnormal update rate" 8 "Abnormal frequency" 7 "Mechanical system not responding" 6 "Current above normal" 5 "Current below normal" 4 "Voltage below normal" 3 "Voltage above normal" 2 "Data erratic" 1 "Below normal (most severe)" 0 "Above normal (most severe)" ;
VAL_ 2566763776 FMI3 24 "Assurance Data Error" 23 "Request DM60 for more info" 22 "Special Instructions #2 " 21 "Data drifted low" 20 "Data drifted high" 31 "Condition exists" 19 "Received network data in error" 18 "Below normal (moderately severe)" 17 "Below normal (least severe)" 16 "Above normal (moderately severe)" 15 "Above normal (least severe)" 14 "Special intstructions" 13 "Out of calibration" 12 "Bad intelligent device" 11 "Root cause not known" 10 "Abnormal rate of change" 9 "Abnormal update rate" 8 "Abnormal frequency" 7 "Mechanical system not responding" 6 "Current above normal" 5 "Current below normal" 4 "Voltage below normal" 3 "Voltage above normal" 2 "Data erratic" 1 "Below normal (most severe)" 0 "Above normal (most severe)" ;
VAL_ 2566763776 FMI2 24 "Assurance Data Error" 23 "Request DM60 for more info" 22 "Special Instructions #2 " 21 "Data drifted low" 20 "Data drifted high" 31 "Condition exists" 19 "Received network data in error" 18 "Below normal (moderately severe)" 17 "Below normal (least severe)" 16 "Above normal (moderately severe)" 15 "Above normal (least severe)" 14 "Special intstructions" 13 "Out of calibration" 12 "Bad intelligent device" 11 "Root cause not known" 10 "Abnormal rate of change" 9 "Abnormal update rate" 8 "Abnormal frequency" 7 "Mechanical system not responding" 6 "Current above normal" 5 "Current below normal" 4 "Voltage below normal" 3 "Voltage above normal" 2 "Data erratic" 1 "Below normal (most severe)" 0 "Above normal (most severe)" ;
VAL_ 2566763776 FMI1 24 "Assurance Data Error" 23 "Request DM60 for more info" 22 "Special Instructions #2 " 21 "Data drifted low" 20 "Data drifted high" 31 "Condition exists" 19 "Received network data in error" 18 "Below normal (moderately severe)" 17 "Below normal (least severe)" 16 "Above normal (moderately severe)" 15 "Above normal (least severe)" 14 "Special intstructions" 13 "Out of calibration" 12 "Bad intelligent device" 11 "Root cause not known" 10 "Abnormal rate of change" 9 "Abnormal update rate" 8 "Abnormal frequency" 7 "Mechanical system not responding" 6 "Current above normal" 5 "Current below normal" 4 "Voltage below normal" 3 "Voltage above normal" 2 "Data erratic" 1 "Below normal (most severe)" 0 "Above normal (most severe)" ;
VAL_ 2566763776 FlashRedStopLamp 3 "Unavailable / Do Not Flash" 2 "Reserved" 1 "Fast Flash" 0 "Slow Flash" ;
VAL_ 2566763776 FlashProtectLamp 3 "Unavailable / Do Not Flash" 2 "Reserved" 1 "Fast Flash" 0 "Slow Flash" ;
VAL_ 2566763776 FlashMalfuncIndicatorLamp 3 "Unavailable / Do Not Flash" 2 "Class C DTC  " 1 "Fast Flash" 0 "Slow Flash" ;
VAL_ 2566763776 FlashAmberWarningLamp 3 "Unavailable / Do Not Flash" 2 "Reserved" 1 "Fast Flash" 0 "Slow Flash" ;
VAL_ 2566763776 MalfunctionIndLampStatus 3 "Not available" 2 "Short MIL for WWH OBD" 1 "Lamp On" 0 "Lamp Off" ;
VAL_ 2566763776 AmberWarningLampStatus 3 "Not available" 2 "Reserved" 1 "Lamp On" 0 "Lamp Off" ;
VAL_ 2566763776 RedStopLampState 3 "Not available" 2 "Reserved" 1 "Lamp On" 0 "Lamp Off" ;
VAL_ 2566763776 ProtectLampStatus 0 "Lamp Off" 3 "Not available" 2 "Reserved" 1 "Lamp On" ;
VAL_ 2365213438 ControllerIdType 2 "Causal CA followed by the impaired CA identity" 1 "Impaired CA identity" 0 "Causal CA identity" ;
VAL_ 2365213438 DtcType 255 "Not Available" 20 "DM54" 19 "DM53" 18 "DM52" 17 "DM51" 16 "DM50" 15 "DM49" 14 "DM48" 13 "DM47" 12 "DM46" 11 "DM45" 10 "DM44" 9 "DM43" 8 "DM42" 7 "DM41" 6 "DM28" 5 "DM27" 4 "DM23" 3 "DM12" 2 "DM6" 1 "DM2" 0 "DM1" ;
VAL_ 2365213438 FMI 24 "Assurance Data Error" 23 "Request DM60 for more info" 22 "Special Instructions #2 " 21 "Data drifted low" 20 "Data drifted high" 31 "Condition exists" 19 "Received network data in error" 18 "Below normal (moderately severe)" 17 "Below normal (least severe)" 16 "Above normal (moderately severe)" 15 "Above normal (least severe)" 14 "Special intstructions" 13 "Out of calibration" 12 "Bad intelligent device" 11 "Root cause not known" 10 "Abnormal rate of change" 9 "Abnormal update rate" 8 "Abnormal frequency" 7 "Mechanical system not responding" 6 "Current above normal" 5 "Current below normal" 4 "Voltage below normal" 3 "Voltage above normal" 2 "Data erratic" 1 "Below normal (most severe)" 0 "Above normal (most severe)" ;
VAL_ 2365316094 TestIdentifier 248 "Command manufacturer specific test " 246 "Return all scaled test results for all SPNs" 245 "Return rationality fault SP data value " 250 "Return last measured scaled results" 249 "Command Standard Test" 247 "Return all scaled test results for one SPN" ;
VAL_ 2566702846 EngOBDWarmUpSequence 3 "Not supported or not available" 2 "SAE reserved" 1 "A warm-up cycle has occurred on this engine start" 0 "A warm-up cycle has not occurred on this engine start" ;
